VERSION ""

NS_ :

BS_:

BU_: FCM

BO_ 775 FCM_2: 8 FCM
 SG_ HMA_Status : 2|3@0+ (1,0) [0|7] ""  Vector__XXX
 SG_ HMA_HighbeamReq : 3|1@0+ (1,0) [0|1] ""  Vector__XXX
 SG_ FCM_2_Resd1 : 5|2@0+ (1,0) [0|1] ""  Vector__XXX
 SG_ LDW_ELK_TJA_LDPLeftVisuali : 7|2@0+ (1,0) [0|3] ""  Vector__XXX
 SG_ LDW_ELK_TJA_LDPRightVisuali : 15|2@0+ (1,0) [0|3] ""  Vector__XXX
 SG_ FCM_2_ISAState : 13|3@0+ (1,0) [0|7] ""  Vector__XXX
 SG_ FCM_2_Resd3 : 10|2@0+ (1,0) [0|1] ""  Vector__XXX
 SG_ FCM_2_Resd4 : 8|2@0+ (1,0) [0|1] ""  Vector__XXX
 SG_ FCM_2_SCFSpdlimWarn : 22|1@0+ (1,0) [0|1] ""  Vector__XXX
 SG_ SLAState : 21|3@0+ (1,0) [0|7] ""  Vector__XXX
 SG_ SLASpdlimit : 18|8@0+ (1,0) [0|255] ""  Vector__XXX
 SG_ FCM_2_Resd6 : 26|2@0+ (1,0) [0|1] ""  Vector__XXX
 SG_ SLASpdlimitWarning : 24|1@0+ (1,0) [0|1] ""  Vector__XXX
 SG_ Camera_textinfo : 39|2@0+ (1,0) [0|3] ""  Vector__XXX
 SG_ FCM_2_Resd13 : 37|1@0+ (1,0) [0|1] ""  Vector__XXX
 SG_ FCM_2_SpdLimtyp : 36|2@0+ (1,0) [0|3] ""  Vector__XXX
 SG_ FCM_2_Resd8 : 34|3@0+ (1,0) [0|1] ""  Vector__XXX
 SG_ TJA_ICA_mode : 47|3@0+ (1,0) [0|4] ""  Vector__XXX
 SG_ FCM_2_SLASpdLimChgAud : 44|1@0+ (1,0) [0|1] ""  Vector__XXX
 SG_ FCM_2_SLASpdlimitUnits : 41|2@0+ (1,0) [0|3] ""  Vector__XXX
 SG_ FCM_2_TJATakeoverReq : 43|2@0+ (1,0) [0|3] ""  Vector__XXX
 SG_ SLASpdlimitUnknownWarning : 53|2@0+ (1,0) [0|3] ""  Vector__XXX
 SG_ SLASpdlimitWarningVis : 54|1@0+ (1,0) [0|1] ""  Vector__XXX
 SG_ SLASpdlimitWarningAud : 55|1@0+ (1,0) [0|1] ""  Vector__XXX
 SG_ FCM_2_MessageCounter : 51|4@0+ (1,0) [0|15] ""  Vector__XXX
 SG_ FCM_2_CRC : 63|8@0+ (1,0) [0|255] ""  Vector__XXX

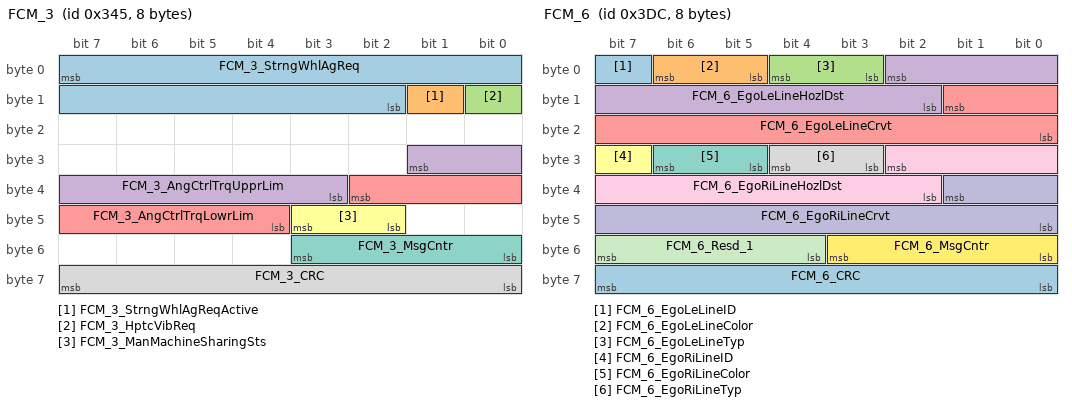
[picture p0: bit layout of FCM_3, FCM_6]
BO_ 837 FCM_3: 8 FCM
 SG_ FCM_3_StrngWhlAgReq : 7|14@0+ (0.1,-780) [-780|780] "deg"  Vector__XXX
 SG_ FCM_3_StrngWhlAgReqActive : 9|1@0+ (1,0) [0|1] ""  Vector__XXX
 SG_ FCM_3_HptcVibReq : 8|1@0+ (1,0) [0|1] ""  Vector__XXX
 SG_ FCM_3_AngCtrlTrqUpprLim : 25|7@0+ (0.1,0) [0|10] "NM"  Vector__XXX
 SG_ FCM_3_AngCtrlTrqLowrLim : 34|7@0+ (0.1,-10) [-10|0] "NM"  Vector__XXX
 SG_ FCM_3_ManMachineSharingSts : 43|2@0+ (1,0) [0|3] ""  Vector__XXX
 SG_ FCM_3_MsgCntr : 51|4@0+ (1,0) [0|15] ""  Vector__XXX
 SG_ FCM_3_CRC : 63|8@0+ (1,0) [0|255] ""  Vector__XXX

BO_ 1245 FCM_5: 8 FCM
 SG_ FCM_5_TJAICAExitTextInfoSts : 7|2@0+ (1,0) [0|3] ""  Vector__XXX
 SG_ FCM_5_SLAONOFFSts : 5|2@0+ (1,0) [0|3] ""  Vector__XXX
 SG_ FCM_5_IESONOFFSts : 3|2@0+ (1,0) [0|3] ""  Vector__XXX
 SG_ FCM_5_HMAONOFFSts : 1|2@0+ (1,0) [0|3] ""  Vector__XXX
 SG_ FCM_5_TSIONOFFSts : 15|2@0+ (1,0) [0|3] ""  Vector__XXX
 SG_ FCM_5_TLIONOFFSts : 13|2@0+ (1,0) [0|3] ""  Vector__XXX
 SG_ FCM_5_LDWONOFFSts : 11|2@0+ (1,0) [0|3] ""  Vector__XXX
 SG_ FCM_5_WarnModSts : 9|2@0+ (1,0) [0|3] ""  Vector__XXX
 SG_ FCM_5_LDPONOFFSts : 23|2@0+ (1,0) [0|3] ""  Vector__XXX
 SG_ FCM_5_LDWLDPSnvtySts : 21|2@0+ (1,0) [0|3] ""  Vector__XXX
 SG_ FCM_5_ELKONOFFSts : 19|2@0+ (1,0) [0|3] ""  Vector__XXX
 SG_ SLWFONOFFSts : 17|2@0+ (1,0) [0|3] ""  Vector__XXX
 SG_ SLASpdlimitWarningAudSWSts : 31|2@0+ (1,0) [0|3] ""  Vector__XXX
 SG_ SLASpdLimChgAudSwSts : 29|2@0+ (1,0) [0|3] ""  Vector__XXX
 SG_ FCM_5_SpeedLmtNmberAb : 27|6@0+ (1,0) [0|63] ""  Vector__XXX
 SG_ FCM_5_SpeedLmtNmberE : 37|6@0+ (1,0) [0|63] ""  Vector__XXX
 SG_ FCM_5_SLAmodeSWSet : 47|2@0+ (1,0) [0|3] ""  Vector__XXX
 SG_ FCM_5_Resd_1 : 45|10@0+ (1,0) [0|0] ""  Vector__XXX
 SG_ FCM_5_MsgCntr : 51|4@0+ (1,0) [0|15] ""  Vector__XXX
 SG_ FCM_5_CRC : 63|8@0+ (1,0) [0|255] ""  Vector__XXX

BO_ 988 FCM_6: 8 FCM
 SG_ FCM_6_EgoLeLineID : 7|1@0+ (1,0) [0|1] ""  Vector__XXX
 SG_ FCM_6_EgoLeLineColor : 6|2@0+ (1,0) [0|3] ""  Vector__XXX
 SG_ FCM_6_EgoLeLineTyp : 4|2@0+ (1,0) [0|3] ""  Vector__XXX
 SG_ FCM_6_EgoLeLineHozlDst : 2|9@0+ (0.1,-25) [-25|25] "m"  Vector__XXX
 SG_ FCM_6_EgoLeLineCrvt : 9|10@0+ (0.00006,-0.0156) [-0.0156|0.0156] "1/m"  Vector__XXX
 SG_ FCM_6_EgoRiLineID : 31|1@0+ (1,0) [0|1] ""  Vector__XXX
 SG_ FCM_6_EgoRiLineColor : 30|2@0+ (1,0) [0|3] ""  Vector__XXX
 SG_ FCM_6_EgoRiLineTyp : 28|2@0+ (1,0) [0|3] ""  Vector__XXX
 SG_ FCM_6_EgoRiLineHozlDst : 26|9@0+ (0.1,-25) [-25|25] "m"  Vector__XXX
 SG_ FCM_6_EgoRiLineCrvt : 33|10@0+ (0.00006,-0.0156) [-0.0156|0.0156] "1/m"  Vector__XXX
 SG_ FCM_6_Resd_1 : 55|4@0+ (1,0) [0|1] ""  Vector__XXX
 SG_ FCM_6_MsgCntr : 51|4@0+ (1,0) [0|15] ""  Vector__XXX
 SG_ FCM_6_CRC : 63|8@0+ (1,0) [0|255] ""  Vector__XXX

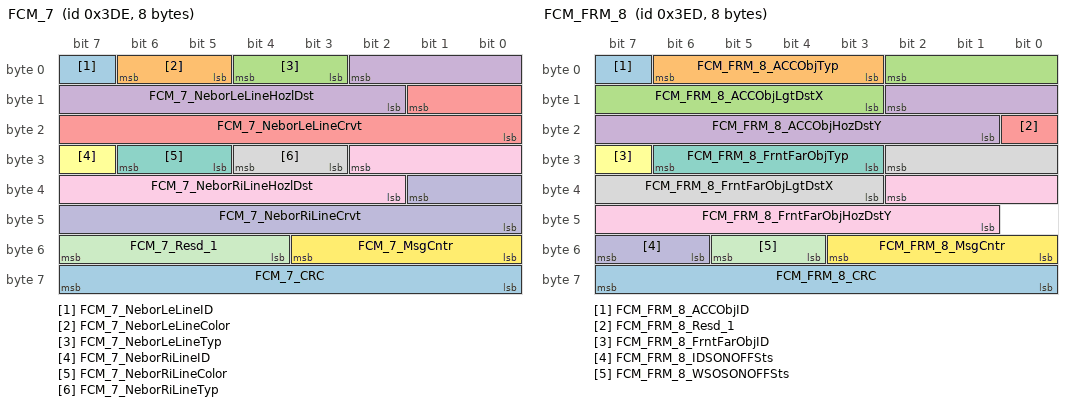
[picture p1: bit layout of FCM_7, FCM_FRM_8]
BO_ 990 FCM_7: 8 FCM
 SG_ FCM_7_NeborLeLineID : 7|1@0+ (1,0) [0|1] ""  Vector__XXX
 SG_ FCM_7_NeborLeLineColor : 6|2@0+ (1,0) [0|3] ""  Vector__XXX
 SG_ FCM_7_NeborLeLineTyp : 4|2@0+ (1,0) [0|3] ""  Vector__XXX
 SG_ FCM_7_NeborLeLineHozlDst : 2|9@0+ (0.1,-25) [-25|25] "m"  Vector__XXX
 SG_ FCM_7_NeborLeLineCrvt : 9|10@0+ (0.00006,-0.0156) [-0.0156|0.0156] "1/m"  Vector__XXX
 SG_ FCM_7_NeborRiLineID : 31|1@0+ (1,0) [0|1] ""  Vector__XXX
 SG_ FCM_7_NeborRiLineColor : 30|2@0+ (1,0) [0|3] ""  Vector__XXX
 SG_ FCM_7_NeborRiLineTyp : 28|2@0+ (1,0) [0|3] ""  Vector__XXX
 SG_ FCM_7_NeborRiLineHozlDst : 26|9@0+ (0.1,-25) [-25|25] "m"  Vector__XXX
 SG_ FCM_7_NeborRiLineCrvt : 33|10@0+ (0.00006,-0.0156) [-0.0156|0.0156] "1/m"  Vector__XXX
 SG_ FCM_7_Resd_1 : 55|4@0+ (1,0) [0|1] ""  Vector__XXX
 SG_ FCM_7_MsgCntr : 51|4@0+ (1,0) [0|15] ""  Vector__XXX
 SG_ FCM_7_CRC : 63|8@0+ (1,0) [0|255] ""  Vector__XXX

BO_ 1005 FCM_FRM_8: 8 FCM
 SG_ FCM_FRM_8_ACCObjID : 7|1@0+ (1,0) [0|1] ""  Vector__XXX
 SG_ FCM_FRM_8_ACCObjTyp : 6|4@0+ (1,0) [0|15] ""  Vector__XXX
 SG_ FCM_FRM_8_ACCObjLgtDstX : 2|8@0+ (0.5,0) [0|127] "m"  Vector__XXX
 SG_ FCM_FRM_8_ACCObjHozDstY : 10|10@0+ (0.1,-50) [-50|50] "m"  Vector__XXX
 SG_ FCM_FRM_8_Resd_1 : 16|1@0+ (1,0) [0|1] ""  Vector__XXX
 SG_ FCM_FRM_8_FrntFarObjID : 31|1@0+ (1,0) [0|1] ""  Vector__XXX
 SG_ FCM_FRM_8_FrntFarObjTyp : 30|4@0+ (1,0) [0|15] ""  Vector__XXX
 SG_ FCM_FRM_8_FrntFarObjLgtDstX : 26|8@0+ (0.5,0) [0|127] "m"  Vector__XXX
 SG_ FCM_FRM_8_FrntFarObjHozDstY : 34|10@0+ (0.1,-50) [-50|50] "m"  Vector__XXX
 SG_ FCM_FRM_8_IDSONOFFSts : 55|2@0+ (1,0) [0|3] ""  Vector__XXX
 SG_ FCM_FRM_8_WSOSONOFFSts : 53|2@0+ (1,0) [0|3] ""  Vector__XXX
 SG_ FCM_FRM_8_MsgCntr : 51|4@0+ (1,0) [0|15] ""  Vector__XXX
 SG_ FCM_FRM_8_CRC : 63|8@0+ (1,0) [0|255] ""  Vector__XXX

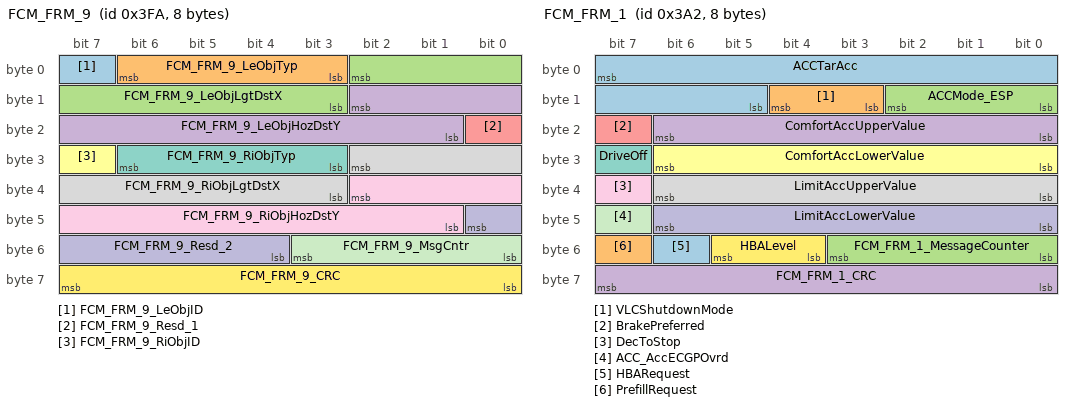
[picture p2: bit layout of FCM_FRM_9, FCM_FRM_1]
BO_ 1018 FCM_FRM_9: 8 FCM
 SG_ FCM_FRM_9_LeObjID : 7|1@0+ (1,0) [0|1] ""  Vector__XXX
 SG_ FCM_FRM_9_LeObjTyp : 6|4@0+ (1,0) [0|15] ""  Vector__XXX
 SG_ FCM_FRM_9_LeObjLgtDstX : 2|8@0+ (0.5,0) [0|127] "m"  Vector__XXX
 SG_ FCM_FRM_9_LeObjHozDstY : 10|10@0+ (0.1,-50) [-50|50] "m"  Vector__XXX
 SG_ FCM_FRM_9_Resd_1 : 16|1@0+ (1,0) [0|1] ""  Vector__XXX
 SG_ FCM_FRM_9_RiObjID : 31|1@0+ (1,0) [0|1] ""  Vector__XXX
 SG_ FCM_FRM_9_RiObjTyp : 30|4@0+ (1,0) [0|15] ""  Vector__XXX
 SG_ FCM_FRM_9_RiObjLgtDstX : 26|8@0+ (0.5,0) [0|127] "m"  Vector__XXX
 SG_ FCM_FRM_9_RiObjHozDstY : 34|10@0+ (0.1,-50) [-50|50] "m"  Vector__XXX
 SG_ FCM_FRM_9_Resd_2 : 40|5@0+ (1,0) [0|1] ""  Vector__XXX
 SG_ FCM_FRM_9_MsgCntr : 51|4@0+ (1,0) [0|15] ""  Vector__XXX
 SG_ FCM_FRM_9_CRC : 63|8@0+ (1,0) [0|255] ""  Vector__XXX

BO_ 1020 FCM_10: 8 FCM
 SG_ FCM_10_TSISysSts : 7|2@0+ (1,0) [0|3] ""  Vector__XXX
 SG_ FCM_10_TLISysSts : 5|2@0+ (1,0) [0|3] ""  Vector__XXX
 SG_ FCM_10_TSISgnGiWay : 3|4@0+ (1,0) [0|15] ""  Vector__XXX
 SG_ FCM_10_TSISgnForb : 15|4@0+ (1,0) [0|15] ""  Vector__XXX
 SG_ FCM_10_TSISgnLongStayDisp : 11|4@0+ (1,0) [0|15] ""  Vector__XXX
 SG_ FCM_10_TLITrfcLi : 23|2@0+ (1,0) [0|3] ""  Vector__XXX
 SG_ FCM_10_LDPSysSts : 21|3@0+ (1,0) [0|7] ""  Vector__XXX
 SG_ FCM_10_LDWSysSts : 18|3@0+ (1,0) [0|7] ""  Vector__XXX
 SG_ FCM_10_ELKSysSts : 31|3@0+ (1,0) [0|7] ""  Vector__XXX
 SG_ FCM_10_TSINoParkWarn : 28|1@0+ (1,0) [0|1] ""  Vector__XXX
 SG_ FCM_10_TJAICATextinfo : 27|3@0+ (1,0) [0|7] ""  Vector__XXX
 SG_ FCM_10_TJAICAEnaRcmend : 24|1@0+ (1,0) [0|1] ""  Vector__XXX
 SG_ FCM_10_LDPTJAELKTakeoverReq : 39|2@0+ (1,0) [0|3] ""  Vector__XXX
 SG_ FCM_10_TJAICAExitTextInfoSts : 37|2@0+ (1,0) [0|3] ""  Vector__XXX
 SG_ FCM_10_SLAONOFFSts : 35|2@0+ (1,0) [0|3] ""  Vector__XXX
 SG_ FCM_10_WarnModSts : 33|2@0+ (1,0) [0|3] ""  Vector__XXX
 SG_ FCM_10_ELKIntvMod : 47|3@0+ (1,0) [0|7] ""  Vector__XXX
 SG_ FCM_10_EgoLeftLineHeatgAg : 44|9@0+ (0.004,-1.02) [-1.02|1.02] "Rad"  Vector__XXX
 SG_ FCM_10_MsgCntr : 51|4@0+ (1,0) [0|15] ""  Vector__XXX
 SG_ FCM_10_CRC : 63|8@0+ (1,0) [0|255] ""  Vector__XXX

BO_ 930 FCM_FRM_1: 8 FCM
 SG_ ACCTarAcc : 7|11@0+ (0.005,-5) [-5|5.235] "m/s2"  Vector__XXX
 SG_ VLCShutdownMode : 12|2@0+ (1,0) [0|3] ""  Vector__XXX
 SG_ ACCMode_ESP : 10|3@0+ (1,0) [0|7] ""  Vector__XXX
 SG_ ComfortAccUpperValue : 22|7@0+ (0.025,0) [0|3.125] "m/s2"  Vector__XXX
 SG_ BrakePreferred : 23|1@0+ (1,0) [0|1] ""  Vector__XXX
 SG_ ComfortAccLowerValue : 30|7@0+ (0.025,0) [0|3.125] "m/s2"  Vector__XXX
 SG_ DriveOff : 31|1@0+ (1,0) [0|1] ""  Vector__XXX
 SG_ LimitAccUpperValue : 38|7@0+ (0.1,0) [0|12.7] "m/s3"  Vector__XXX
 SG_ DecToStop : 39|1@0+ (1,0) [0|1] ""  Vector__XXX
 SG_ LimitAccLowerValue : 46|7@0+ (0.1,-12.7) [-12.7|0] "m/s3"  Vector__XXX
 SG_ ACC_AccECGPOvrd : 47|1@0+ (1,0) [0|1] ""  Vector__XXX
 SG_ HBALevel : 53|2@0+ (1,0) [0|3] ""  Vector__XXX
 SG_ HBARequest : 54|1@0+ (1,0) [0|1] ""  Vector__XXX
 SG_ PrefillRequest : 55|1@0+ (1,0) [0|1] ""  Vector__XXX
 SG_ FCM_FRM_1_MessageCounter : 51|4@0+ (1,0) [0|15] ""  Vector__XXX
 SG_ FCM_FRM_1_CRC : 63|8@0+ (1,0) [0|255] ""  Vector__XXX

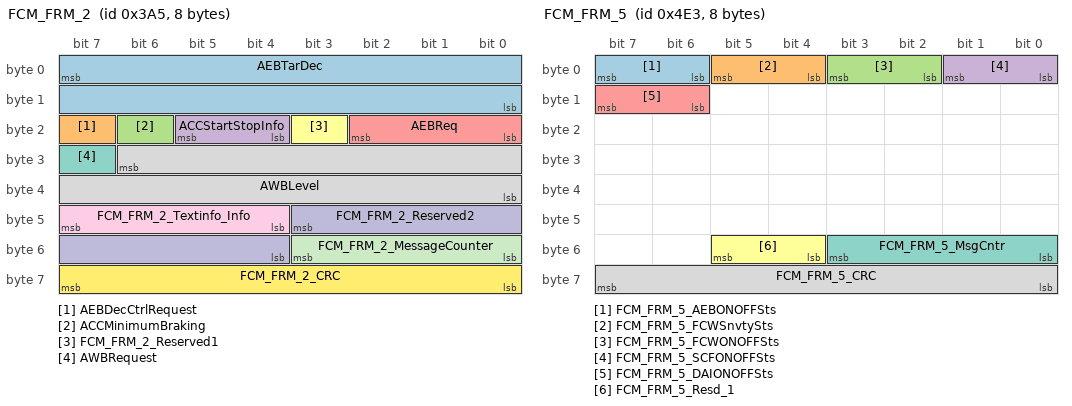
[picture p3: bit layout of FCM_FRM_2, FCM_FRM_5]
BO_ 933 FCM_FRM_2: 8 FCM
 SG_ AEBTarDec : 7|16@0+ (0.0004882,-16) [-16|15] ""  Vector__XXX
 SG_ AEBDecCtrlRequest : 23|1@0+ (1,0) [0|1] ""  Vector__XXX
 SG_ ACCMinimumBraking : 22|1@0+ (1,0) [0|1] ""  Vector__XXX
 SG_ ACCStartStopInfo : 21|2@0+ (1,0) [0|3] ""  Vector__XXX
 SG_ AEBReq : 18|3@0+ (1,0) [0|7] ""  Vector__XXX
 SG_ FCM_FRM_2_Reserved1 : 19|1@0+ (1,0) [0|1] ""  Vector__XXX
 SG_ AWBRequest : 31|1@0+ (1,0) [0|1] ""  Vector__XXX
 SG_ AWBLevel : 30|15@0+ (1,0) [0|15] ""  Vector__XXX
 SG_ FCM_FRM_2_Textinfo_Info : 47|4@0+ (1,0) [0|15] ""  Vector__XXX
 SG_ FCM_FRM_2_Reserved2 : 43|8@0+ (1,0) [0|1] ""  Vector__XXX
 SG_ FCM_FRM_2_MessageCounter : 51|4@0+ (1,0) [0|15] ""  Vector__XXX
 SG_ FCM_FRM_2_CRC : 63|8@0+ (1,0) [0|255] ""  Vector__XXX

BO_ 773 FCM_FRM_3: 8 FCM
 SG_ FCM_FRM_3_Resd1 : 7|9@0+ (1,0) [0|1] ""  Vector__XXX
 SG_ FCM_FRM_3_Resd2 : 14|3@0+ (1,0) [0|1] ""  Vector__XXX
 SG_ FCM_FRM_3_Resd3 : 11|3@0+ (1,0) [0|1] ""  Vector__XXX
 SG_ FCM_FRM_3_Resd4 : 8|1@0+ (1,0) [0|1] ""  Vector__XXX
 SG_ Textinfo : 23|5@0+ (1,0) [0|31] ""  Vector__XXX
 SG_ FCM_FRM_3_Resd6 : 18|1@0+ (1,0) [0|1] ""  Vector__XXX
 SG_ FCM_FRM_3_Resd7 : 31|2@0+ (1,0) [0|1] ""  Vector__XXX
 SG_ FCM_FRM_3_Resd8 : 17|2@0+ (1,0) [0|1] ""  Vector__XXX
 SG_ FCM_FRM_3_Resd9 : 29|8@0+ (1,0) [0|1] ""  Vector__XXX
 SG_ ACCModeDummy : 37|4@0+ (1,0) [0|15] ""  Vector__XXX
 SG_ FCM_FRM_3_Resd10 : 33|3@0+ (1,0) [0|1] ""  Vector__XXX
 SG_ FCM_FRM_3_Resd11 : 46|3@0+ (1,0) [0|1] ""  Vector__XXX
 SG_ FCM_FRM_3_Resd12 : 43|1@0+ (1,0) [0|1] ""  Vector__XXX
 SG_ FCM_FRM_3_Resd13 : 42|1@0+ (1,0) [0|1] ""  Vector__XXX
 SG_ FCM_FRM_3_Resd14 : 41|1@0+ (1,0) [0|1] ""  Vector__XXX
 SG_ FCM_FRM_3_Resd15 : 40|1@0+ (1,0) [0|1] ""  Vector__XXX
 SG_ FCM_FRM_3_Resd16 : 55|2@0+ (1,0) [0|1] ""  Vector__XXX
 SG_ FCM_FRM_3_Resd17 : 53|1@0+ (1,0) [0|1] ""  Vector__XXX
 SG_ FCM_FRM_3_Resd18 : 52|1@0+ (1,0) [0|1] ""  Vector__XXX
 SG_ FCM_FRM_3_MessageCounter : 51|4@0+ (1,0) [0|15] ""  Vector__XXX
 SG_ FCM_FRM_3_CRC : 63|8@0+ (1,0) [0|255] ""  Vector__XXX

BO_ 1251 FCM_FRM_5: 8 FCM
 SG_ FCM_FRM_5_AEBONOFFSts : 7|2@0+ (1,0) [0|3] ""  Vector__XXX
 SG_ FCM_FRM_5_FCWSnvtySts : 5|2@0+ (1,0) [0|3] ""  Vector__XXX
 SG_ FCM_FRM_5_FCWONOFFSts : 3|2@0+ (1,0) [0|3] ""  Vector__XXX
 SG_ FCM_FRM_5_SCFONOFFSts : 1|2@0+ (1,0) [0|3] ""  Vector__XXX
 SG_ FCM_FRM_5_DAIONOFFSts : 15|2@0+ (1,0) [0|3] ""  Vector__XXX
 SG_ FCM_FRM_5_Resd_1 : 53|2@0+ (1,0) [0|1] ""  Vector__XXX
 SG_ FCM_FRM_5_MsgCntr : 51|4@0+ (1,0) [0|15] ""  Vector__XXX
 SG_ FCM_FRM_5_CRC : 63|8@0+ (1,0) [0|255] ""  Vector__XXX

BO_ 903 FCM_FRM_6: 8 FCM
 SG_ FCM_FRM_6_Textinfo_Info : 7|4@0+ (1,0) [0|15] ""  Vector__XXX
 SG_ FCM_FRM_6_TextinfoWarn : 3|4@0+ (1,0) [0|15] ""  Vector__XXX
 SG_ FCM_FRM_6_Textinfo_Info_2 : 15|4@0+ (1,0) [0|15] ""  Vector__XXX
 SG_ FCM_FRM_6_TimeGapSetICM : 11|3@0+ (1,0) [0|7] ""  Vector__XXX
 SG_ FCM_FRM_6_SCF_PopoverReq : 8|1@0+ (1,0) [0|1] ""  Vector__XXX
 SG_ FCM_FRM_6_SCF_SpdLimSts : 23|3@0+ (1,0) [0|7] ""  Vector__XXX
 SG_ FCM_FRM_6_SCF_SpdLimUnit : 20|2@0+ (1,0) [0|3] ""  Vector__XXX
 SG_ FCM_FRM_6_DrvrCfmSCFDispFb : 18|1@0+ (1,0) [0|1] ""  Vector__XXX
 SG_ FCM_FRM_6_DistanceWarning : 17|1@0+ (1,0) [0|1] ""  Vector__XXX
 SG_ FCM_FRM_6_FCW_preWarning : 16|1@0+ (1,0) [0|1] ""  Vector__XXX
 SG_ FCM_FRM_6_TakeOverReq : 31|1@0+ (1,0) [0|1] ""  Vector__XXX
 SG_ FCM_FRM_6_FCWMode : 30|3@0+ (1,0) [0|4] ""  Vector__XXX
 SG_ FCM_FRM_6_AEBMode : 27|3@0+ (1,0) [0|4] ""  Vector__XXX
 SG_ FCM_FRM_6_AEBDecCtrlRequest : 24|1@0+ (1,0) [0|1] ""  Vector__XXX
 SG_ FCM_FRM_6_HMI_Indicator : 39|2@0+ (1,0) [0|3] ""  Vector__XXX
 SG_ FCM_FRM_6_ACCMode : 37|4@0+ (1,0) [0|15] ""  Vector__XXX
 SG_ FCM_FRM_6_SCF_Indicator : 33|2@0+ (1,0) [0|3] ""  Vector__XXX
 SG_ FCM_FRM_6_VSetDis : 44|9@0+ (0.5,0) [0|255.5] "KPH"  Vector__XXX
 SG_ FCM_FRM_6_MsgCntr : 51|4@0+ (1,0) [0|15] ""  Vector__XXX
 SG_ FCM_FRM_6_CRC : 63|8@0+ (1,0) [0|255] ""  Vector__XXX

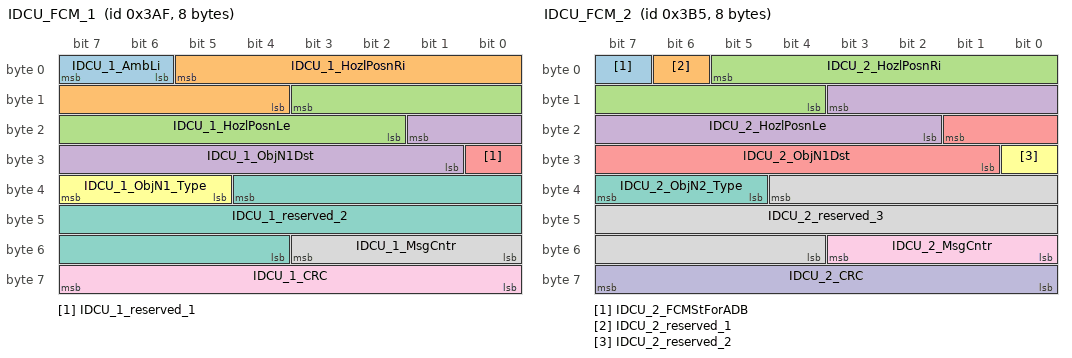
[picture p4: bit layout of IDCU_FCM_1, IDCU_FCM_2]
BO_ 943 IDCU_FCM_1: 8 FCM
 SG_ IDCU_1_AmbLi : 7|2@0+ (1,0) [0|3] ""  Vector__XXX
 SG_ IDCU_1_HozlPosnRi : 5|10@0+ (0.05,-21.5) [-21.5|21.5] "°"  Vector__XXX
 SG_ IDCU_1_HozlPosnLe : 11|10@0+ (0.05,-21.5) [-21.5|21.5] "°"  Vector__XXX
 SG_ IDCU_1_ObjN1Dst : 17|9@0+ (1,0) [0|400] "m"  Vector__XXX
 SG_ IDCU_1_reserved_1 : 24|1@0+ (1,0) [0|1] ""  Vector__XXX
 SG_ IDCU_1_ObjN1_Type : 39|3@0+ (1,0) [0|7] ""  Vector__XXX
 SG_ IDCU_1_reserved_2 : 36|17@0+ (1,0) [0|1] ""  Vector__XXX
 SG_ IDCU_1_MsgCntr : 51|4@0+ (1,0) [0|15] ""  Vector__XXX
 SG_ IDCU_1_CRC : 63|8@0+ (1,0) [0|255] ""  Vector__XXX

BO_ 949 IDCU_FCM_2: 8 FCM
 SG_ IDCU_2_FCMStForADB : 7|1@0+ (1,0) [0|1] ""  Vector__XXX
 SG_ IDCU_2_reserved_1 : 6|1@0+ (1,0) [0|1] ""  Vector__XXX
 SG_ IDCU_2_HozlPosnRi : 5|10@0+ (0.05,-21.5) [-21.5|21.5] "°"  Vector__XXX
 SG_ IDCU_2_HozlPosnLe : 11|10@0+ (0.05,-21.5) [-21.5|21.5] "°"  Vector__XXX
 SG_ IDCU_2_ObjN1Dst : 17|9@0+ (1,0) [0|400] "m"  Vector__XXX
 SG_ IDCU_2_reserved_2 : 24|1@0+ (1,0) [0|1] ""  Vector__XXX
 SG_ IDCU_2_ObjN2_Type : 39|3@0+ (1,0) [0|0] ""  Vector__XXX
 SG_ IDCU_2_reserved_3 : 36|17@0+ (1,0) [0|0] ""  Vector__XXX
 SG_ IDCU_2_MsgCntr : 51|4@0+ (1,0) [0|15] ""  Vector__XXX
 SG_ IDCU_2_CRC : 63|8@0+ (1,0) [0|255] ""  Vector__XXX

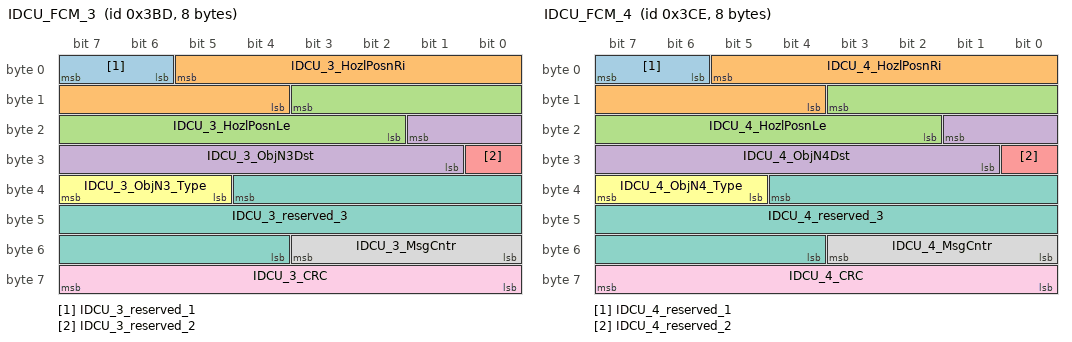
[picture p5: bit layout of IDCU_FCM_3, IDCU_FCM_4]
BO_ 957 IDCU_FCM_3: 8 FCM
 SG_ IDCU_3_reserved_1 : 7|2@0+ (1,0) [0|3] ""  Vector__XXX
 SG_ IDCU_3_HozlPosnRi : 5|10@0+ (0.05,-21.5) [-21.5|21.5] "°"  Vector__XXX
 SG_ IDCU_3_HozlPosnLe : 11|10@0+ (0.05,-21.5) [-21.5|21.5] "°"  Vector__XXX
 SG_ IDCU_3_ObjN3Dst : 17|9@0+ (1,0) [0|400] "m"  Vector__XXX
 SG_ IDCU_3_reserved_2 : 24|1@0+ (1,0) [0|1] ""  Vector__XXX
 SG_ IDCU_3_ObjN3_Type : 39|3@0+ (1,0) [0|7] ""  Vector__XXX
 SG_ IDCU_3_reserved_3 : 36|17@0+ (1,0) [0|0] ""  Vector__XXX
 SG_ IDCU_3_MsgCntr : 51|4@0+ (1,0) [0|15] ""  Vector__XXX
 SG_ IDCU_3_CRC : 63|8@0+ (1,0) [0|255] ""  Vector__XXX

BO_ 974 IDCU_FCM_4: 8 FCM
 SG_ IDCU_4_reserved_1 : 7|2@0+ (1,0) [0|3] ""  Vector__XXX
 SG_ IDCU_4_HozlPosnRi : 5|10@0+ (0.05,-21.5) [-21.5|21.5] "°"  Vector__XXX
 SG_ IDCU_4_HozlPosnLe : 11|10@0+ (0.05,-21.5) [-21.5|21.5] "°"  Vector__XXX
 SG_ IDCU_4_ObjN4Dst : 17|9@0+ (1,0) [0|400] "m"  Vector__XXX
 SG_ IDCU_4_reserved_2 : 24|1@0+ (1,0) [0|1] ""  Vector__XXX
 SG_ IDCU_4_ObjN4_Type : 39|3@0+ (1,0) [0|7] ""  Vector__XXX
 SG_ IDCU_4_reserved_3 : 36|17@0+ (1,0) [0|0] ""  Vector__XXX
 SG_ IDCU_4_MsgCntr : 51|4@0+ (1,0) [0|15] ""  Vector__XXX
 SG_ IDCU_4_CRC : 63|8@0+ (1,0) [0|255] ""  Vector__XXX

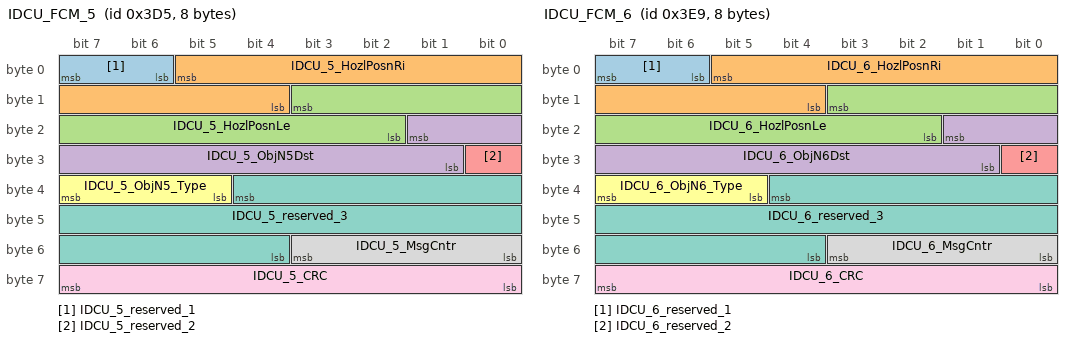
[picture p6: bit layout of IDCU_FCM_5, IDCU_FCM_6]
BO_ 981 IDCU_FCM_5: 8 FCM
 SG_ IDCU_5_reserved_1 : 7|2@0+ (1,0) [0|1] ""  Vector__XXX
 SG_ IDCU_5_HozlPosnRi : 5|10@0+ (0.05,-21.5) [-21.5|21.5] "°"  Vector__XXX
 SG_ IDCU_5_HozlPosnLe : 11|10@0+ (0.05,-21.5) [-21.5|21.5] "°"  Vector__XXX
 SG_ IDCU_5_ObjN5Dst : 17|9@0+ (1,0) [0|400] "m"  Vector__XXX
 SG_ IDCU_5_reserved_2 : 24|1@0+ (1,0) [0|1] ""  Vector__XXX
 SG_ IDCU_5_ObjN5_Type : 39|3@0+ (1,0) [0|7] ""  Vector__XXX
 SG_ IDCU_5_reserved_3 : 36|17@0+ (1,0) [0|0] ""  Vector__XXX
 SG_ IDCU_5_MsgCntr : 51|4@0+ (1,0) [0|15] ""  Vector__XXX
 SG_ IDCU_5_CRC : 63|8@0+ (1,0) [0|255] ""  Vector__XXX

BO_ 1001 IDCU_FCM_6: 8 FCM
 SG_ IDCU_6_reserved_1 : 7|2@0+ (1,0) [0|1] ""  Vector__XXX
 SG_ IDCU_6_HozlPosnRi : 5|10@0+ (0.05,-21.5) [-21.5|21.5] "°"  Vector__XXX
 SG_ IDCU_6_HozlPosnLe : 11|10@0+ (0.05,-21.5) [-21.5|21.5] "°"  Vector__XXX
 SG_ IDCU_6_ObjN6Dst : 17|9@0+ (1,0) [0|400] "m"  Vector__XXX
 SG_ IDCU_6_reserved_2 : 24|1@0+ (1,0) [0|1] ""  Vector__XXX
 SG_ IDCU_6_ObjN6_Type : 39|3@0+ (1,0) [0|7] ""  Vector__XXX
 SG_ IDCU_6_reserved_3 : 36|17@0+ (1,0) [0|0] ""  Vector__XXX
 SG_ IDCU_6_MsgCntr : 51|4@0+ (1,0) [0|15] ""  Vector__XXX
 SG_ IDCU_6_CRC : 63|8@0+ (1,0) [0|255] ""  Vector__XXX

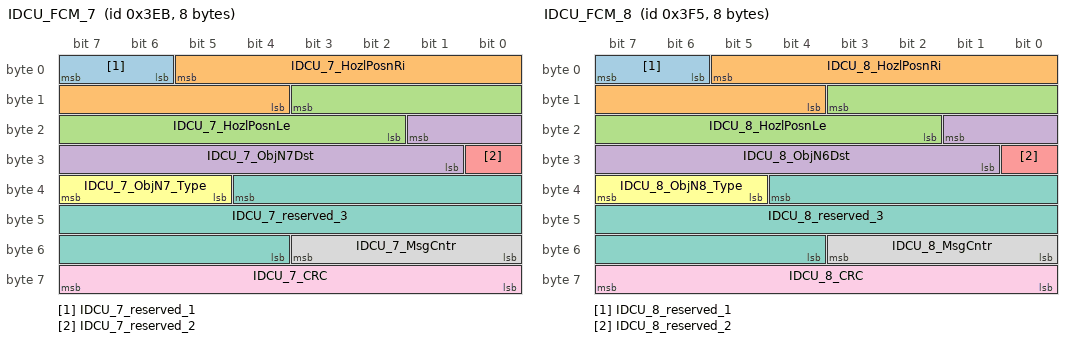
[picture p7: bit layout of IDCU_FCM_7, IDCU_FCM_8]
BO_ 1003 IDCU_FCM_7: 8 FCM
 SG_ IDCU_7_reserved_1 : 7|2@0+ (1,0) [0|1] ""  Vector__XXX
 SG_ IDCU_7_HozlPosnRi : 5|10@0+ (0.05,-21.5) [-21.5|21.5] "°"  Vector__XXX
 SG_ IDCU_7_HozlPosnLe : 11|10@0+ (0.05,-21.5) [-21.5|21.5] "°"  Vector__XXX
 SG_ IDCU_7_ObjN7Dst : 17|9@0+ (1,0) [0|400] "m"  Vector__XXX
 SG_ IDCU_7_reserved_2 : 24|1@0+ (1,0) [0|1] ""  Vector__XXX
 SG_ IDCU_7_ObjN7_Type : 39|3@0+ (1,0) [0|7] ""  Vector__XXX
 SG_ IDCU_7_reserved_3 : 36|17@0+ (1,0) [0|0] ""  Vector__XXX
 SG_ IDCU_7_MsgCntr : 51|4@0+ (1,0) [0|15] ""  Vector__XXX
 SG_ IDCU_7_CRC : 63|8@0+ (1,0) [0|255] ""  Vector__XXX

BO_ 1013 IDCU_FCM_8: 8 FCM
 SG_ IDCU_8_reserved_1 : 7|2@0+ (1,0) [0|1] ""  Vector__XXX
 SG_ IDCU_8_HozlPosnRi : 5|10@0+ (0.05,-21.5) [-21.5|21.5] "°"  Vector__XXX
 SG_ IDCU_8_HozlPosnLe : 11|10@0+ (0.05,-21.5) [-21.5|21.5] "°"  Vector__XXX
 SG_ IDCU_8_ObjN6Dst : 17|9@0+ (1,0) [0|400] "m"  Vector__XXX
 SG_ IDCU_8_reserved_2 : 24|1@0+ (1,0) [0|1] ""  Vector__XXX
 SG_ IDCU_8_ObjN8_Type : 39|3@0+ (1,0) [0|7] ""  Vector__XXX
 SG_ IDCU_8_reserved_3 : 36|17@0+ (1,0) [0|0] ""  Vector__XXX
 SG_ IDCU_8_MsgCntr : 51|4@0+ (1,0) [0|15] ""  Vector__XXX
 SG_ IDCU_8_CRC : 63|8@0+ (1,0) [0|255] ""  Vector__XXX

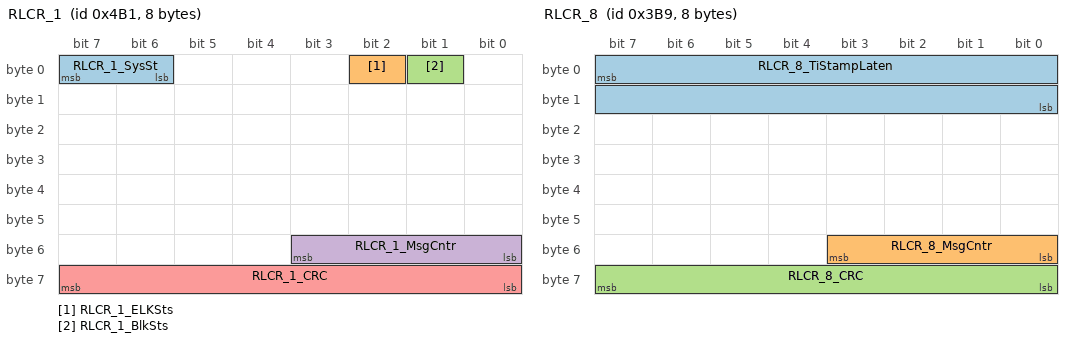
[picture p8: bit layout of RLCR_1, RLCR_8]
BO_ 1201 RLCR_1: 8 Vector__XXX
 SG_ RLCR_1_SysSt : 7|2@0+ (1,0) [0|3] ""  FCM
 SG_ RLCR_1_ELKSts : 2|1@0+ (1,0) [0|1] ""  FCM
 SG_ RLCR_1_BlkSts : 1|1@0+ (1,0) [0|1] ""  FCM
 SG_ RLCR_1_MsgCntr : 51|4@0+ (1,0) [0|15] ""  FCM
 SG_ RLCR_1_CRC : 63|8@0+ (1,0) [0|255] ""  FCM

BO_ 935 RLCR_3: 24 Vector__XXX
 SG_ RLCR_3_Le1ObjBoxLen : 7|9@0+ (0.1,0) [0|50] "m"  FCM
 SG_ RLCR_3_Le1ObjBoxWidth : 14|9@0+ (0.1,0) [0|50] "m"  FCM
 SG_ RLCR_3_Le1HdTo : 21|12@0+ (0.1,-180) [-180|180] "deg"  FCM
 SG_ RLCR_3_Le1ObjID : 25|8@0+ (1,0) [0|255] ""  FCM
 SG_ RLCR_3_Le1ObjCoordY : 33|13@0+ (0.05,-200) [-200|200] "m"  FCM
 SG_ RLCR_3_Le1ObjCoordX : 52|13@0+ (0.05,-200) [-200|200] "m"  FCM
 SG_ RLCR_3_Le1ObjXDirAV : 71|8@0+ (0.1,-12.8) [-12.8|12.7] "m/s2"  FCM
 SG_ RLCR_3_Le1ObjYDirV : 79|14@0+ (0.02,-128) [-128|128] "m/s"  FCM
 SG_ RLCR_3_Le1ObjXDirV : 81|14@0+ (0.02,-128) [-128|128] "m/s"  FCM
 SG_ RLCR_3_Le1ObjMtnChartc : 99|2@0+ (1,0) [0|3] ""  FCM
 SG_ RLCR_3_Le1ObjTyp : 97|2@0+ (1,0) [0|3] ""  FCM
 SG_ RLCR_3_Le1ObjConf : 111|1@0+ (1,0) [0|1] ""  FCM
 SG_ RLCR_3_Le1ObjNrOffocst : 110|5@0+ (1,0) [0|31] ""  FCM
 SG_ RLCR_3_Le1ObjTrackSt : 105|2@0+ (1,0) [0|3] ""  FCM
 SG_ RLCR_3_Le1ObjCoordXDstStdDe : 119|8@0+ (0.05,0) [0|12.7] ""  FCM
 SG_ RLCR_3_Le1ObjCoordYDstStdDe : 127|8@0+ (0.05,0) [0|12.7] ""  FCM
 SG_ RLCR_3_Le1ObjXDirVStdDe : 135|6@0+ (0.05,0) [0|2] ""  FCM
 SG_ RLCR_3_Le1ObjYDirVStdDe : 129|6@0+ (0.05,0) [0|2] ""  FCM
 SG_ RLCR_3_MsgCntr : 179|4@0+ (1,0) [0|15] ""  FCM
 SG_ RLCR_3_CRC : 191|8@0+ (1,0) [0|255] ""  FCM

BO_ 937 RLCR_4: 24 Vector__XXX
 SG_ RLCR_4_Le2ObjBoxLen : 7|9@0+ (0.1,0) [0|50] "m"  FCM
 SG_ RLCR_4_Le2ObjBoxWidth : 14|9@0+ (0.1,0) [0|50] "m"  FCM
 SG_ RLCR_4_Le2HdTo : 21|12@0+ (0.1,-180) [-180|180] "deg"  FCM
 SG_ RLCR_4_Le2ObjID : 25|8@0+ (1,0) [0|255] ""  FCM
 SG_ RLCR_4_Le2ObjCoordY : 33|13@0+ (0.05,-200) [-200|200] "m"  FCM
 SG_ RLCR_4_Le2ObjCoordX : 52|13@0+ (0.05,-200) [-200|200] "m"  FCM
 SG_ RLCR_4_Le2ObjXDirAV : 71|8@0+ (0.1,-12.8) [-12.8|12.7] "m/s2"  FCM
 SG_ RLCR_4_Le2ObjYDirV : 79|14@0+ (0.02,-128) [-128|128] "m/s"  FCM
 SG_ RLCR_4_Le2ObjXDirV : 81|14@0+ (0.02,-128) [-128|128] "m/s"  FCM
 SG_ RLCR_4_Le2ObjMtnChartc : 99|2@0+ (1,0) [0|3] ""  FCM
 SG_ RLCR_4_Le2ObjTyp : 97|2@0+ (1,0) [0|3] ""  FCM
 SG_ RLCR_4_Le2ObjConf : 111|1@0+ (1,0) [0|1] ""  FCM
 SG_ RLCR_4_Le2ObjNrOffocst : 110|5@0+ (1,0) [0|31] ""  FCM
 SG_ RLCR_4_Le2ObjTrackSt : 105|2@0+ (1,0) [0|3] ""  FCM
 SG_ RLCR_4_Le2ObjCoordXDstStdDe : 119|8@0+ (0.05,0) [0|12.7] ""  FCM
 SG_ RLCR_4_Le2ObjCoordYDstStdDe : 127|8@0+ (0.05,0) [0|12.7] ""  FCM
 SG_ RLCR_4_Le2ObjXDirVStdDe : 135|6@0+ (0.05,0) [0|2] ""  FCM
 SG_ RLCR_4_Le2ObjYDirVStdDe : 129|6@0+ (0.05,0) [0|2] ""  FCM
 SG_ RLCR_4_MsgCntr : 179|4@0+ (1,0) [0|15] ""  FCM
 SG_ RLCR_4_CRC : 191|8@0+ (1,0) [0|255] ""  FCM

BO_ 941 RLCR_5: 24 Vector__XXX
 SG_ RLCR_5_Le3ObjBoxLen : 7|9@0+ (0.1,0) [0|50] "m"  FCM
 SG_ RLCR_5_Le3ObjBoxWidth : 14|9@0+ (0.1,0) [0|50] "m"  FCM
 SG_ RLCR_5_Le3HdTo : 21|12@0+ (0.1,-180) [-180|180] "deg"  FCM
 SG_ RLCR_5_Le3ObjID : 25|8@0+ (1,0) [0|255] ""  FCM
 SG_ RLCR_5_Le3ObjCoordY : 33|13@0+ (0.05,-200) [-200|200] "m"  FCM
 SG_ RLCR_5_Le3ObjCoordX : 52|13@0+ (0.05,-200) [-200|200] "m"  FCM
 SG_ RLCR_5_Le3ObjXDirAV : 71|8@0+ (0.1,-12.8) [-12.8|12.7] "m/s2"  FCM
 SG_ RLCR_5_Le3ObjYDirV : 79|14@0+ (0.02,-128) [-128|128] "m/s"  FCM
 SG_ RLCR_5_Le3ObjXDirV : 81|14@0+ (0.02,-128) [-128|128] "m/s"  FCM
 SG_ RLCR_5_Le3ObjMtnChartc : 99|2@0+ (1,0) [0|3] ""  FCM
 SG_ RLCR_5_Le3ObjTyp : 97|2@0+ (1,0) [0|3] ""  FCM
 SG_ RLCR_5_Le3ObjConf : 111|1@0+ (1,0) [0|1] ""  FCM
 SG_ RLCR_5_Le3ObjNrOffocst : 110|5@0+ (1,0) [0|31] ""  FCM
 SG_ RLCR_5_Le3ObjTrackSt : 105|2@0+ (1,0) [0|3] ""  FCM
 SG_ RLCR_5_Le3ObjCoordXDstStdDe : 119|8@0+ (0.05,0) [0|12.7] ""  FCM
 SG_ RLCR_5_Le3ObjCoordYDstStdDe : 127|8@0+ (0.05,0) [0|12.7] ""  FCM
 SG_ RLCR_5_Le3ObjXDirVStdDe : 135|6@0+ (0.05,0) [0|2] ""  FCM
 SG_ RLCR_5_Le3ObjYDirVStdDe : 129|6@0+ (0.05,0) [0|2] ""  FCM
 SG_ RLCR_5_MsgCntr : 179|4@0+ (1,0) [0|15] ""  FCM
 SG_ RLCR_5_CRC : 191|8@0+ (1,0) [0|255] ""  FCM

BO_ 946 RLCR_6: 24 Vector__XXX
 SG_ RLCR_6_Le4ObjBoxLen : 7|9@0+ (0.1,0) [0|50] "m"  FCM
 SG_ RLCR_6_Le4ObjBoxWidth : 14|9@0+ (0.1,0) [0|50] "m"  FCM
 SG_ RLCR_6_Le4HdTo : 21|12@0+ (0.1,-180) [-180|180] "deg"  FCM
 SG_ RLCR_6_Le4ObjID : 25|8@0+ (1,0) [0|255] ""  FCM
 SG_ RLCR_6_Le4ObjCoordY : 33|13@0+ (0.05,-200) [-200|200] "m"  FCM
 SG_ RLCR_6_Le4ObjCoordX : 52|13@0+ (0.05,-200) [-200|200] "m"  FCM
 SG_ RLCR_6_Le4ObjXDirAV : 71|8@0+ (0.1,-12.8) [-12.8|12.7] "m/s2"  FCM
 SG_ RLCR_6_Le4ObjYDirV : 79|14@0+ (0.02,-128) [-128|128] "m/s"  FCM
 SG_ RLCR_6_Le4ObjXDirV : 81|14@0+ (0.02,-128) [-128|128] "m/s"  FCM
 SG_ RLCR_6_Le4ObjMtnChartc : 99|2@0+ (1,0) [0|3] ""  FCM
 SG_ RLCR_6_Le4ObjTyp : 97|2@0+ (1,0) [0|3] ""  FCM
 SG_ RLCR_6_Le4ObjConf : 111|1@0+ (1,0) [0|1] ""  FCM
 SG_ RLCR_6_Le4ObjNrOffocst : 110|5@0+ (1,0) [0|31] ""  FCM
 SG_ RLCR_6_Le4ObjTrackSt : 105|2@0+ (1,0) [0|3] ""  FCM
 SG_ RLCR_6_Le4ObjCoordXDstStdDe : 119|8@0+ (0.05,0) [0|12.7] ""  FCM
 SG_ RLCR_6_Le4ObjCoordYDstStdDe : 127|8@0+ (0.05,0) [0|12.7] ""  FCM
 SG_ RLCR_6_Le4ObjXDirVStdDe : 135|6@0+ (0.05,0) [0|2] ""  FCM
 SG_ RLCR_6_Le4ObjYDirVStdDe : 129|6@0+ (0.05,0) [0|2] ""  FCM
 SG_ RLCR_6_MsgCntr : 179|4@0+ (1,0) [0|15] ""  FCM
 SG_ RLCR_6_CRC : 191|8@0+ (1,0) [0|255] ""  FCM

BO_ 948 RLCR_7: 24 Vector__XXX
 SG_ RLCR_7_Le5ObjBoxLen : 7|9@0+ (0.1,0) [0|50] "m"  FCM
 SG_ RLCR_7_Le5ObjBoxWidth : 14|9@0+ (0.1,0) [0|50] "m"  FCM
 SG_ RLCR_7_Le5HdTo : 21|12@0+ (0.1,-180) [-180|180] "deg"  FCM
 SG_ RLCR_7_Le5ObjID : 25|8@0+ (1,0) [0|255] ""  FCM
 SG_ RLCR_7_Le5ObjCoordY : 33|13@0+ (0.05,-200) [-200|200] "m"  FCM
 SG_ RLCR_7_Le5ObjCoordX : 52|13@0+ (0.05,-200) [-200|200] "m"  FCM
 SG_ RLCR_7_Le5ObjXDirAV : 71|8@0+ (0.1,-12.8) [-12.8|12.7] "m/s2"  FCM
 SG_ RLCR_7_Le5ObjYDirV : 79|14@0+ (0.02,-128) [-128|128] "m/s"  FCM
 SG_ RLCR_7_Le5ObjXDirV : 81|14@0+ (0.02,-128) [-128|128] "m/s"  FCM
 SG_ RLCR_7_Le5ObjMtnChartc : 99|2@0+ (1,0) [0|3] ""  FCM
 SG_ RLCR_7_Le5ObjTyp : 97|2@0+ (1,0) [0|3] ""  FCM
 SG_ RLCR_7_Le5ObjConf : 111|1@0+ (1,0) [0|1] ""  FCM
 SG_ RLCR_7_Le5ObjNrOffocst : 110|5@0+ (1,0) [0|31] ""  FCM
 SG_ RLCR_7_Le5ObjTrackSt : 105|2@0+ (1,0) [0|3] ""  FCM
 SG_ RLCR_7_Le5ObjCoordXDstStdDe : 119|8@0+ (0.05,0) [0|12.7] ""  FCM
 SG_ RLCR_7_Le5ObjCoordYDstStdDe : 127|8@0+ (0.05,0) [0|12.7] ""  FCM
 SG_ RLCR_7_Le5ObjXDirVStdDe : 135|6@0+ (0.05,0) [0|2] ""  FCM
 SG_ RLCR_7_Le5ObjYDirVStdDe : 129|6@0+ (0.05,0) [0|2] ""  FCM
 SG_ RLCR_7_MsgCntr : 179|4@0+ (1,0) [0|15] ""  FCM
 SG_ RLCR_7_CRC : 191|8@0+ (1,0) [0|255] ""  FCM

BO_ 953 RLCR_8: 8 Vector__XXX
 SG_ RLCR_8_TiStampLaten : 7|16@0+ (1,0) [0|65535] ""  FCM
 SG_ RLCR_8_MsgCntr : 51|4@0+ (1,0) [0|15] ""  FCM
 SG_ RLCR_8_CRC : 63|8@0+ (1,0) [0|255] ""  FCM

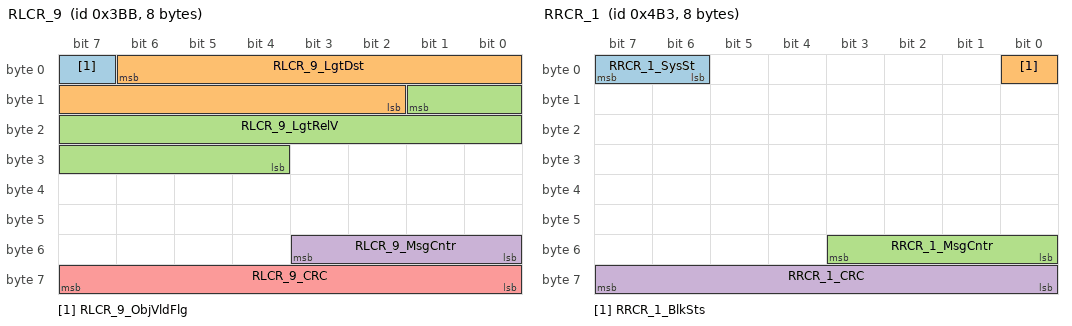
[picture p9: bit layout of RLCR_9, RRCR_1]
BO_ 955 RLCR_9: 8 Vector__XXX
 SG_ RLCR_9_ObjVldFlg : 7|1@0+ (1,0) [0|1] ""  FCM
 SG_ RLCR_9_LgtDst : 6|13@0+ (0.05,-200) [-200|200] "m"  FCM
 SG_ RLCR_9_LgtRelV : 9|14@0+ (0.02,-128) [-128|128] "m/s"  FCM
 SG_ RLCR_9_MsgCntr : 51|4@0+ (1,0) [0|15] ""  FCM
 SG_ RLCR_9_CRC : 63|8@0+ (1,0) [0|255] ""  FCM

BO_ 1203 RRCR_1: 8 Vector__XXX
 SG_ RRCR_1_SysSt : 7|2@0+ (1,0) [0|3] ""  FCM
 SG_ RRCR_1_BlkSts : 0|1@0+ (1,0) [0|1] ""  FCM
 SG_ RRCR_1_MsgCntr : 51|4@0+ (1,0) [0|15] ""  FCM
 SG_ RRCR_1_CRC : 63|8@0+ (1,0) [0|255] ""  FCM

BO_ 959 RRCR_2: 24 Vector__XXX
 SG_ RRCR_2_Ri1ObjBoxLen : 7|9@0+ (0.1,0) [0|50] "m"  FCM
 SG_ RRCR_2_Ri1ObjBoxWidth : 14|9@0+ (0.1,0) [0|50] "m"  FCM
 SG_ RRCR_2_Ri1HdTo : 21|12@0+ (0.1,-180) [-180|180] "deg"  FCM
 SG_ RRCR_2_Ri1ObjID : 25|8@0+ (1,0) [0|255] ""  FCM
 SG_ RRCR_2_Ri1ObjCoordY : 33|13@0+ (0.05,-200) [-200|200] "m"  FCM
 SG_ RRCR_2_Ri1ObjCoordX : 52|13@0+ (0.05,-200) [-200|200] "m"  FCM
 SG_ RRCR_2_Ri1ObjXDirAV : 71|8@0+ (0.1,-12.8) [-12.8|12.7] "m/s2"  FCM
 SG_ RRCR_2_Ri1ObjYDirV : 79|14@0+ (0.02,-128) [-128|128] "m/s"  FCM
 SG_ RRCR_2_Ri1ObjXDirV : 81|14@0+ (0.02,-128) [-128|128] "m/s"  FCM
 SG_ RRCR_2_Ri1ObjMtnChartc : 99|2@0+ (1,0) [0|3] ""  FCM
 SG_ RRCR_2_Ri1ObjTyp : 97|2@0+ (1,0) [0|3] ""  FCM
 SG_ RRCR_2_Ri1ObjConf : 111|1@0+ (1,0) [0|1] ""  FCM
 SG_ RRCR_2_Ri1ObjNrOffocst : 110|5@0+ (1,0) [0|31] ""  FCM
 SG_ RRCR_2_Ri1ObjTrackSt : 105|2@0+ (1,0) [0|3] ""  FCM
 SG_ RRCR_2_Ri1ObjCoordXDstStdDe : 119|8@0+ (0.05,0) [0|12.7] ""  FCM
 SG_ RRCR_2_Ri1ObjCoordYDstStdDe : 127|8@0+ (0.05,0) [0|12.7] ""  FCM
 SG_ RRCR_2_Ri1ObjXDirVStdDe : 135|6@0+ (0.05,0) [0|2] ""  FCM
 SG_ RRCR_2_Ri1ObjYDirVStdDe : 129|6@0+ (0.05,0) [0|2] ""  FCM
 SG_ RRCR_2_MsgCntr : 179|4@0+ (1,0) [0|15] ""  FCM
 SG_ RRCR_2_CRC : 191|8@0+ (1,0) [0|255] ""  FCM

CM_ "Version:V1.0,Date:2021/4/30,Author:XiaopingGao,Review:ZhongLinWang,Approval:JiancaiLi,Description:(Frist revision)Frist revision;
Version:V1.1,Date:2021/5/27,Author:XiaopingGao,Review:ZhongLinWang,Approval:JiancaiLi,Description:(RLCR_1(0x4B1))RLCR_1(0x4B1)
FCM add received these messages(for BOSCH/VEONEER ELK)`
(RLCR_3(0x3A7))RLCR_3(0x3A7)
FCM add received these messages(for VEONEER ELK)`
(RLCR_4(0x3A9))RLCR_4(0x3A9)`
(RLCR_5(0x3AD))RLCR_5(0x3AD)`
(RLCR_6(0x3B2))RLCR_6(0x3B2)`
(RLCR_7(0x3B4))RLCR_7(0x3B4)`
(RLCR_8(0x3B9))RLCR_8(0x3B9)`
(RLCR_9(0x3BB))RLCR_9(0x3BB)
FCM add received these messages(for BOSCH ELK)`
(RRCR_1(0x4B3))RRCR_1(0x4B3)
FCM add received these messages(for BOSCH/VEONEER ELK)`
(RRCR_2(0x3BF))RRCR_2(0x3BF)
FCM add received these messages(for VEONEER ELK)`
(RRCR_3(0x3C9))RRCR_3(0x3C9)`
(RRCR_4(0x3D0))RRCR_4(0x3D0)`
(RRCR_5(0x3D8))RRCR_5(0x3D8)`
(RRCR_6(0x3DA))RRCR_6(0x3DA)`
(RRCR_7(0x3E0))RRCR_7(0x3E0)`
(RRCR_8(0x3E2))RRCR_8(0x3E2)
FCM add received these messages(for BOSCH ELK)`
(FCM_2(0x307))FCM_ELKSts
delete send this signal;
 ";

CM_ BO_ 935 "(only for VEONEER)";
CM_ BO_ 937 "(only for VEONEER)";
CM_ BO_ 941 "(only for VEONEER)";
CM_ BO_ 946 "(only for VEONEER)";
CM_ BO_ 948 "(only for VEONEER)";
CM_ BO_ 953 "(only for VEONEER)";
CM_ BO_ 955 "(only for Bosch)";
CM_ BO_ 959 "(only for VEONEER)";
CM_ SG_ 775 HMA_Status "HMA Status";
CM_ SG_ 775 HMA_HighbeamReq "HMA_High beam Request";
CM_ SG_ 775 FCM_2_Resd1 "HMAOnOffsts_Resd";
CM_ SG_ 775 LDW_ELK_TJA_LDPLeftVisuali "LDW_ELK_TJA_LDP Left Visualization";
CM_ SG_ 775 LDW_ELK_TJA_LDPRightVisuali "LDW_ELK_TJA_LDP Right Visualization";
CM_ SG_ 775 FCM_2_ISAState "ISA关闭时，需要有图标提醒";
CM_ SG_ 775 FCM_2_Resd3 "LDWLKA_LaneAssitfeedback_Resd";
CM_ SG_ 775 FCM_2_Resd4 "LDWLKA_Sensitivityfeedback_Resd";
CM_ SG_ 775 FCM_2_SCFSpdlimWarn "SCF Speed limit Warning";
CM_ SG_ 775 SLAState "SLA State";
CM_ SG_ 775 SLASpdlimit "SLA Speed limit
Add 135-180 for European region";
CM_ SG_ 775 FCM_2_Resd6 "SLAOnOffsts_Resd";
CM_ SG_ 775 SLASpdlimitWarning "SLA Speed limit Warning";
CM_ SG_ 775 Camera_textinfo "Camera text information";
CM_ SG_ 775 FCM_2_Resd13 "ADAS_TakeoverReq:Take over request to driver";
CM_ SG_ 775 FCM_2_SpdLimtyp "speed limit type";
CM_ SG_ 775 FCM_2_Resd8 "TJA_ICA_Textinfo";
CM_ SG_ 775 TJA_ICA_mode "TJA_ICA mode";
CM_ SG_ 775 FCM_2_SLASpdLimChgAud "SLASpdlimitChangeAud
SLA限速值变化提示音";
CM_ SG_ 775 FCM_2_SLASpdlimitUnits "SLA Speed limit Units";
CM_ SG_ 775 FCM_2_TJATakeoverReq "TJA,可以提醒驾驶员控制方向盘，避免因长时脱手引发危险，
TJA一级段脱手报警仅需提供光学报警,TJA二级段脱手报警和LDP所有脱手报警都需要提供
光学和声音报警,";
CM_ SG_ 775 FCM_2_MessageCounter "Rolling message counter(the maximum value of Alive counter is 15)
Note: Details Please refer to specification《EE Standard Specification for CAN FD Network Implementation》section 2.3.1";
CM_ SG_ 775 FCM_2_CRC "CRC (SAE J1850 CRC-8)
Note: Details Please refer to specification《EE Standard Specification for CAN FD Network Implementation》section 2.3.2";
CM_ SG_ 837 FCM_3_StrngWhlAgReq "DADC request for steering wheel angle, steering wheel angle request.";
CM_ SG_ 837 FCM_3_StrngWhlAgReqActive "DADC request flag for steering wheel angle control to be enabled";
CM_ SG_ 837 FCM_3_HptcVibReq "Vibration request flag for steering wheel angle";
CM_ SG_ 837 FCM_3_ManMachineSharingSts "FCM是否支持人机共驾标志位";
CM_ SG_ 837 FCM_3_MsgCntr "Rolling message counter(the maximum value of Alive counter is 15)
Note: Details Please refer to specification《EE Standard Specification for CAN FD Network Implementation》section 2.3.1";
CM_ SG_ 837 FCM_3_CRC "CRC (SAE J1850 CRC-8)
Note: Details Please refer to specification《EE Standard Specification for CAN FD Network Implementation》section 2.3.2";
CM_ SG_ 1245 FCM_5_TJAICAExitTextInfoSts "TJAICA Exit Text Information status";
CM_ SG_ 1245 FCM_5_SLAONOFFSts "SLA ON/OFF status";
CM_ SG_ 1245 FCM_5_IESONOFFSts "IES status";
CM_ SG_ 1245 FCM_5_HMAONOFFSts "HMA status";
CM_ SG_ 1245 FCM_5_TSIONOFFSts "TSI status";
CM_ SG_ 1245 FCM_5_TLIONOFFSts "TLI status";
CM_ SG_ 1245 FCM_5_LDWONOFFSts "LDW status";
CM_ SG_ 1245 FCM_5_WarnModSts "Warning Mode status";
CM_ SG_ 1245 FCM_5_LDPONOFFSts "LDP status";
CM_ SG_ 1245 FCM_5_LDWLDPSnvtySts "LDW LDP Senstitivity status";
CM_ SG_ 1245 FCM_5_ELKONOFFSts "ELK status";
CM_ SG_ 1245 FCM_5_SpeedLmtNmberAb "Speed limit threshold adjustment signal, from -10 to 10
限速阈值调整信号，从-10到10";
CM_ SG_ 1245 FCM_5_SpeedLmtNmberE "The speed limit threshold is adjusted relative to the signal, from -20% to 20%
限速阈值调整相对信号，从-20%到20%";
CM_ SG_ 1245 FCM_5_SLAmodeSWSet "Speed limit warning switch signal
限速提醒切换信号";
CM_ SG_ 1245 FCM_5_MsgCntr "Rolling message counter(the maximum value of Alive counter is 15)
Note: Details Please refer to specification《EE Standard Specification for CAN FD Network Implementation》section 2.3.1";
CM_ SG_ 1245 FCM_5_CRC "CRC (SAE J1850 CRC-8)
Note: Details Please refer to specification《EE Standard Specification for CAN FD Network Implementation》section 2.3.2";
CM_ SG_ 988 FCM_6_EgoLeLineID "Ego Car Left Line ID";
CM_ SG_ 988 FCM_6_EgoLeLineColor "Ego Car left lane line color";
CM_ SG_ 988 FCM_6_EgoLeLineTyp "The type of Ego car left lane line";
CM_ SG_ 988 FCM_6_EgoLeLineHozlDst "Horizontal distance between the Ego car and the left lane line";
CM_ SG_ 988 FCM_6_EgoLeLineCrvt "Curvature of the Ego Car left lane line";
CM_ SG_ 988 FCM_6_EgoRiLineID "Ego Car Right Line ID";
CM_ SG_ 988 FCM_6_EgoRiLineColor "Ego Car Right lane line color";
CM_ SG_ 988 FCM_6_EgoRiLineTyp "The type of Ego car Right lane line";
CM_ SG_ 988 FCM_6_EgoRiLineHozlDst "Horizontal distance between the Ego car and the Right lane line";
CM_ SG_ 988 FCM_6_EgoRiLineCrvt "Curvature of the Ego Car Right lane line";
CM_ SG_ 988 FCM_6_MsgCntr "Rolling message counter(the maximum value of Alive counter is 15)
Note: Details Please refer to specification《EE Standard Specification for CAN FD Network Implementation》section 2.3.1";
CM_ SG_ 988 FCM_6_CRC "CRC (SAE J1850 CRC-8)
Note: Details Please refer to specification《EE Standard Specification for CAN FD Network Implementation》section 2.3.2";
CM_ SG_ 990 FCM_7_NeborLeLineID "Neighbor Left Line ID";
CM_ SG_ 990 FCM_7_NeborLeLineColor "Neighbor Left Line Color";
CM_ SG_ 990 FCM_7_NeborLeLineTyp "The type of Neighbor Left Line";
CM_ SG_ 990 FCM_7_NeborLeLineHozlDst "Horizontal distance of Neighbor Left Line";
CM_ SG_ 990 FCM_7_NeborLeLineCrvt "Curvature of the Neighbor Left Line";
CM_ SG_ 990 FCM_7_NeborRiLineID "Neighbor Right Line ID";
CM_ SG_ 990 FCM_7_NeborRiLineColor "Neighbor Right Line Color";
CM_ SG_ 990 FCM_7_NeborRiLineTyp "The type of Neighbor Right Line";
CM_ SG_ 990 FCM_7_NeborRiLineHozlDst "Horizontal distance of Neighbor Right Line";
CM_ SG_ 990 FCM_7_NeborRiLineCrvt "Curvature of the Neighbor Right  Line";
CM_ SG_ 990 FCM_7_MsgCntr "Rolling message counter(the maximum value of Alive counter is 15)
Note: Details Please refer to specification《EE Standard Specification for CAN FD Network Implementation》section 2.3.1";
CM_ SG_ 990 FCM_7_CRC "CRC (SAE J1850 CRC-8)
Note: Details Please refer to specification《EE Standard Specification for CAN FD Network Implementation》section 2.3.2";
CM_ SG_ 1005 FCM_FRM_8_ACCObjID "ACC Object ID";
CM_ SG_ 1005 FCM_FRM_8_ACCObjTyp "ACC Object Type";
CM_ SG_ 1005 FCM_FRM_8_ACCObjLgtDstX "ACC Object longitudinal distance X";
CM_ SG_ 1005 FCM_FRM_8_ACCObjHozDstY "ACC Object horizontal distance Y";
CM_ SG_ 1005 FCM_FRM_8_FrntFarObjID "Front Far Object ID";
CM_ SG_ 1005 FCM_FRM_8_FrntFarObjTyp "Front Far Object Type";
CM_ SG_ 1005 FCM_FRM_8_FrntFarObjLgtDstX "Front Far Object longitudinal distance X";
CM_ SG_ 1005 FCM_FRM_8_FrntFarObjHozDstY "Front Far Object horizontal distance Y";
CM_ SG_ 1005 FCM_FRM_8_IDSONOFFSts "IDS状态反馈";
CM_ SG_ 1005 FCM_FRM_8_WSOSONOFFSts "WSOS状态反馈";
CM_ SG_ 1005 FCM_FRM_8_MsgCntr "Rolling message counter(the maximum value of Alive counter is 15)
Note: Details Please refer to specification《EE Standard Specification for CAN FD Network Implementation》section 2.3.1";
CM_ SG_ 1005 FCM_FRM_8_CRC "CRC (SAE J1850 CRC-8)
Note: Details Please refer to specification《EE Standard Specification for CAN FD Network Implementation》section 2.3.2";
CM_ SG_ 1018 FCM_FRM_9_LeObjID "Left  Object ID";
CM_ SG_ 1018 FCM_FRM_9_LeObjTyp "Left  Object Type";
CM_ SG_ 1018 FCM_FRM_9_LeObjLgtDstX "Left Object longitudinal distance X";
CM_ SG_ 1018 FCM_FRM_9_LeObjHozDstY "Left  Object horizontal distance Y";
CM_ SG_ 1018 FCM_FRM_9_RiObjID "Right Object ID";
CM_ SG_ 1018 FCM_FRM_9_RiObjTyp "Right Object Type";
CM_ SG_ 1018 FCM_FRM_9_RiObjLgtDstX "Right Object longitudinal distance X";
CM_ SG_ 1018 FCM_FRM_9_RiObjHozDstY "Right Object horizontal distance Y";
CM_ SG_ 1018 FCM_FRM_9_MsgCntr "Rolling message counter(the maximum value of Alive counter is 15)
Note: Details Please refer to specification《EE Standard Specification for CAN FD Network Implementation》section 2.3.1";
CM_ SG_ 1018 FCM_FRM_9_CRC "CRC (SAE J1850 CRC-8)
Note: Details Please refer to specification《EE Standard Specification for CAN FD Network Implementation》section 2.3.2";
CM_ SG_ 1020 FCM_10_TSISysSts "TSI System Status";
CM_ SG_ 1020 FCM_10_TLISysSts "TLI system Status";
CM_ SG_ 1020 FCM_10_TSISgnGiWay "TSI Sign for give way";
CM_ SG_ 1020 FCM_10_TSISgnForb "TSI Sign for forbid";
CM_ SG_ 1020 FCM_10_TSISgnLongStayDisp "TSI Sign Long Stay Display";
CM_ SG_ 1020 FCM_10_TLITrfcLi "TLI Traffic Light";
CM_ SG_ 1020 FCM_10_LDPSysSts "LDP System Status";
CM_ SG_ 1020 FCM_10_LDWSysSts "LDW System Status";
CM_ SG_ 1020 FCM_10_ELKSysSts "ELK System Status";
CM_ SG_ 1020 FCM_10_TSINoParkWarn "TSI No Park Warning";
CM_ SG_ 1020 FCM_10_TJAICATextinfo "TJA_ICA_Text information";
CM_ SG_ 1020 FCM_10_TJAICAEnaRcmend "Enable TJA/ICA is recommended";
CM_ SG_ 1020 FCM_10_LDPTJAELKTakeoverReq "Take over request to driver
老项目LDP和TJA继续使用FCM10 LDPTJAELKTakeoverReq,仪表处理逻辑不变(确保不影响老项目,老项目TJA/LDP继续使用此信号
新项目LDP继续使用FCM10 LDPTJAELKTakeoverReq,仪表处理逻辑不变;仅TJA使用增加的FCM2TJATakeoverReq信号,仪表按上表要求发出对应报警提示接管";
CM_ SG_ 1020 FCM_10_TJAICAExitTextInfoSts "TJAICA Exit Text Information status";
CM_ SG_ 1020 FCM_10_SLAONOFFSts "SLA ON/OFF status";
CM_ SG_ 1020 FCM_10_WarnModSts "Warning Mode status";
CM_ SG_ 1020 FCM_10_ELKIntvMod "ELK Intervention Mode";
CM_ SG_ 1020 FCM_10_EgoLeftLineHeatgAg "ICM display the Angle between vehicle and lane line";
CM_ SG_ 1020 FCM_10_MsgCntr "Rolling message counter(the maximum value of Alive counter is 15)
Note: Details Please refer to specification《EE Standard Specification for CAN FD Network Implementation》section 2.3.1";
CM_ SG_ 1020 FCM_10_CRC "CRC (SAE J1850 CRC-8)
Note: Details Please refer to specification《EE Standard Specification for CAN FD Network Implementation》section 2.3.2";
CM_ SG_ 930 ACCTarAcc "ACC target acceleration";
CM_ SG_ 930 VLCShutdownMode "VLC shutdown mode";
CM_ SG_ 930 ACCMode_ESP "The status of the ACC control unit.
The ACC mode should be contained in every message sent by ACC.";
CM_ SG_ 930 ComfortAccUpperValue "Comfort acceleration Upper Value";
CM_ SG_ 930 BrakePreferred "Brake Preferred from ACC request and relevant request";
CM_ SG_ 930 ComfortAccLowerValue "Comfort acceleration Lower Value";
CM_ SG_ 930 DriveOff "ACC request the VLC to drive off.";
CM_ SG_ 930 LimitAccUpperValue "target acceleration change rate Limit Upper Value";
CM_ SG_ 930 DecToStop "deceleration to stop";
CM_ SG_ 930 LimitAccLowerValue "target acceleration change rate Limit Lower Value";
CM_ SG_ 930 ACC_AccECGPOvrd "driver request torque override ACC request torque";
CM_ SG_ 930 HBALevel "HBA Level";
CM_ SG_ 930 HBARequest "HBA Request";
CM_ SG_ 930 PrefillRequest "Prefill Request(ABP)";
CM_ SG_ 930 FCM_FRM_1_MessageCounter "Rolling message counter(the maximum value of Alive counter is 15)
Note: Details Please refer to specification《EE Standard Specification for CAN FD Network Implementation》section 2.3.1";
CM_ SG_ 930 FCM_FRM_1_CRC "CRC (SAE J1850 CRC-8)
Note: Details Please refer to specification《EE Standard Specification for CAN FD Network Implementation》section 2.3.2";
CM_ SG_ 933 AEBTarDec "AEB target deceleration";
CM_ SG_ 933 AEBDecCtrlRequest "AEB deceleration Control Request";
CM_ SG_ 933 ACCMinimumBraking "When dirver accelerate override the set speed and stop accelerate. From ACC side, after override, ACC should send the bit until the vehcile speed decease and reach the ACC set speed in order to have a smooth brake";
CM_ SG_ 933 ACCStartStopInfo "ACC Start_Stop Info";
CM_ SG_ 933 AEBReq "AEB Request";
CM_ SG_ 933 AWBRequest "AWB Request";
CM_ SG_ 933 AWBLevel "AWB Level
accord to different condition,select different level to remind driver";
CM_ SG_ 933 FCM_FRM_2_Textinfo_Info "Text Information";
CM_ SG_ 933 FCM_FRM_2_MessageCounter "Rolling message counter(the maximum value of Alive counter is 15)
Note: Details Please refer to specification《EE Standard Specification for CAN FD Network Implementation》section 2.3.1";
CM_ SG_ 933 FCM_FRM_2_CRC "CRC (SAE J1850 CRC-8)
Note: Details Please refer to specification《EE Standard Specification for CAN FD Network Implementation》section 2.3.2";
CM_ SG_ 773 FCM_FRM_3_Resd1 "setted target speed";
CM_ SG_ 773 FCM_FRM_3_Resd2 "DxTarObj_Resd";
CM_ SG_ 773 FCM_FRM_3_Resd3 "FrontObject_Type_Resd";
CM_ SG_ 773 FCM_FRM_3_Resd4 "ObjValid_Resd";
CM_ SG_ 773 FCM_FRM_3_Resd6 "Take Over Request";
CM_ SG_ 773 FCM_FRM_3_Resd7 "TimeGapSet_DVD_Resd";
CM_ SG_ 773 FCM_FRM_3_Resd8 "TimeGapSetICM Resd";
CM_ SG_ 773 FCM_FRM_3_Resd9 "Object_dx_Resd";
CM_ SG_ 773 ACCModeDummy "Signal value is always 0x0";
CM_ SG_ 773 FCM_FRM_3_Resd10 "FCW Mode";
CM_ SG_ 773 FCM_FRM_3_Resd11 "AEB Mode";
CM_ SG_ 773 FCM_FRM_3_Resd12 "Distance Warning";
CM_ SG_ 773 FCM_FRM_3_Resd13 "FCW_preWarning";
CM_ SG_ 773 FCM_FRM_3_Resd14 "TimeGapLastSet_DVD_Resd";
CM_ SG_ 773 FCM_FRM_3_Resd16 "FCW_OPTION_sts_Resd";
CM_ SG_ 773 FCM_FRM_3_Resd18 "DistanceWarning_on_off_sts_Resd";
CM_ SG_ 773 FCM_FRM_3_MessageCounter "Rolling message counter(the maximum value of Alive counter is 15)
Note: Details Please refer to specification《EE Standard Specification for CAN FD Network Implementation》section 2.3.1";
CM_ SG_ 773 FCM_FRM_3_CRC "CRC (SAE J1850 CRC-8)
Note: Details Please refer to specification《EE Standard Specification for CAN FD Network Implementation》section 2.3.2";
CM_ SG_ 1251 FCM_FRM_5_AEBONOFFSts "AEB status";
CM_ SG_ 1251 FCM_FRM_5_FCWSnvtySts "FCW Sensitivity status";
CM_ SG_ 1251 FCM_FRM_5_FCWONOFFSts "FCW status";
CM_ SG_ 1251 FCM_FRM_5_SCFONOFFSts "SCF status";
CM_ SG_ 1251 FCM_FRM_5_DAIONOFFSts "DAI status";
CM_ SG_ 1251 FCM_FRM_5_MsgCntr "Rolling message counter(the maximum value of Alive counter is 15)
Note: Details Please refer to specification《EE Standard Specification for CAN FD Network Implementation》section 2.3.1";
CM_ SG_ 1251 FCM_FRM_5_CRC "CRC (SAE J1850 CRC-8)
Note: Details Please refer to specification《EE Standard Specification for CAN FD Network Implementation》section 2.3.2";
CM_ SG_ 903 FCM_FRM_6_Textinfo_Info "Text Information";
CM_ SG_ 903 FCM_FRM_6_TextinfoWarn "Text Information warning";
CM_ SG_ 903 FCM_FRM_6_Textinfo_Info_2 "Text Information2";
CM_ SG_ 903 FCM_FRM_6_TimeGapSetICM "Time Gap Set on the ICM";
CM_ SG_ 903 FCM_FRM_6_SCF_PopoverReq "SCF popover request";
CM_ SG_ 903 FCM_FRM_6_SCF_SpdLimSts "SCF Speed limit Status";
CM_ SG_ 903 FCM_FRM_6_SCF_SpdLimUnit "SCF Speed limit unit";
CM_ SG_ 903 FCM_FRM_6_DrvrCfmSCFDispFb "Driver confirmation SCF interface displays request feedback";
CM_ SG_ 903 FCM_FRM_6_DistanceWarning "Distance Warning";
CM_ SG_ 903 FCM_FRM_6_FCW_preWarning "FCW_preWarning";
CM_ SG_ 903 FCM_FRM_6_TakeOverReq "Take Over Request";
CM_ SG_ 903 FCM_FRM_6_FCWMode "FCW Mode";
CM_ SG_ 903 FCM_FRM_6_AEBMode "AEB Mode";
CM_ SG_ 903 FCM_FRM_6_AEBDecCtrlRequest "AEB deceleration Control Request";
CM_ SG_ 903 FCM_FRM_6_HMI_Indicator "0x0: 此时，下述三个指示灯均不点亮
0x1: 显示仪表黄色关闭指示灯
0x2: 显示仪表黄色故障指示灯
0x3: 显示仪表红色激活指示灯";
CM_ SG_ 903 FCM_FRM_6_ACCMode "ACC Mode";
CM_ SG_ 903 FCM_FRM_6_SCF_Indicator "0x0: 默认值 
0x1:调高至SCF限速 
0x2:调低至SCF限速
0x3: Reserved";
CM_ SG_ 903 FCM_FRM_6_VSetDis "setted target speed";
CM_ SG_ 903 FCM_FRM_6_MsgCntr "Rolling message counter(the maximum value of Alive counter is 15)
Note: Details Please refer to specification《EE Standard Specification for CAN FD Network Implementation》section 2.3.1";
CM_ SG_ 903 FCM_FRM_6_CRC "CRC (SAE J1850 CRC-8)
Note: Details Please refer to specification《EE Standard Specification for CAN FD Network Implementation》section 2.3.2";
CM_ SG_ 943 IDCU_1_AmbLi "Ambient Light";
CM_ SG_ 943 IDCU_1_HozlPosnRi "Object N1 horizontal position right";
CM_ SG_ 943 IDCU_1_HozlPosnLe "Object N1 horizontal position left";
CM_ SG_ 943 IDCU_1_ObjN1Dst "Object N1 Distance";
CM_ SG_ 943 IDCU_1_ObjN1_Type "Object N1 Type";
CM_ SG_ 943 IDCU_1_MsgCntr "Rolling message counter(the maximum value of Alive counter is 15)
Note: Details Please refer to specification《EE Standard Specification for CAN FD Network Implementation》section 2.3.1";
CM_ SG_ 943 IDCU_1_CRC "CRC (SAE J1850 CRC-8)
Note: Details Please refer to specification《EE Standard Specification for CAN FD Network Implementation》section 2.3.2";
CM_ SG_ 949 IDCU_2_FCMStForADB "FCM State For ADB";
CM_ SG_ 949 IDCU_2_HozlPosnRi "Object N2 horizontal position right";
CM_ SG_ 949 IDCU_2_HozlPosnLe "Object N2 horizontal position left";
CM_ SG_ 949 IDCU_2_ObjN1Dst "Object N2 Distance";
CM_ SG_ 949 IDCU_2_MsgCntr "Rolling message counter(the maximum value of Alive counter is 15)
Note: Details Please refer to specification《EE Standard Specification for CAN FD Network Implementation》section 2.3.1";
CM_ SG_ 949 IDCU_2_CRC "CRC (SAE J1850 CRC-8)
Note: Details Please refer to specification《EE Standard Specification for CAN FD Network Implementation》section 2.3.2";
CM_ SG_ 957 IDCU_3_HozlPosnRi "Object N3 horizontal position right";
CM_ SG_ 957 IDCU_3_HozlPosnLe "Object N3 horizontal position left";
CM_ SG_ 957 IDCU_3_ObjN3Dst "Object N3 Distance";
CM_ SG_ 957 IDCU_3_ObjN3_Type "ObjectN3_Type";
CM_ SG_ 957 IDCU_3_MsgCntr "Rolling message counter(the maximum value of Alive counter is 15)
Note: Details Please refer to specification《EE Standard Specification for CAN FD Network Implementation》section 2.3.1";
CM_ SG_ 957 IDCU_3_CRC "CRC (SAE J1850 CRC-8)
Note: Details Please refer to specification《EE Standard Specification for CAN FD Network Implementation》section 2.3.2";
CM_ SG_ 974 IDCU_4_HozlPosnRi "Object N4 horizontal position right";
CM_ SG_ 974 IDCU_4_HozlPosnLe "Object N4 horizontal position left";
CM_ SG_ 974 IDCU_4_ObjN4Dst "Object N4 Distance";
CM_ SG_ 974 IDCU_4_ObjN4_Type "ObjectN4_Type";
CM_ SG_ 974 IDCU_4_MsgCntr "Rolling message counter(the maximum value of Alive counter is 15)
Note: Details Please refer to specification《EE Standard Specification for CAN FD Network Implementation》section 2.3.1";
CM_ SG_ 974 IDCU_4_CRC "CRC (SAE J1850 CRC-8)
Note: Details Please refer to specification《EE Standard Specification for CAN FD Network Implementation》section 2.3.2";
CM_ SG_ 981 IDCU_5_HozlPosnRi "Object N5 horizontal position right";
CM_ SG_ 981 IDCU_5_HozlPosnLe "Object N5 horizontal position left";
CM_ SG_ 981 IDCU_5_ObjN5Dst "Object N5 Distance";
CM_ SG_ 981 IDCU_5_ObjN5_Type "ObjectN5_Type";
CM_ SG_ 981 IDCU_5_MsgCntr "Rolling message counter(the maximum value of Alive counter is 15)
Note: Details Please refer to specification《EE Standard Specification for CAN FD Network Implementation》section 2.3.1";
CM_ SG_ 981 IDCU_5_CRC "CRC (SAE J1850 CRC-8)
Note: Details Please refer to specification《EE Standard Specification for CAN FD Network Implementation》section 2.3.2";
CM_ SG_ 1001 IDCU_6_HozlPosnRi "Object N6 horizontal position right";
CM_ SG_ 1001 IDCU_6_HozlPosnLe "Object N6 horizontal position left";
CM_ SG_ 1001 IDCU_6_ObjN6Dst "Object N6 Distance";
CM_ SG_ 1001 IDCU_6_ObjN6_Type "ObjectN6_Type";
CM_ SG_ 1001 IDCU_6_MsgCntr "Rolling message counter(the maximum value of Alive counter is 15)
Note: Details Please refer to specification《EE Standard Specification for CAN FD Network Implementation》section 2.3.1";
CM_ SG_ 1001 IDCU_6_CRC "CRC (SAE J1850 CRC-8)
Note: Details Please refer to specification《EE Standard Specification for CAN FD Network Implementation》section 2.3.2";
CM_ SG_ 1003 IDCU_7_HozlPosnRi "Object N7 horizontal position right";
CM_ SG_ 1003 IDCU_7_HozlPosnLe "Object N7 horizontal position left";
CM_ SG_ 1003 IDCU_7_ObjN7Dst "Object N7 Distance";
CM_ SG_ 1003 IDCU_7_ObjN7_Type "ObjectN7_Type";
CM_ SG_ 1003 IDCU_7_MsgCntr "Rolling message counter(the maximum value of Alive counter is 15)
Note: Details Please refer to specification《EE Standard Specification for CAN FD Network Implementation》section 2.3.1";
CM_ SG_ 1003 IDCU_7_CRC "CRC (SAE J1850 CRC-8)
Note: Details Please refer to specification《EE Standard Specification for CAN FD Network Implementation》section 2.3.2";
CM_ SG_ 1013 IDCU_8_HozlPosnRi "Object N8 horizontal position right";
CM_ SG_ 1013 IDCU_8_HozlPosnLe "Object N8 horizontal position left";
CM_ SG_ 1013 IDCU_8_ObjN6Dst "Object N8 Distance";
CM_ SG_ 1013 IDCU_8_ObjN8_Type "ObjectN8_Type";
CM_ SG_ 1013 IDCU_8_MsgCntr "Rolling message counter(the maximum value of Alive counter is 15)
Note: Details Please refer to specification《EE Standard Specification for CAN FD Network Implementation》section 2.3.1";
CM_ SG_ 1013 IDCU_8_CRC "CRC (SAE J1850 CRC-8)
Note: Details Please refer to specification《EE Standard Specification for CAN FD Network Implementation》section 2.3.2";
CM_ SG_ 1201 RLCR_1_SysSt "System self-test State(only for VEONEER)";
CM_ SG_ 1201 RLCR_1_ELKSts "ELK Status of Left radar(only for VEONEER)";
CM_ SG_ 1201 RLCR_1_BlkSts "Blockage Status(only for VEONEER)";
CM_ SG_ 1201 RLCR_1_MsgCntr "Rolling message counter(the maximum value of Alive counter is 15)
Note: Details Please refer to specification《EE Standard Specification for CAN FD Network Implementation》section 2.3.1";
CM_ SG_ 1201 RLCR_1_CRC "CRC (SAE J1850 CRC-8)
Note: Details Please refer to specification《EE Standard Specification for CAN FD Network Implementation》section 2.3.2";
CM_ SG_ 935 RLCR_3_Le1ObjBoxLen "left 1 Objective Box Length";
CM_ SG_ 935 RLCR_3_Le1ObjBoxWidth "left 1 Objective Box Width";
CM_ SG_ 935 RLCR_3_Le1HdTo "left 1 Head towards";
CM_ SG_ 935 RLCR_3_Le1ObjID "left 1 Objective ID";
CM_ SG_ 935 RLCR_3_Le1ObjCoordY "Y coordinates of Left 1 Objective目标物中心位置y轴坐标";
CM_ SG_ 935 RLCR_3_Le1ObjCoordX "X coordinates of left 1 Objective目标物中心位置x轴坐标";
CM_ SG_ 935 RLCR_3_Le1ObjXDirAV "left 1 Objective X directions Acceleration velocity目标物x方向加速度";
CM_ SG_ 935 RLCR_3_Le1ObjYDirV "left 1 Objective Y directions velocity目标物y方向速度";
CM_ SG_ 935 RLCR_3_Le1ObjXDirV "left 1 Objective X directions velocity目标物x方向速度";
CM_ SG_ 935 RLCR_3_Le1ObjMtnChartc "left 1 Objective motion characteristic目标运动特征";
CM_ SG_ 935 RLCR_3_Le1ObjTyp "left 1 Objective type
-00 (Ukwn)： invalid（Unused objects, such as people）";
CM_ SG_ 935 RLCR_3_Le1ObjConf "left 1 Objective confidence目标置信度";
CM_ SG_ 935 RLCR_3_Le1ObjNrOffocst "forecast Number of left 1 Objective  目标预测次数";
CM_ SG_ 935 RLCR_3_Le1ObjTrackSt "left 1 Objective Track state 目标追踪状态";
CM_ SG_ 935 RLCR_3_Le1ObjCoordXDstStdDe "left 1 Objective X coordinates distance standard deviations
x轴距离标准";
CM_ SG_ 935 RLCR_3_Le1ObjCoordYDstStdDe "left 1 ObjectiveY coordinates distance standard deviations  y轴距离标准差";
CM_ SG_ 935 RLCR_3_Le1ObjXDirVStdDe "left 1 Objective X directions velocity standard deviations x方向速度标准差";
CM_ SG_ 935 RLCR_3_Le1ObjYDirVStdDe "left 1 Objective Y directions velocity standard deviations y方向速度标准差";
CM_ SG_ 935 RLCR_3_MsgCntr "Rolling message counter(the maximum value of Alive counter is 15)
Note: Details Please refer to specification《EE Standard Specification for CAN FD Network Implementation》section 2.3.1";
CM_ SG_ 935 RLCR_3_CRC "CRC (SAE J1850 CRC-8)
Note: Details Please refer to specification《EE Standard Specification for CAN FD Network Implementation》section 2.3.2";
CM_ SG_ 937 RLCR_4_Le2ObjBoxLen "left 2 Objective Box Length";
CM_ SG_ 937 RLCR_4_Le2ObjBoxWidth "left 2 Objective Box Width";
CM_ SG_ 937 RLCR_4_Le2HdTo "left 2 Head towards";
CM_ SG_ 937 RLCR_4_Le2ObjID "left 2 Objective ID";
CM_ SG_ 937 RLCR_4_Le2ObjCoordY "Y coordinates of left 2 Objective目标物中心位置y轴坐标";
CM_ SG_ 937 RLCR_4_Le2ObjCoordX "X coordinates of left 2Objective目标物中心位置x轴坐标";
CM_ SG_ 937 RLCR_4_Le2ObjXDirAV "left 2 Objective X directions Acceleration velocity目标物x方向加速度";
CM_ SG_ 937 RLCR_4_Le2ObjYDirV "left 2Objective Y directions velocity目标物y方向速度";
CM_ SG_ 937 RLCR_4_Le2ObjXDirV "left 2Objective X directions velocity目标物x方向速度";
CM_ SG_ 937 RLCR_4_Le2ObjMtnChartc "left 2 Objective motion characteristic目标运动特征";
CM_ SG_ 937 RLCR_4_Le2ObjTyp "left 2 Objective type
-00 (Ukwn)： invalid（Unused objects, such as people）";
CM_ SG_ 937 RLCR_4_Le2ObjConf "left 2 Objective confidence目标置信度";
CM_ SG_ 937 RLCR_4_Le2ObjNrOffocst "forecast Number of left 2 Objective  目标预测次数";
CM_ SG_ 937 RLCR_4_Le2ObjTrackSt "left 2 Objective Track state 目标追踪状态";
CM_ SG_ 937 RLCR_4_Le2ObjCoordXDstStdDe "left 2 Objective X coordinates distance standard deviations
x轴距离标准";
CM_ SG_ 937 RLCR_4_Le2ObjCoordYDstStdDe "left 2ObjectiveY coordinates distance standard deviations  y轴距离标准差";
CM_ SG_ 937 RLCR_4_Le2ObjXDirVStdDe "left 2 Objective X directions velocity standard deviations x方向速度标准差";
CM_ SG_ 937 RLCR_4_Le2ObjYDirVStdDe "left 2 Objective Y directions velocity standard deviations y方向速度标准差";
CM_ SG_ 937 RLCR_4_MsgCntr "Rolling message counter(the maximum value of Alive counter is 15)
Note: Details Please refer to specification《EE Standard Specification for CAN FD Network Implementation》section 2.3.1";
CM_ SG_ 937 RLCR_4_CRC "CRC (SAE J1850 CRC-8)
Note: Details Please refer to specification《EE Standard Specification for CAN FD Network Implementation》section 2.3.2";
CM_ SG_ 941 RLCR_5_Le3ObjBoxLen "left 3 Objective Box Length";
CM_ SG_ 941 RLCR_5_Le3ObjBoxWidth "left 3 Objective Box Width";
CM_ SG_ 941 RLCR_5_Le3HdTo "left 3 Head towards";
CM_ SG_ 941 RLCR_5_Le3ObjID "left 3 Objective ID";
CM_ SG_ 941 RLCR_5_Le3ObjCoordY "Y coordinates of left 3 Objective目标物中心位置y轴坐标";
CM_ SG_ 941 RLCR_5_Le3ObjCoordX "X coordinates of  left 3 Objective目标物中心位置x轴坐标";
CM_ SG_ 941 RLCR_5_Le3ObjXDirAV "left 3 Objective X directions Acceleration velocity目标物x方向加速度";
CM_ SG_ 941 RLCR_5_Le3ObjYDirV "left 3 Objective Y directions velocity目标物y方向速度";
CM_ SG_ 941 RLCR_5_Le3ObjXDirV "left 3 Objective X directions velocity目标物x方向速度";
CM_ SG_ 941 RLCR_5_Le3ObjMtnChartc "left 3 Objective motion characteristic目标运动特征";
CM_ SG_ 941 RLCR_5_Le3ObjTyp "left 3 Objective type
-00 (Ukwn)： invalid（Unused objects, such as people）";
CM_ SG_ 941 RLCR_5_Le3ObjConf "left 3 Objective confidence目标置信度";
CM_ SG_ 941 RLCR_5_Le3ObjNrOffocst "forecast Number of left 3 Objective  目标预测次数";
CM_ SG_ 941 RLCR_5_Le3ObjTrackSt "left 3 Objective Track state 目标追踪状态";
CM_ SG_ 941 RLCR_5_Le3ObjCoordXDstStdDe "left 3 Objective X coordinates distance standard deviations
x轴距离标准";
CM_ SG_ 941 RLCR_5_Le3ObjCoordYDstStdDe "left 3 ObjectiveY coordinates distance standard deviations  y轴距离标准差";
CM_ SG_ 941 RLCR_5_Le3ObjXDirVStdDe "left 3 Objective X directions velocity standard deviations x方向速度标准差";
CM_ SG_ 941 RLCR_5_Le3ObjYDirVStdDe "left 3 Objective Y directions velocity standard deviations y方向速度标准差";
CM_ SG_ 941 RLCR_5_MsgCntr "Rolling message counter(the maximum value of Alive counter is 15)
Note: Details Please refer to specification《EE Standard Specification for CAN FD Network Implementation》section 2.3.1";
CM_ SG_ 941 RLCR_5_CRC "CRC (SAE J1850 CRC-8)
Note: Details Please refer to specification《EE Standard Specification for CAN FD Network Implementation》section 2.3.2";
CM_ SG_ 946 RLCR_6_Le4ObjBoxLen "left 4 Objective Box Length";
CM_ SG_ 946 RLCR_6_Le4ObjBoxWidth "left 4 Objective Box Width";
CM_ SG_ 946 RLCR_6_Le4HdTo "left 4 Head towards";
CM_ SG_ 946 RLCR_6_Le4ObjID "left 4 Objective ID";
CM_ SG_ 946 RLCR_6_Le4ObjCoordY "Y coordinates of left 4 Objective目标物中心位置y轴坐标";
CM_ SG_ 946 RLCR_6_Le4ObjCoordX "X coordinates of  left 4 Objective目标物中心位置x轴坐标";
CM_ SG_ 946 RLCR_6_Le4ObjXDirAV "left 4 Objective X directions Acceleration velocity目标物x方向加速度";
CM_ SG_ 946 RLCR_6_Le4ObjYDirV "left 4 Objective Y directions velocity目标物y方向速度";
CM_ SG_ 946 RLCR_6_Le4ObjXDirV "left 4 Objective X directions velocity目标物x方向速度";
CM_ SG_ 946 RLCR_6_Le4ObjMtnChartc "left 4 Objective motion characteristic目标运动特征";
CM_ SG_ 946 RLCR_6_Le4ObjTyp "left 4Objective type
-00 (Ukwn)： invalid（Unused objects, such as people）";
CM_ SG_ 946 RLCR_6_Le4ObjConf "left 4 Objective confidence目标置信度";
CM_ SG_ 946 RLCR_6_Le4ObjNrOffocst "forecast Number of left 4 Objective  目标预测次数";
CM_ SG_ 946 RLCR_6_Le4ObjTrackSt "left 4 Objective Track state 目标追踪状态";
CM_ SG_ 946 RLCR_6_Le4ObjCoordXDstStdDe "left 4 Objective X coordinates distance standard deviations
x轴距离标准";
CM_ SG_ 946 RLCR_6_Le4ObjCoordYDstStdDe "left 4 ObjectiveY coordinates distance standard deviations  y轴距离标准差";
CM_ SG_ 946 RLCR_6_Le4ObjXDirVStdDe "left 4 Objective X directions velocity standard deviations x方向速度标准差";
CM_ SG_ 946 RLCR_6_Le4ObjYDirVStdDe "left 4 Objective Y directions velocity standard deviations y方向速度标准差";
CM_ SG_ 946 RLCR_6_MsgCntr "Rolling message counter(the maximum value of Alive counter is 15)
Note: Details Please refer to specification《EE Standard Specification for CAN FD Network Implementation》section 2.3.1";
CM_ SG_ 946 RLCR_6_CRC "CRC (SAE J1850 CRC-8)
Note: Details Please refer to specification《EE Standard Specification for CAN FD Network Implementation》section 2.3.2";
CM_ SG_ 948 RLCR_7_Le5ObjBoxLen "left 5 Objective Box Length";
CM_ SG_ 948 RLCR_7_Le5ObjBoxWidth "left 5 Objective Box Width";
CM_ SG_ 948 RLCR_7_Le5HdTo "left 5 Head towards";
CM_ SG_ 948 RLCR_7_Le5ObjID "left 5 Objective ID";
CM_ SG_ 948 RLCR_7_Le5ObjCoordY "Y coordinates of left 5 Objective目标物中心位置y轴坐标";
CM_ SG_ 948 RLCR_7_Le5ObjCoordX "X coordinates of  left 5 Objective目标物中心位置x轴坐标";
CM_ SG_ 948 RLCR_7_Le5ObjXDirAV "left 5 Objective X directions Acceleration velocity目标物x方向加速度";
CM_ SG_ 948 RLCR_7_Le5ObjYDirV "left 5 Objective Y directions velocity目标物y方向速度";
CM_ SG_ 948 RLCR_7_Le5ObjXDirV "left 5 Objective X directions velocity目标物x方向速度";
CM_ SG_ 948 RLCR_7_Le5ObjMtnChartc "left 5 Objective motion characteristic目标运动特征";
CM_ SG_ 948 RLCR_7_Le5ObjTyp "left 5 Objective type
-00 (Ukwn)： invalid（Unused objects, such as people）";
CM_ SG_ 948 RLCR_7_Le5ObjConf "left 5 Objective confidence目标置信度";
CM_ SG_ 948 RLCR_7_Le5ObjNrOffocst "forecast Number of left 5 Objective  目标预测次数";
CM_ SG_ 948 RLCR_7_Le5ObjTrackSt "left 5 Objective Track state 目标追踪状态";
CM_ SG_ 948 RLCR_7_Le5ObjCoordXDstStdDe "left 5 Objective X coordinates distance standard deviations
x轴距离标准";
CM_ SG_ 948 RLCR_7_Le5ObjCoordYDstStdDe "left 5 ObjectiveY coordinates distance standard deviations  y轴距离标准差";
CM_ SG_ 948 RLCR_7_Le5ObjXDirVStdDe "left 5 Objective X directions velocity standard deviations x方向速度标准差";
CM_ SG_ 948 RLCR_7_Le5ObjYDirVStdDe "left 5 Objective Y directions velocity standard deviations y方向速度标准差";
CM_ SG_ 948 RLCR_7_MsgCntr "Rolling message counter(the maximum value of Alive counter is 15)
Note: Details Please refer to specification《EE Standard Specification for CAN FD Network Implementation》section 2.3.1";
CM_ SG_ 948 RLCR_7_CRC "CRC (SAE J1850 CRC-8)
Note: Details Please refer to specification《EE Standard Specification for CAN FD Network Implementation》section 2.3.2";
CM_ SG_ 953 RLCR_8_TiStampLaten "timestamp Latency时间戳同步用的延迟，生成目标到发到总线上的时间，提供平均值";
CM_ SG_ 953 RLCR_8_MsgCntr "Rolling message counter(the maximum value of Alive counter is 15)
Note: Details Please refer to specification《EE Standard Specification for CAN FD Network Implementation》section 2.3.1";
CM_ SG_ 953 RLCR_8_CRC "CRC (SAE J1850 CRC-8)
Note: Details Please refer to specification《EE Standard Specification for CAN FD Network Implementation》section 2.3.2";
CM_ SG_ 955 RLCR_9_ObjVldFlg "Left Object valid flag(For Bosch)目标有效位";
CM_ SG_ 955 RLCR_9_LgtDst "Left Longitudinal distance(For Bosch)纵向距离（以车辆后轴中心作为原点）";
CM_ SG_ 955 RLCR_9_LgtRelV "Left Longitudinal relative velocity(For Bosch)   纵向相对速度";
CM_ SG_ 955 RLCR_9_MsgCntr "Rolling message counter(the maximum value of Alive counter is 15)
Note: Details Please refer to specification《EE Standard Specification for CAN FD Network Implementation》section 2.3.1";
CM_ SG_ 955 RLCR_9_CRC "CRC (SAE J1850 CRC-8)
Note: Details Please refer to specification《EE Standard Specification for CAN FD Network Implementation》section 2.3.2";
CM_ SG_ 1203 RRCR_1_SysSt "System State (only for VEONEER)";
CM_ SG_ 1203 RRCR_1_BlkSts "Blockage Status(only for VEONEER)";
CM_ SG_ 1203 RRCR_1_MsgCntr "Rolling message counter(the maximum value of Alive counter is 15)
Note: Details Please refer to specification《EE Standard Specification for CAN FD Network Implementation》section 2.3.1";
CM_ SG_ 1203 RRCR_1_CRC "CRC (SAE J1850 CRC-8)
Note: Details Please refer to specification《EE Standard Specification for CAN FD Network Implementation》section 2.3.2";
CM_ SG_ 959 RRCR_2_Ri1ObjBoxLen "right 1 Objective Box Length";
CM_ SG_ 959 RRCR_2_Ri1ObjBoxWidth "right1 Objective Box Width";
CM_ SG_ 959 RRCR_2_Ri1HdTo "right 1 Head towards";
CM_ SG_ 959 RRCR_2_Ri1ObjID "right1 Objective ID";
CM_ SG_ 959 RRCR_2_Ri1ObjCoordY "Y coordinates of right 1 Objective目标物中心位置y轴坐标";
CM_ SG_ 959 RRCR_2_Ri1ObjCoordX "X coordinates of right1 Objective目标物中心位置x轴坐标";
CM_ SG_ 959 RRCR_2_Ri1ObjXDirAV "right1 Objective X directions Acceleration velocity目标物x方向加速度";
CM_ SG_ 959 RRCR_2_Ri1ObjYDirV "right 1 Objective Y directions velocity目标物y方向速度";
CM_ SG_ 959 RRCR_2_Ri1ObjXDirV "right1 Objective X directions velocity目标物x方向速度";
CM_ SG_ 959 RRCR_2_Ri1ObjMtnChartc "right 1 Objective motion characteristic目标运动特征";
CM_ SG_ 959 RRCR_2_Ri1ObjTyp "right 1 Objective type
-00 (Ukwn)： invalid（Unused objects, such as people）";
CM_ SG_ 959 RRCR_2_Ri1ObjConf "right 1 Objective confidence目标置信度";
CM_ SG_ 959 RRCR_2_Ri1ObjNrOffocst "forecast Number of right 1 Objective  目标预测次数";
CM_ SG_ 959 RRCR_2_Ri1ObjTrackSt "right 1 Objective Track state 目标追踪状态";
CM_ SG_ 959 RRCR_2_Ri1ObjCoordXDstStdDe "right 1 Objective X coordinates distance standard deviations
x轴距离标准";
CM_ SG_ 959 RRCR_2_Ri1ObjCoordYDstStdDe "right1 ObjectiveY coordinates distance standard deviations  y轴距离标准差";
CM_ SG_ 959 RRCR_2_Ri1ObjXDirVStdDe "right 1 Objective X directions velocity standard deviations x方向速度标准差";
CM_ SG_ 959 RRCR_2_Ri1ObjYDirVStdDe "right1 Objective Y directions velocity standard deviations y方向速度标准差";
CM_ SG_ 959 RRCR_2_MsgCntr "Rolling message counter(the maximum value of Alive counter is 15)
Note: Details Please refer to specification《EE Standard Specification for CAN FD Network Implementation》section 2.3.1";
CM_ SG_ 959 RRCR_2_CRC "CRC (SAE J1850 CRC-8)
Note: Details Please refer to specification《EE Standard Specification for CAN FD Network Implementation》section 2.3.2";

BA_DEF_ BO_  "DiagState" ENUM  "No","Yes";
BA_DEF_ BO_  "GenMsgSendType" ENUM  "Cyclic","Event","IfActive","CE","CA","NoMsgSendType";
BA_DEF_ BO_  "GenMsgCycleTime" INT 0 0;
BA_DEF_ SG_  "GenSigSendType" ENUM  "Cyclic","OnChange","OnWrite","IfActive","OnChangeWithRepetition","OnWriteWithRepetition","IfActiveWithRepetition","NoSigSendType","OnChangeAndIfActive","OnChangeAndIfActiveWithRepetition","CA","CE","Event";
BA_DEF_ SG_  "GenSigStartValue" INT 0 0;
BA_DEF_ BO_  "GenMsgCycleTimeFast" INT 0 0;
BA_DEF_ BO_  "GenMsgNrOfRepetition" INT 0 0;
BA_DEF_ BO_  "GenMsgDelayTime" INT 0 0;
BA_DEF_  "DBName" STRING ;
BA_DEF_ BO_  "CANFD_BRS" ENUM  "0","1";
BA_DEF_ BO_  "VFrameFormat" ENUM  "StandardCAN","ExtendedCAN","reserved","reserved","reserved","reserved","reserved","reserved","reserved","reserved","reserved","reserved","reserved","reserved","StandardCAN_FD","ExtendedCAN_FD";
BA_DEF_  "NmMessageCount" INT 0 255;
BA_DEF_ BO_  "GenMsgILSupport" ENUM  "No","Yes";
BA_DEF_  "NmBaseAddress" HEX 1024 1087;
BA_DEF_  "BusType" STRING ;
BA_DEF_ SG_ "GenSigASIL" ENUM "QM","A","B","C","D","";
BA_DEF_DEF_  "DiagState" "No";
BA_DEF_DEF_  "GenMsgSendType" "Cyclic";
BA_DEF_DEF_  "GenMsgCycleTime" 0;
BA_DEF_DEF_  "GenSigSendType" "Cyclic";
BA_DEF_DEF_  "GenSigStartValue" 0;
BA_DEF_DEF_  "GenMsgCycleTimeFast" 0;
BA_DEF_DEF_  "GenMsgNrOfRepetition" 0;
BA_DEF_DEF_  "GenMsgDelayTime" 0;
BA_DEF_DEF_  "DBName" "";
BA_DEF_DEF_  "CANFD_BRS" "1";
BA_DEF_DEF_  "VFrameFormat" "StandardCAN_FD";
BA_DEF_DEF_  "NmMessageCount" 128;
BA_DEF_DEF_  "GenMsgILSupport" "No";
BA_DEF_DEF_  "NmBaseAddress" 1024;
BA_DEF_DEF_  "BusType" "CAN FD";
BA_DEF_DEF_ "GenSigASIL" "QM";
BA_ "DBName" "sadada";
BA_ "GenMsgILSupport" BO_ 775 1;
BA_ "GenMsgCycleTime" BO_ 775 50;
BA_ "GenSigStartValue" SG_ 775 HMA_Status 1;
BA_ "GenSigASIL"  SG_ 775 HMA_Status 5;
BA_ "GenSigASIL"  SG_ 775 HMA_HighbeamReq 5;
BA_ "GenSigASIL"  SG_ 775 FCM_2_Resd1 5;
BA_ "GenSigASIL"  SG_ 775 LDW_ELK_TJA_LDPLeftVisuali 5;
BA_ "GenSigASIL"  SG_ 775 LDW_ELK_TJA_LDPRightVisuali 5;
BA_ "GenSigASIL"  SG_ 775 FCM_2_ISAState 5;
BA_ "GenSigASIL"  SG_ 775 FCM_2_Resd3 5;
BA_ "GenSigASIL"  SG_ 775 FCM_2_Resd4 5;
BA_ "GenSigASIL"  SG_ 775 FCM_2_SCFSpdlimWarn 5;
BA_ "GenSigStartValue" SG_ 775 SLAState 1;
BA_ "GenSigASIL"  SG_ 775 SLAState 5;
BA_ "GenSigASIL"  SG_ 775 SLASpdlimit 5;
BA_ "GenSigASIL"  SG_ 775 FCM_2_Resd6 5;
BA_ "GenSigASIL"  SG_ 775 SLASpdlimitWarning 5;
BA_ "GenSigASIL"  SG_ 775 Camera_textinfo 5;
BA_ "GenSigASIL"  SG_ 775 FCM_2_Resd13 5;
BA_ "GenSigASIL"  SG_ 775 FCM_2_SpdLimtyp 5;
BA_ "GenSigASIL"  SG_ 775 FCM_2_Resd8 5;
BA_ "GenSigASIL"  SG_ 775 TJA_ICA_mode 5;
BA_ "GenSigASIL"  SG_ 775 FCM_2_SLASpdLimChgAud 5;
BA_ "GenSigASIL"  SG_ 775 FCM_2_SLASpdlimitUnits 5;
BA_ "GenSigASIL"  SG_ 775 FCM_2_TJATakeoverReq 5;
BA_ "GenSigASIL"  SG_ 775 SLASpdlimitUnknownWarning 5;
BA_ "GenSigASIL"  SG_ 775 SLASpdlimitWarningVis 5;
BA_ "GenSigASIL"  SG_ 775 SLASpdlimitWarningAud 5;
BA_ "GenSigASIL"  SG_ 775 FCM_2_MessageCounter 5;
BA_ "GenSigASIL"  SG_ 775 FCM_2_CRC 5;
BA_ "GenMsgILSupport" BO_ 837 1;
BA_ "GenMsgCycleTime" BO_ 837 20;
BA_ "GenSigStartValue" SG_ 837 FCM_3_StrngWhlAgReq 15610;
BA_ "GenSigASIL"  SG_ 837 FCM_3_StrngWhlAgReq 5;
BA_ "GenSigASIL"  SG_ 837 FCM_3_StrngWhlAgReqActive 5;
BA_ "GenSigASIL"  SG_ 837 FCM_3_HptcVibReq 5;
BA_ "GenSigASIL"  SG_ 837 FCM_3_AngCtrlTrqUpprLim 5;
BA_ "GenSigStartValue" SG_ 837 FCM_3_AngCtrlTrqLowrLim 100;
BA_ "GenSigASIL"  SG_ 837 FCM_3_AngCtrlTrqLowrLim 5;
BA_ "GenSigASIL"  SG_ 837 FCM_3_ManMachineSharingSts 5;
BA_ "GenSigASIL"  SG_ 837 FCM_3_MsgCntr 5;
BA_ "GenSigASIL"  SG_ 837 FCM_3_CRC 5;
BA_ "GenMsgILSupport" BO_ 1245 1;
BA_ "GenMsgCycleTime" BO_ 1245 100;
BA_ "GenSigStartValue" SG_ 1245 FCM_5_TJAICAExitTextInfoSts 1;
BA_ "GenSigASIL"  SG_ 1245 FCM_5_TJAICAExitTextInfoSts 5;
BA_ "GenSigStartValue" SG_ 1245 FCM_5_SLAONOFFSts 1;
BA_ "GenSigASIL"  SG_ 1245 FCM_5_SLAONOFFSts 5;
BA_ "GenSigStartValue" SG_ 1245 FCM_5_IESONOFFSts 1;
BA_ "GenSigASIL"  SG_ 1245 FCM_5_IESONOFFSts 5;
BA_ "GenSigStartValue" SG_ 1245 FCM_5_HMAONOFFSts 1;
BA_ "GenSigASIL"  SG_ 1245 FCM_5_HMAONOFFSts 5;
BA_ "GenSigStartValue" SG_ 1245 FCM_5_TSIONOFFSts 1;
BA_ "GenSigASIL"  SG_ 1245 FCM_5_TSIONOFFSts 5;
BA_ "GenSigStartValue" SG_ 1245 FCM_5_TLIONOFFSts 1;
BA_ "GenSigASIL"  SG_ 1245 FCM_5_TLIONOFFSts 5;
BA_ "GenSigStartValue" SG_ 1245 FCM_5_LDWONOFFSts 1;
BA_ "GenSigASIL"  SG_ 1245 FCM_5_LDWONOFFSts 5;
BA_ "GenSigStartValue" SG_ 1245 FCM_5_WarnModSts 3;
BA_ "GenSigASIL"  SG_ 1245 FCM_5_WarnModSts 5;
BA_ "GenSigStartValue" SG_ 1245 FCM_5_LDPONOFFSts 2;
BA_ "GenSigASIL"  SG_ 1245 FCM_5_LDPONOFFSts 5;
BA_ "GenSigStartValue" SG_ 1245 FCM_5_LDWLDPSnvtySts 1;
BA_ "GenSigASIL"  SG_ 1245 FCM_5_LDWLDPSnvtySts 5;
BA_ "GenSigStartValue" SG_ 1245 FCM_5_ELKONOFFSts 1;
BA_ "GenSigASIL"  SG_ 1245 FCM_5_ELKONOFFSts 5;
BA_ "GenSigStartValue" SG_ 1245 SLWFONOFFSts 1;
BA_ "GenSigASIL"  SG_ 1245 SLWFONOFFSts 5;
BA_ "GenSigStartValue" SG_ 1245 SLASpdlimitWarningAudSWSts 1;
BA_ "GenSigASIL"  SG_ 1245 SLASpdlimitWarningAudSWSts 5;
BA_ "GenSigStartValue" SG_ 1245 SLASpdLimChgAudSwSts 1;
BA_ "GenSigASIL"  SG_ 1245 SLASpdLimChgAudSwSts 5;
BA_ "GenSigASIL"  SG_ 1245 FCM_5_SpeedLmtNmberAb 5;
BA_ "GenSigASIL"  SG_ 1245 FCM_5_SpeedLmtNmberE 5;
BA_ "GenSigASIL"  SG_ 1245 FCM_5_SLAmodeSWSet 5;
BA_ "GenSigASIL"  SG_ 1245 FCM_5_Resd_1 5;
BA_ "GenSigASIL"  SG_ 1245 FCM_5_MsgCntr 5;
BA_ "GenSigASIL"  SG_ 1245 FCM_5_CRC 5;
BA_ "GenMsgILSupport" BO_ 988 1;
BA_ "GenMsgCycleTime" BO_ 988 50;
BA_ "GenSigASIL"  SG_ 988 FCM_6_EgoLeLineID 5;
BA_ "GenSigASIL"  SG_ 988 FCM_6_EgoLeLineColor 5;
BA_ "GenSigASIL"  SG_ 988 FCM_6_EgoLeLineTyp 5;
BA_ "GenSigStartValue" SG_ 988 FCM_6_EgoLeLineHozlDst 250;
BA_ "GenSigASIL"  SG_ 988 FCM_6_EgoLeLineHozlDst 5;
BA_ "GenSigStartValue" SG_ 988 FCM_6_EgoLeLineCrvt 260;
BA_ "GenSigASIL"  SG_ 988 FCM_6_EgoLeLineCrvt 5;
BA_ "GenSigASIL"  SG_ 988 FCM_6_EgoRiLineID 5;
BA_ "GenSigASIL"  SG_ 988 FCM_6_EgoRiLineColor 5;
BA_ "GenSigASIL"  SG_ 988 FCM_6_EgoRiLineTyp 5;
BA_ "GenSigStartValue" SG_ 988 FCM_6_EgoRiLineHozlDst 250;
BA_ "GenSigASIL"  SG_ 988 FCM_6_EgoRiLineHozlDst 5;
BA_ "GenSigStartValue" SG_ 988 FCM_6_EgoRiLineCrvt 260;
BA_ "GenSigASIL"  SG_ 988 FCM_6_EgoRiLineCrvt 5;
BA_ "GenSigASIL"  SG_ 988 FCM_6_Resd_1 5;
BA_ "GenSigASIL"  SG_ 988 FCM_6_MsgCntr 5;
BA_ "GenSigASIL"  SG_ 988 FCM_6_CRC 5;
BA_ "GenMsgILSupport" BO_ 990 1;
BA_ "GenMsgCycleTime" BO_ 990 50;
BA_ "GenSigASIL"  SG_ 990 FCM_7_NeborLeLineID 5;
BA_ "GenSigASIL"  SG_ 990 FCM_7_NeborLeLineColor 5;
BA_ "GenSigASIL"  SG_ 990 FCM_7_NeborLeLineTyp 5;
BA_ "GenSigStartValue" SG_ 990 FCM_7_NeborLeLineHozlDst 250;
BA_ "GenSigASIL"  SG_ 990 FCM_7_NeborLeLineHozlDst 5;
BA_ "GenSigStartValue" SG_ 990 FCM_7_NeborLeLineCrvt 260;
BA_ "GenSigASIL"  SG_ 990 FCM_7_NeborLeLineCrvt 5;
BA_ "GenSigASIL"  SG_ 990 FCM_7_NeborRiLineID 5;
BA_ "GenSigASIL"  SG_ 990 FCM_7_NeborRiLineColor 5;
BA_ "GenSigASIL"  SG_ 990 FCM_7_NeborRiLineTyp 5;
BA_ "GenSigStartValue" SG_ 990 FCM_7_NeborRiLineHozlDst 250;
BA_ "GenSigASIL"  SG_ 990 FCM_7_NeborRiLineHozlDst 5;
BA_ "GenSigStartValue" SG_ 990 FCM_7_NeborRiLineCrvt 260;
BA_ "GenSigASIL"  SG_ 990 FCM_7_NeborRiLineCrvt 5;
BA_ "GenSigASIL"  SG_ 990 FCM_7_Resd_1 5;
BA_ "GenSigASIL"  SG_ 990 FCM_7_MsgCntr 5;
BA_ "GenSigASIL"  SG_ 990 FCM_7_CRC 5;
BA_ "GenMsgILSupport" BO_ 1005 1;
BA_ "GenMsgCycleTime" BO_ 1005 50;
BA_ "GenSigASIL"  SG_ 1005 FCM_FRM_8_ACCObjID 5;
BA_ "GenSigASIL"  SG_ 1005 FCM_FRM_8_ACCObjTyp 5;
BA_ "GenSigASIL"  SG_ 1005 FCM_FRM_8_ACCObjLgtDstX 5;
BA_ "GenSigStartValue" SG_ 1005 FCM_FRM_8_ACCObjHozDstY 500;
BA_ "GenSigASIL"  SG_ 1005 FCM_FRM_8_ACCObjHozDstY 5;
BA_ "GenSigASIL"  SG_ 1005 FCM_FRM_8_Resd_1 5;
BA_ "GenSigASIL"  SG_ 1005 FCM_FRM_8_FrntFarObjID 5;
BA_ "GenSigASIL"  SG_ 1005 FCM_FRM_8_FrntFarObjTyp 5;
BA_ "GenSigASIL"  SG_ 1005 FCM_FRM_8_FrntFarObjLgtDstX 5;
BA_ "GenSigStartValue" SG_ 1005 FCM_FRM_8_FrntFarObjHozDstY 500;
BA_ "GenSigASIL"  SG_ 1005 FCM_FRM_8_FrntFarObjHozDstY 5;
BA_ "GenSigASIL"  SG_ 1005 FCM_FRM_8_IDSONOFFSts 5;
BA_ "GenSigASIL"  SG_ 1005 FCM_FRM_8_WSOSONOFFSts 5;
BA_ "GenSigASIL"  SG_ 1005 FCM_FRM_8_MsgCntr 5;
BA_ "GenSigASIL"  SG_ 1005 FCM_FRM_8_CRC 5;
BA_ "GenMsgILSupport" BO_ 1018 1;
BA_ "GenMsgCycleTime" BO_ 1018 50;
BA_ "GenSigASIL"  SG_ 1018 FCM_FRM_9_LeObjID 5;
BA_ "GenSigASIL"  SG_ 1018 FCM_FRM_9_LeObjTyp 5;
BA_ "GenSigASIL"  SG_ 1018 FCM_FRM_9_LeObjLgtDstX 5;
BA_ "GenSigStartValue" SG_ 1018 FCM_FRM_9_LeObjHozDstY 500;
BA_ "GenSigASIL"  SG_ 1018 FCM_FRM_9_LeObjHozDstY 5;
BA_ "GenSigASIL"  SG_ 1018 FCM_FRM_9_Resd_1 5;
BA_ "GenSigASIL"  SG_ 1018 FCM_FRM_9_RiObjID 5;
BA_ "GenSigASIL"  SG_ 1018 FCM_FRM_9_RiObjTyp 5;
BA_ "GenSigASIL"  SG_ 1018 FCM_FRM_9_RiObjLgtDstX 5;
BA_ "GenSigStartValue" SG_ 1018 FCM_FRM_9_RiObjHozDstY 500;
BA_ "GenSigASIL"  SG_ 1018 FCM_FRM_9_RiObjHozDstY 5;
BA_ "GenSigASIL"  SG_ 1018 FCM_FRM_9_Resd_2 5;
BA_ "GenSigASIL"  SG_ 1018 FCM_FRM_9_MsgCntr 5;
BA_ "GenSigASIL"  SG_ 1018 FCM_FRM_9_CRC 5;
BA_ "GenMsgILSupport" BO_ 1020 1;
BA_ "GenMsgCycleTime" BO_ 1020 50;
BA_ "GenSigASIL"  SG_ 1020 FCM_10_TSISysSts 5;
BA_ "GenSigASIL"  SG_ 1020 FCM_10_TLISysSts 5;
BA_ "GenSigASIL"  SG_ 1020 FCM_10_TSISgnGiWay 5;
BA_ "GenSigASIL"  SG_ 1020 FCM_10_TSISgnForb 5;
BA_ "GenSigASIL"  SG_ 1020 FCM_10_TSISgnLongStayDisp 5;
BA_ "GenSigASIL"  SG_ 1020 FCM_10_TLITrfcLi 5;
BA_ "GenSigASIL"  SG_ 1020 FCM_10_LDPSysSts 5;
BA_ "GenSigASIL"  SG_ 1020 FCM_10_LDWSysSts 5;
BA_ "GenSigASIL"  SG_ 1020 FCM_10_ELKSysSts 5;
BA_ "GenSigASIL"  SG_ 1020 FCM_10_TSINoParkWarn 5;
BA_ "GenSigASIL"  SG_ 1020 FCM_10_TJAICATextinfo 5;
BA_ "GenSigASIL"  SG_ 1020 FCM_10_TJAICAEnaRcmend 5;
BA_ "GenSigASIL"  SG_ 1020 FCM_10_LDPTJAELKTakeoverReq 5;
BA_ "GenSigStartValue" SG_ 1020 FCM_10_TJAICAExitTextInfoSts 1;
BA_ "GenSigASIL"  SG_ 1020 FCM_10_TJAICAExitTextInfoSts 5;
BA_ "GenSigStartValue" SG_ 1020 FCM_10_SLAONOFFSts 1;
BA_ "GenSigASIL"  SG_ 1020 FCM_10_SLAONOFFSts 5;
BA_ "GenSigStartValue" SG_ 1020 FCM_10_WarnModSts 3;
BA_ "GenSigASIL"  SG_ 1020 FCM_10_WarnModSts 5;
BA_ "GenSigASIL"  SG_ 1020 FCM_10_ELKIntvMod 5;
BA_ "GenSigStartValue" SG_ 1020 FCM_10_EgoLeftLineHeatgAg 255;
BA_ "GenSigASIL"  SG_ 1020 FCM_10_EgoLeftLineHeatgAg 5;
BA_ "GenSigASIL"  SG_ 1020 FCM_10_MsgCntr 5;
BA_ "GenSigASIL"  SG_ 1020 FCM_10_CRC 5;
BA_ "GenMsgILSupport" BO_ 930 1;
BA_ "GenMsgCycleTime" BO_ 930 20;
BA_ "GenSigASIL"  SG_ 930 ACCTarAcc 5;
BA_ "GenSigStartValue" SG_ 930 VLCShutdownMode 3;
BA_ "GenSigASIL"  SG_ 930 VLCShutdownMode 5;
BA_ "GenSigASIL"  SG_ 930 ACCMode_ESP 5;
BA_ "GenSigASIL"  SG_ 930 ComfortAccUpperValue 5;
BA_ "GenSigASIL"  SG_ 930 BrakePreferred 5;
BA_ "GenSigASIL"  SG_ 930 ComfortAccLowerValue 5;
BA_ "GenSigASIL"  SG_ 930 DriveOff 5;
BA_ "GenSigASIL"  SG_ 930 LimitAccUpperValue 5;
BA_ "GenSigASIL"  SG_ 930 DecToStop 5;
BA_ "GenSigASIL"  SG_ 930 LimitAccLowerValue 5;
BA_ "GenSigASIL"  SG_ 930 ACC_AccECGPOvrd 5;
BA_ "GenSigASIL"  SG_ 930 HBALevel 5;
BA_ "GenSigASIL"  SG_ 930 HBARequest 5;
BA_ "GenSigASIL"  SG_ 930 PrefillRequest 5;
BA_ "GenSigASIL"  SG_ 930 FCM_FRM_1_MessageCounter 5;
BA_ "GenSigASIL"  SG_ 930 FCM_FRM_1_CRC 5;
BA_ "GenMsgILSupport" BO_ 933 1;
BA_ "GenMsgCycleTime" BO_ 933 20;
BA_ "GenSigASIL"  SG_ 933 AEBTarDec 5;
BA_ "GenSigASIL"  SG_ 933 AEBDecCtrlRequest 5;
BA_ "GenSigASIL"  SG_ 933 ACCMinimumBraking 5;
BA_ "GenSigASIL"  SG_ 933 ACCStartStopInfo 5;
BA_ "GenSigASIL"  SG_ 933 AEBReq 5;
BA_ "GenSigASIL"  SG_ 933 FCM_FRM_2_Reserved1 5;
BA_ "GenSigASIL"  SG_ 933 AWBRequest 5;
BA_ "GenSigASIL"  SG_ 933 AWBLevel 5;
BA_ "GenSigASIL"  SG_ 933 FCM_FRM_2_Textinfo_Info 5;
BA_ "GenSigASIL"  SG_ 933 FCM_FRM_2_Reserved2 5;
BA_ "GenSigASIL"  SG_ 933 FCM_FRM_2_MessageCounter 5;
BA_ "GenSigASIL"  SG_ 933 FCM_FRM_2_CRC 5;
BA_ "GenMsgILSupport" BO_ 773 1;
BA_ "GenMsgCycleTime" BO_ 773 50;
BA_ "GenSigASIL"  SG_ 773 FCM_FRM_3_Resd1 5;
BA_ "GenSigASIL"  SG_ 773 FCM_FRM_3_Resd2 5;
BA_ "GenSigASIL"  SG_ 773 FCM_FRM_3_Resd3 5;
BA_ "GenSigASIL"  SG_ 773 FCM_FRM_3_Resd4 5;
BA_ "GenSigASIL"  SG_ 773 Textinfo 5;
BA_ "GenSigASIL"  SG_ 773 FCM_FRM_3_Resd6 5;
BA_ "GenSigASIL"  SG_ 773 FCM_FRM_3_Resd7 5;
BA_ "GenSigASIL"  SG_ 773 FCM_FRM_3_Resd8 5;
BA_ "GenSigASIL"  SG_ 773 FCM_FRM_3_Resd9 5;
BA_ "GenSigASIL"  SG_ 773 ACCModeDummy 5;
BA_ "GenSigASIL"  SG_ 773 FCM_FRM_3_Resd10 5;
BA_ "GenSigASIL"  SG_ 773 FCM_FRM_3_Resd11 5;
BA_ "GenSigASIL"  SG_ 773 FCM_FRM_3_Resd12 5;
BA_ "GenSigASIL"  SG_ 773 FCM_FRM_3_Resd13 5;
BA_ "GenSigASIL"  SG_ 773 FCM_FRM_3_Resd14 5;
BA_ "GenSigASIL"  SG_ 773 FCM_FRM_3_Resd15 5;
BA_ "GenSigASIL"  SG_ 773 FCM_FRM_3_Resd16 5;
BA_ "GenSigASIL"  SG_ 773 FCM_FRM_3_Resd17 5;
BA_ "GenSigASIL"  SG_ 773 FCM_FRM_3_Resd18 5;
BA_ "GenSigASIL"  SG_ 773 FCM_FRM_3_MessageCounter 5;
BA_ "GenSigASIL"  SG_ 773 FCM_FRM_3_CRC 5;
BA_ "GenMsgILSupport" BO_ 1251 1;
BA_ "GenMsgCycleTime" BO_ 1251 100;
BA_ "GenSigStartValue" SG_ 1251 FCM_FRM_5_AEBONOFFSts 1;
BA_ "GenSigASIL"  SG_ 1251 FCM_FRM_5_AEBONOFFSts 5;
BA_ "GenSigStartValue" SG_ 1251 FCM_FRM_5_FCWSnvtySts 1;
BA_ "GenSigASIL"  SG_ 1251 FCM_FRM_5_FCWSnvtySts 5;
BA_ "GenSigStartValue" SG_ 1251 FCM_FRM_5_FCWONOFFSts 1;
BA_ "GenSigASIL"  SG_ 1251 FCM_FRM_5_FCWONOFFSts 5;
BA_ "GenSigStartValue" SG_ 1251 FCM_FRM_5_SCFONOFFSts 1;
BA_ "GenSigASIL"  SG_ 1251 FCM_FRM_5_SCFONOFFSts 5;
BA_ "GenSigStartValue" SG_ 1251 FCM_FRM_5_DAIONOFFSts 1;
BA_ "GenSigASIL"  SG_ 1251 FCM_FRM_5_DAIONOFFSts 5;
BA_ "GenSigASIL"  SG_ 1251 FCM_FRM_5_Resd_1 5;
BA_ "GenSigASIL"  SG_ 1251 FCM_FRM_5_MsgCntr 5;
BA_ "GenSigASIL"  SG_ 1251 FCM_FRM_5_CRC 5;
BA_ "GenMsgILSupport" BO_ 903 1;
BA_ "GenMsgCycleTime" BO_ 903 50;
BA_ "GenSigASIL"  SG_ 903 FCM_FRM_6_Textinfo_Info 5;
BA_ "GenSigASIL"  SG_ 903 FCM_FRM_6_TextinfoWarn 5;
BA_ "GenSigASIL"  SG_ 903 FCM_FRM_6_Textinfo_Info_2 5;
BA_ "GenSigASIL"  SG_ 903 FCM_FRM_6_TimeGapSetICM 5;
BA_ "GenSigASIL"  SG_ 903 FCM_FRM_6_SCF_PopoverReq 5;
BA_ "GenSigASIL"  SG_ 903 FCM_FRM_6_SCF_SpdLimSts 5;
BA_ "GenSigASIL"  SG_ 903 FCM_FRM_6_SCF_SpdLimUnit 5;
BA_ "GenSigASIL"  SG_ 903 FCM_FRM_6_DrvrCfmSCFDispFb 5;
BA_ "GenSigASIL"  SG_ 903 FCM_FRM_6_DistanceWarning 5;
BA_ "GenSigASIL"  SG_ 903 FCM_FRM_6_FCW_preWarning 5;
BA_ "GenSigASIL"  SG_ 903 FCM_FRM_6_TakeOverReq 5;
BA_ "GenSigStartValue" SG_ 903 FCM_FRM_6_FCWMode 1;
BA_ "GenSigASIL"  SG_ 903 FCM_FRM_6_FCWMode 5;
BA_ "GenSigStartValue" SG_ 903 FCM_FRM_6_AEBMode 1;
BA_ "GenSigASIL"  SG_ 903 FCM_FRM_6_AEBMode 5;
BA_ "GenSigASIL"  SG_ 903 FCM_FRM_6_AEBDecCtrlRequest 5;
BA_ "GenSigASIL"  SG_ 903 FCM_FRM_6_HMI_Indicator 5;
BA_ "GenSigASIL"  SG_ 903 FCM_FRM_6_ACCMode 5;
BA_ "GenSigASIL"  SG_ 903 FCM_FRM_6_SCF_Indicator 5;
BA_ "GenSigASIL"  SG_ 903 FCM_FRM_6_VSetDis 5;
BA_ "GenSigASIL"  SG_ 903 FCM_FRM_6_MsgCntr 5;
BA_ "GenSigASIL"  SG_ 903 FCM_FRM_6_CRC 5;
BA_ "GenMsgILSupport" BO_ 943 1;
BA_ "GenMsgCycleTime" BO_ 943 50;
BA_ "GenSigASIL"  SG_ 943 IDCU_1_AmbLi 5;
BA_ "GenSigStartValue" SG_ 943 IDCU_1_HozlPosnRi 430;
BA_ "GenSigASIL"  SG_ 943 IDCU_1_HozlPosnRi 5;
BA_ "GenSigStartValue" SG_ 943 IDCU_1_HozlPosnLe 430;
BA_ "GenSigASIL"  SG_ 943 IDCU_1_HozlPosnLe 5;
BA_ "GenSigASIL"  SG_ 943 IDCU_1_ObjN1Dst 5;
BA_ "GenSigASIL"  SG_ 943 IDCU_1_reserved_1 5;
BA_ "GenSigASIL"  SG_ 943 IDCU_1_ObjN1_Type 5;
BA_ "GenSigASIL"  SG_ 943 IDCU_1_reserved_2 5;
BA_ "GenSigASIL"  SG_ 943 IDCU_1_MsgCntr 5;
BA_ "GenSigASIL"  SG_ 943 IDCU_1_CRC 5;
BA_ "GenMsgILSupport" BO_ 949 1;
BA_ "GenMsgCycleTime" BO_ 949 50;
BA_ "GenSigASIL"  SG_ 949 IDCU_2_FCMStForADB 5;
BA_ "GenSigASIL"  SG_ 949 IDCU_2_reserved_1 5;
BA_ "GenSigStartValue" SG_ 949 IDCU_2_HozlPosnRi 430;
BA_ "GenSigASIL"  SG_ 949 IDCU_2_HozlPosnRi 5;
BA_ "GenSigStartValue" SG_ 949 IDCU_2_HozlPosnLe 430;
BA_ "GenSigASIL"  SG_ 949 IDCU_2_HozlPosnLe 5;
BA_ "GenSigASIL"  SG_ 949 IDCU_2_ObjN1Dst 5;
BA_ "GenSigASIL"  SG_ 949 IDCU_2_reserved_2 5;
BA_ "GenSigASIL"  SG_ 949 IDCU_2_ObjN2_Type 5;
BA_ "GenSigASIL"  SG_ 949 IDCU_2_reserved_3 5;
BA_ "GenSigASIL"  SG_ 949 IDCU_2_MsgCntr 5;
BA_ "GenSigASIL"  SG_ 949 IDCU_2_CRC 5;
BA_ "GenMsgILSupport" BO_ 957 1;
BA_ "GenMsgCycleTime" BO_ 957 50;
BA_ "GenSigASIL"  SG_ 957 IDCU_3_reserved_1 5;
BA_ "GenSigStartValue" SG_ 957 IDCU_3_HozlPosnRi 430;
BA_ "GenSigASIL"  SG_ 957 IDCU_3_HozlPosnRi 5;
BA_ "GenSigStartValue" SG_ 957 IDCU_3_HozlPosnLe 430;
BA_ "GenSigASIL"  SG_ 957 IDCU_3_HozlPosnLe 5;
BA_ "GenSigASIL"  SG_ 957 IDCU_3_ObjN3Dst 5;
BA_ "GenSigASIL"  SG_ 957 IDCU_3_reserved_2 5;
BA_ "GenSigASIL"  SG_ 957 IDCU_3_ObjN3_Type 5;
BA_ "GenSigASIL"  SG_ 957 IDCU_3_reserved_3 5;
BA_ "GenSigASIL"  SG_ 957 IDCU_3_MsgCntr 5;
BA_ "GenSigASIL"  SG_ 957 IDCU_3_CRC 5;
BA_ "GenMsgILSupport" BO_ 974 1;
BA_ "GenMsgCycleTime" BO_ 974 50;
BA_ "GenSigASIL"  SG_ 974 IDCU_4_reserved_1 5;
BA_ "GenSigStartValue" SG_ 974 IDCU_4_HozlPosnRi 430;
BA_ "GenSigASIL"  SG_ 974 IDCU_4_HozlPosnRi 5;
BA_ "GenSigStartValue" SG_ 974 IDCU_4_HozlPosnLe 430;
BA_ "GenSigASIL"  SG_ 974 IDCU_4_HozlPosnLe 5;
BA_ "GenSigASIL"  SG_ 974 IDCU_4_ObjN4Dst 5;
BA_ "GenSigASIL"  SG_ 974 IDCU_4_reserved_2 5;
BA_ "GenSigASIL"  SG_ 974 IDCU_4_ObjN4_Type 5;
BA_ "GenSigASIL"  SG_ 974 IDCU_4_reserved_3 5;
BA_ "GenSigASIL"  SG_ 974 IDCU_4_MsgCntr 5;
BA_ "GenSigASIL"  SG_ 974 IDCU_4_CRC 5;
BA_ "GenMsgILSupport" BO_ 981 1;
BA_ "GenMsgCycleTime" BO_ 981 50;
BA_ "GenSigASIL"  SG_ 981 IDCU_5_reserved_1 5;
BA_ "GenSigStartValue" SG_ 981 IDCU_5_HozlPosnRi 430;
BA_ "GenSigASIL"  SG_ 981 IDCU_5_HozlPosnRi 5;
BA_ "GenSigStartValue" SG_ 981 IDCU_5_HozlPosnLe 430;
BA_ "GenSigASIL"  SG_ 981 IDCU_5_HozlPosnLe 5;
BA_ "GenSigASIL"  SG_ 981 IDCU_5_ObjN5Dst 5;
BA_ "GenSigASIL"  SG_ 981 IDCU_5_reserved_2 5;
BA_ "GenSigASIL"  SG_ 981 IDCU_5_ObjN5_Type 5;
BA_ "GenSigASIL"  SG_ 981 IDCU_5_reserved_3 5;
BA_ "GenSigASIL"  SG_ 981 IDCU_5_MsgCntr 5;
BA_ "GenSigASIL"  SG_ 981 IDCU_5_CRC 5;
BA_ "GenMsgILSupport" BO_ 1001 1;
BA_ "GenMsgCycleTime" BO_ 1001 50;
BA_ "GenSigASIL"  SG_ 1001 IDCU_6_reserved_1 5;
BA_ "GenSigStartValue" SG_ 1001 IDCU_6_HozlPosnRi 430;
BA_ "GenSigASIL"  SG_ 1001 IDCU_6_HozlPosnRi 5;
BA_ "GenSigStartValue" SG_ 1001 IDCU_6_HozlPosnLe 430;
BA_ "GenSigASIL"  SG_ 1001 IDCU_6_HozlPosnLe 5;
BA_ "GenSigASIL"  SG_ 1001 IDCU_6_ObjN6Dst 5;
BA_ "GenSigASIL"  SG_ 1001 IDCU_6_reserved_2 5;
BA_ "GenSigASIL"  SG_ 1001 IDCU_6_ObjN6_Type 5;
BA_ "GenSigASIL"  SG_ 1001 IDCU_6_reserved_3 5;
BA_ "GenSigASIL"  SG_ 1001 IDCU_6_MsgCntr 5;
BA_ "GenSigASIL"  SG_ 1001 IDCU_6_CRC 5;
BA_ "GenMsgILSupport" BO_ 1003 1;
BA_ "GenMsgCycleTime" BO_ 1003 50;
BA_ "GenSigASIL"  SG_ 1003 IDCU_7_reserved_1 5;
BA_ "GenSigStartValue" SG_ 1003 IDCU_7_HozlPosnRi 430;
BA_ "GenSigASIL"  SG_ 1003 IDCU_7_HozlPosnRi 5;
BA_ "GenSigStartValue" SG_ 1003 IDCU_7_HozlPosnLe 430;
BA_ "GenSigASIL"  SG_ 1003 IDCU_7_HozlPosnLe 5;
BA_ "GenSigASIL"  SG_ 1003 IDCU_7_ObjN7Dst 5;
BA_ "GenSigASIL"  SG_ 1003 IDCU_7_reserved_2 5;
BA_ "GenSigASIL"  SG_ 1003 IDCU_7_ObjN7_Type 5;
BA_ "GenSigASIL"  SG_ 1003 IDCU_7_reserved_3 5;
BA_ "GenSigASIL"  SG_ 1003 IDCU_7_MsgCntr 5;
BA_ "GenSigASIL"  SG_ 1003 IDCU_7_CRC 5;
BA_ "GenMsgILSupport" BO_ 1013 1;
BA_ "GenMsgCycleTime" BO_ 1013 50;
BA_ "GenSigASIL"  SG_ 1013 IDCU_8_reserved_1 5;
BA_ "GenSigStartValue" SG_ 1013 IDCU_8_HozlPosnRi 430;
BA_ "GenSigASIL"  SG_ 1013 IDCU_8_HozlPosnRi 5;
BA_ "GenSigStartValue" SG_ 1013 IDCU_8_HozlPosnLe 430;
BA_ "GenSigASIL"  SG_ 1013 IDCU_8_HozlPosnLe 5;
BA_ "GenSigASIL"  SG_ 1013 IDCU_8_ObjN6Dst 5;
BA_ "GenSigASIL"  SG_ 1013 IDCU_8_reserved_2 5;
BA_ "GenSigASIL"  SG_ 1013 IDCU_8_ObjN8_Type 5;
BA_ "GenSigASIL"  SG_ 1013 IDCU_8_reserved_3 5;
BA_ "GenSigASIL"  SG_ 1013 IDCU_8_MsgCntr 5;
BA_ "GenSigASIL"  SG_ 1013 IDCU_8_CRC 5;
BA_ "GenMsgILSupport" BO_ 1201 1;
BA_ "GenMsgCycleTime" BO_ 1201 100;
BA_ "GenSigASIL"  SG_ 1201 RLCR_1_SysSt 5;
BA_ "GenSigASIL"  SG_ 1201 RLCR_1_ELKSts 5;
BA_ "GenSigASIL"  SG_ 1201 RLCR_1_BlkSts 5;
BA_ "GenSigASIL"  SG_ 1201 RLCR_1_MsgCntr 5;
BA_ "GenSigASIL"  SG_ 1201 RLCR_1_CRC 5;
BA_ "GenMsgILSupport" BO_ 935 1;
BA_ "GenMsgCycleTime" BO_ 935 50;
BA_ "GenSigASIL"  SG_ 935 RLCR_3_Le1ObjBoxLen 5;
BA_ "GenSigASIL"  SG_ 935 RLCR_3_Le1ObjBoxWidth 5;
BA_ "GenSigStartValue" SG_ 935 RLCR_3_Le1HdTo 1800;
BA_ "GenSigASIL"  SG_ 935 RLCR_3_Le1HdTo 5;
BA_ "GenSigASIL"  SG_ 935 RLCR_3_Le1ObjID 5;
BA_ "GenSigStartValue" SG_ 935 RLCR_3_Le1ObjCoordY 4000;
BA_ "GenSigASIL"  SG_ 935 RLCR_3_Le1ObjCoordY 5;
BA_ "GenSigStartValue" SG_ 935 RLCR_3_Le1ObjCoordX 4000;
BA_ "GenSigASIL"  SG_ 935 RLCR_3_Le1ObjCoordX 5;
BA_ "GenSigStartValue" SG_ 935 RLCR_3_Le1ObjXDirAV 128;
BA_ "GenSigASIL"  SG_ 935 RLCR_3_Le1ObjXDirAV 5;
BA_ "GenSigStartValue" SG_ 935 RLCR_3_Le1ObjYDirV 6400;
BA_ "GenSigASIL"  SG_ 935 RLCR_3_Le1ObjYDirV 5;
BA_ "GenSigStartValue" SG_ 935 RLCR_3_Le1ObjXDirV 6400;
BA_ "GenSigASIL"  SG_ 935 RLCR_3_Le1ObjXDirV 5;
BA_ "GenSigASIL"  SG_ 935 RLCR_3_Le1ObjMtnChartc 5;
BA_ "GenSigASIL"  SG_ 935 RLCR_3_Le1ObjTyp 5;
BA_ "GenSigASIL"  SG_ 935 RLCR_3_Le1ObjConf 5;
BA_ "GenSigStartValue" SG_ 935 RLCR_3_Le1ObjNrOffocst 31;
BA_ "GenSigASIL"  SG_ 935 RLCR_3_Le1ObjNrOffocst 5;
BA_ "GenSigASIL"  SG_ 935 RLCR_3_Le1ObjTrackSt 5;
BA_ "GenSigASIL"  SG_ 935 RLCR_3_Le1ObjCoordXDstStdDe 5;
BA_ "GenSigASIL"  SG_ 935 RLCR_3_Le1ObjCoordYDstStdDe 5;
BA_ "GenSigASIL"  SG_ 935 RLCR_3_Le1ObjXDirVStdDe 5;
BA_ "GenSigASIL"  SG_ 935 RLCR_3_Le1ObjYDirVStdDe 5;
BA_ "GenSigASIL"  SG_ 935 RLCR_3_MsgCntr 5;
BA_ "GenSigASIL"  SG_ 935 RLCR_3_CRC 5;
BA_ "GenMsgILSupport" BO_ 937 1;
BA_ "GenMsgCycleTime" BO_ 937 50;
BA_ "GenSigASIL"  SG_ 937 RLCR_4_Le2ObjBoxLen 5;
BA_ "GenSigASIL"  SG_ 937 RLCR_4_Le2ObjBoxWidth 5;
BA_ "GenSigStartValue" SG_ 937 RLCR_4_Le2HdTo 1800;
BA_ "GenSigASIL"  SG_ 937 RLCR_4_Le2HdTo 5;
BA_ "GenSigASIL"  SG_ 937 RLCR_4_Le2ObjID 5;
BA_ "GenSigStartValue" SG_ 937 RLCR_4_Le2ObjCoordY 4000;
BA_ "GenSigASIL"  SG_ 937 RLCR_4_Le2ObjCoordY 5;
BA_ "GenSigStartValue" SG_ 937 RLCR_4_Le2ObjCoordX 4000;
BA_ "GenSigASIL"  SG_ 937 RLCR_4_Le2ObjCoordX 5;
BA_ "GenSigStartValue" SG_ 937 RLCR_4_Le2ObjXDirAV 128;
BA_ "GenSigASIL"  SG_ 937 RLCR_4_Le2ObjXDirAV 5;
BA_ "GenSigStartValue" SG_ 937 RLCR_4_Le2ObjYDirV 6400;
BA_ "GenSigASIL"  SG_ 937 RLCR_4_Le2ObjYDirV 5;
BA_ "GenSigStartValue" SG_ 937 RLCR_4_Le2ObjXDirV 6400;
BA_ "GenSigASIL"  SG_ 937 RLCR_4_Le2ObjXDirV 5;
BA_ "GenSigASIL"  SG_ 937 RLCR_4_Le2ObjMtnChartc 5;
BA_ "GenSigASIL"  SG_ 937 RLCR_4_Le2ObjTyp 5;
BA_ "GenSigASIL"  SG_ 937 RLCR_4_Le2ObjConf 5;
BA_ "GenSigStartValue" SG_ 937 RLCR_4_Le2ObjNrOffocst 31;
BA_ "GenSigASIL"  SG_ 937 RLCR_4_Le2ObjNrOffocst 5;
BA_ "GenSigASIL"  SG_ 937 RLCR_4_Le2ObjTrackSt 5;
BA_ "GenSigASIL"  SG_ 937 RLCR_4_Le2ObjCoordXDstStdDe 5;
BA_ "GenSigASIL"  SG_ 937 RLCR_4_Le2ObjCoordYDstStdDe 5;
BA_ "GenSigASIL"  SG_ 937 RLCR_4_Le2ObjXDirVStdDe 5;
BA_ "GenSigASIL"  SG_ 937 RLCR_4_Le2ObjYDirVStdDe 5;
BA_ "GenSigASIL"  SG_ 937 RLCR_4_MsgCntr 5;
BA_ "GenSigASIL"  SG_ 937 RLCR_4_CRC 5;
BA_ "GenMsgILSupport" BO_ 941 1;
BA_ "GenMsgCycleTime" BO_ 941 50;
BA_ "GenSigASIL"  SG_ 941 RLCR_5_Le3ObjBoxLen 5;
BA_ "GenSigASIL"  SG_ 941 RLCR_5_Le3ObjBoxWidth 5;
BA_ "GenSigStartValue" SG_ 941 RLCR_5_Le3HdTo 1800;
BA_ "GenSigASIL"  SG_ 941 RLCR_5_Le3HdTo 5;
BA_ "GenSigASIL"  SG_ 941 RLCR_5_Le3ObjID 5;
BA_ "GenSigStartValue" SG_ 941 RLCR_5_Le3ObjCoordY 4000;
BA_ "GenSigASIL"  SG_ 941 RLCR_5_Le3ObjCoordY 5;
BA_ "GenSigStartValue" SG_ 941 RLCR_5_Le3ObjCoordX 4000;
BA_ "GenSigASIL"  SG_ 941 RLCR_5_Le3ObjCoordX 5;
BA_ "GenSigStartValue" SG_ 941 RLCR_5_Le3ObjXDirAV 128;
BA_ "GenSigASIL"  SG_ 941 RLCR_5_Le3ObjXDirAV 5;
BA_ "GenSigStartValue" SG_ 941 RLCR_5_Le3ObjYDirV 6400;
BA_ "GenSigASIL"  SG_ 941 RLCR_5_Le3ObjYDirV 5;
BA_ "GenSigStartValue" SG_ 941 RLCR_5_Le3ObjXDirV 6400;
BA_ "GenSigASIL"  SG_ 941 RLCR_5_Le3ObjXDirV 5;
BA_ "GenSigASIL"  SG_ 941 RLCR_5_Le3ObjMtnChartc 5;
BA_ "GenSigASIL"  SG_ 941 RLCR_5_Le3ObjTyp 5;
BA_ "GenSigASIL"  SG_ 941 RLCR_5_Le3ObjConf 5;
BA_ "GenSigStartValue" SG_ 941 RLCR_5_Le3ObjNrOffocst 31;
BA_ "GenSigASIL"  SG_ 941 RLCR_5_Le3ObjNrOffocst 5;
BA_ "GenSigASIL"  SG_ 941 RLCR_5_Le3ObjTrackSt 5;
BA_ "GenSigASIL"  SG_ 941 RLCR_5_Le3ObjCoordXDstStdDe 5;
BA_ "GenSigASIL"  SG_ 941 RLCR_5_Le3ObjCoordYDstStdDe 5;
BA_ "GenSigASIL"  SG_ 941 RLCR_5_Le3ObjXDirVStdDe 5;
BA_ "GenSigASIL"  SG_ 941 RLCR_5_Le3ObjYDirVStdDe 5;
BA_ "GenSigASIL"  SG_ 941 RLCR_5_MsgCntr 5;
BA_ "GenSigASIL"  SG_ 941 RLCR_5_CRC 5;
BA_ "GenMsgILSupport" BO_ 946 1;
BA_ "GenMsgCycleTime" BO_ 946 50;
BA_ "GenSigASIL"  SG_ 946 RLCR_6_Le4ObjBoxLen 5;
BA_ "GenSigASIL"  SG_ 946 RLCR_6_Le4ObjBoxWidth 5;
BA_ "GenSigStartValue" SG_ 946 RLCR_6_Le4HdTo 1800;
BA_ "GenSigASIL"  SG_ 946 RLCR_6_Le4HdTo 5;
BA_ "GenSigASIL"  SG_ 946 RLCR_6_Le4ObjID 5;
BA_ "GenSigStartValue" SG_ 946 RLCR_6_Le4ObjCoordY 4000;
BA_ "GenSigASIL"  SG_ 946 RLCR_6_Le4ObjCoordY 5;
BA_ "GenSigStartValue" SG_ 946 RLCR_6_Le4ObjCoordX 4000;
BA_ "GenSigASIL"  SG_ 946 RLCR_6_Le4ObjCoordX 5;
BA_ "GenSigStartValue" SG_ 946 RLCR_6_Le4ObjXDirAV 128;
BA_ "GenSigASIL"  SG_ 946 RLCR_6_Le4ObjXDirAV 5;
BA_ "GenSigStartValue" SG_ 946 RLCR_6_Le4ObjYDirV 6400;
BA_ "GenSigASIL"  SG_ 946 RLCR_6_Le4ObjYDirV 5;
BA_ "GenSigStartValue" SG_ 946 RLCR_6_Le4ObjXDirV 6400;
BA_ "GenSigASIL"  SG_ 946 RLCR_6_Le4ObjXDirV 5;
BA_ "GenSigASIL"  SG_ 946 RLCR_6_Le4ObjMtnChartc 5;
BA_ "GenSigASIL"  SG_ 946 RLCR_6_Le4ObjTyp 5;
BA_ "GenSigASIL"  SG_ 946 RLCR_6_Le4ObjConf 5;
BA_ "GenSigStartValue" SG_ 946 RLCR_6_Le4ObjNrOffocst 31;
BA_ "GenSigASIL"  SG_ 946 RLCR_6_Le4ObjNrOffocst 5;
BA_ "GenSigASIL"  SG_ 946 RLCR_6_Le4ObjTrackSt 5;
BA_ "GenSigASIL"  SG_ 946 RLCR_6_Le4ObjCoordXDstStdDe 5;
BA_ "GenSigASIL"  SG_ 946 RLCR_6_Le4ObjCoordYDstStdDe 5;
BA_ "GenSigASIL"  SG_ 946 RLCR_6_Le4ObjXDirVStdDe 5;
BA_ "GenSigASIL"  SG_ 946 RLCR_6_Le4ObjYDirVStdDe 5;
BA_ "GenSigASIL"  SG_ 946 RLCR_6_MsgCntr 5;
BA_ "GenSigASIL"  SG_ 946 RLCR_6_CRC 5;
BA_ "GenMsgILSupport" BO_ 948 1;
BA_ "GenMsgCycleTime" BO_ 948 50;
BA_ "GenSigASIL"  SG_ 948 RLCR_7_Le5ObjBoxLen 5;
BA_ "GenSigASIL"  SG_ 948 RLCR_7_Le5ObjBoxWidth 5;
BA_ "GenSigStartValue" SG_ 948 RLCR_7_Le5HdTo 1800;
BA_ "GenSigASIL"  SG_ 948 RLCR_7_Le5HdTo 5;
BA_ "GenSigASIL"  SG_ 948 RLCR_7_Le5ObjID 5;
BA_ "GenSigStartValue" SG_ 948 RLCR_7_Le5ObjCoordY 4000;
BA_ "GenSigASIL"  SG_ 948 RLCR_7_Le5ObjCoordY 5;
BA_ "GenSigStartValue" SG_ 948 RLCR_7_Le5ObjCoordX 4000;
BA_ "GenSigASIL"  SG_ 948 RLCR_7_Le5ObjCoordX 5;
BA_ "GenSigStartValue" SG_ 948 RLCR_7_Le5ObjXDirAV 128;
BA_ "GenSigASIL"  SG_ 948 RLCR_7_Le5ObjXDirAV 5;
BA_ "GenSigStartValue" SG_ 948 RLCR_7_Le5ObjYDirV 6400;
BA_ "GenSigASIL"  SG_ 948 RLCR_7_Le5ObjYDirV 5;
BA_ "GenSigStartValue" SG_ 948 RLCR_7_Le5ObjXDirV 6400;
BA_ "GenSigASIL"  SG_ 948 RLCR_7_Le5ObjXDirV 5;
BA_ "GenSigASIL"  SG_ 948 RLCR_7_Le5ObjMtnChartc 5;
BA_ "GenSigASIL"  SG_ 948 RLCR_7_Le5ObjTyp 5;
BA_ "GenSigASIL"  SG_ 948 RLCR_7_Le5ObjConf 5;
BA_ "GenSigStartValue" SG_ 948 RLCR_7_Le5ObjNrOffocst 31;
BA_ "GenSigASIL"  SG_ 948 RLCR_7_Le5ObjNrOffocst 5;
BA_ "GenSigASIL"  SG_ 948 RLCR_7_Le5ObjTrackSt 5;
BA_ "GenSigASIL"  SG_ 948 RLCR_7_Le5ObjCoordXDstStdDe 5;
BA_ "GenSigASIL"  SG_ 948 RLCR_7_Le5ObjCoordYDstStdDe 5;
BA_ "GenSigASIL"  SG_ 948 RLCR_7_Le5ObjXDirVStdDe 5;
BA_ "GenSigASIL"  SG_ 948 RLCR_7_Le5ObjYDirVStdDe 5;
BA_ "GenSigASIL"  SG_ 948 RLCR_7_MsgCntr 5;
BA_ "GenSigASIL"  SG_ 948 RLCR_7_CRC 5;
BA_ "GenMsgILSupport" BO_ 953 1;
BA_ "GenMsgCycleTime" BO_ 953 50;
BA_ "GenSigASIL"  SG_ 953 RLCR_8_TiStampLaten 5;
BA_ "GenSigASIL"  SG_ 953 RLCR_8_MsgCntr 5;
BA_ "GenSigASIL"  SG_ 953 RLCR_8_CRC 5;
BA_ "GenMsgILSupport" BO_ 955 1;
BA_ "GenMsgCycleTime" BO_ 955 50;
BA_ "GenSigASIL"  SG_ 955 RLCR_9_ObjVldFlg 5;
BA_ "GenSigStartValue" SG_ 955 RLCR_9_LgtDst 4000;
BA_ "GenSigASIL"  SG_ 955 RLCR_9_LgtDst 5;
BA_ "GenSigStartValue" SG_ 955 RLCR_9_LgtRelV 6400;
BA_ "GenSigASIL"  SG_ 955 RLCR_9_LgtRelV 5;
BA_ "GenSigASIL"  SG_ 955 RLCR_9_MsgCntr 5;
BA_ "GenSigASIL"  SG_ 955 RLCR_9_CRC 5;
BA_ "GenMsgILSupport" BO_ 1203 1;
BA_ "GenMsgCycleTime" BO_ 1203 100;
BA_ "GenSigASIL"  SG_ 1203 RRCR_1_SysSt 5;
BA_ "GenSigASIL"  SG_ 1203 RRCR_1_BlkSts 5;
BA_ "GenSigASIL"  SG_ 1203 RRCR_1_MsgCntr 5;
BA_ "GenSigASIL"  SG_ 1203 RRCR_1_CRC 5;
BA_ "GenMsgILSupport" BO_ 959 1;
BA_ "GenMsgCycleTime" BO_ 959 50;
BA_ "GenSigASIL"  SG_ 959 RRCR_2_Ri1ObjBoxLen 5;
BA_ "GenSigASIL"  SG_ 959 RRCR_2_Ri1ObjBoxWidth 5;
BA_ "GenSigStartValue" SG_ 959 RRCR_2_Ri1HdTo 1800;
BA_ "GenSigASIL"  SG_ 959 RRCR_2_Ri1HdTo 5;
BA_ "GenSigASIL"  SG_ 959 RRCR_2_Ri1ObjID 5;
BA_ "GenSigStartValue" SG_ 959 RRCR_2_Ri1ObjCoordY 4000;
BA_ "GenSigASIL"  SG_ 959 RRCR_2_Ri1ObjCoordY 5;
BA_ "GenSigStartValue" SG_ 959 RRCR_2_Ri1ObjCoordX 4000;
BA_ "GenSigASIL"  SG_ 959 RRCR_2_Ri1ObjCoordX 5;
BA_ "GenSigStartValue" SG_ 959 RRCR_2_Ri1ObjXDirAV 128;
BA_ "GenSigASIL"  SG_ 959 RRCR_2_Ri1ObjXDirAV 5;
BA_ "GenSigStartValue" SG_ 959 RRCR_2_Ri1ObjYDirV 6400;
BA_ "GenSigASIL"  SG_ 959 RRCR_2_Ri1ObjYDirV 5;
BA_ "GenSigStartValue" SG_ 959 RRCR_2_Ri1ObjXDirV 6400;
BA_ "GenSigASIL"  SG_ 959 RRCR_2_Ri1ObjXDirV 5;
BA_ "GenSigASIL"  SG_ 959 RRCR_2_Ri1ObjMtnChartc 5;
BA_ "GenSigASIL"  SG_ 959 RRCR_2_Ri1ObjTyp 5;
BA_ "GenSigASIL"  SG_ 959 RRCR_2_Ri1ObjConf 5;
BA_ "GenSigStartValue" SG_ 959 RRCR_2_Ri1ObjNrOffocst 31;
BA_ "GenSigASIL"  SG_ 959 RRCR_2_Ri1ObjNrOffocst 5;
BA_ "GenSigASIL"  SG_ 959 RRCR_2_Ri1ObjTrackSt 5;
BA_ "GenSigASIL"  SG_ 959 RRCR_2_Ri1ObjCoordXDstStdDe 5;
BA_ "GenSigASIL"  SG_ 959 RRCR_2_Ri1ObjCoordYDstStdDe 5;
BA_ "GenSigASIL"  SG_ 959 RRCR_2_Ri1ObjXDirVStdDe 5;
BA_ "GenSigASIL"  SG_ 959 RRCR_2_Ri1ObjYDirVStdDe 5;
BA_ "GenSigASIL"  SG_ 959 RRCR_2_MsgCntr 5;
BA_ "GenSigASIL"  SG_ 959 RRCR_2_CRC 5;
VAL_ 775 HMA_Status 7 " Reserved" 6 " Reserved" 5 " Reserved" 4 " Reserved" 3 " Fault" 2 " Active" 1 " Standby" 0 " Off" ;
VAL_ 775 HMA_HighbeamReq 1 " High beam request" 0 " No request" ;
VAL_ 775 LDW_ELK_TJA_LDPLeftVisuali 3 " Warning" 2 " Intervention" 1 " Line tracking" 0 " No display" ;
VAL_ 775 LDW_ELK_TJA_LDPRightVisuali 3 " Warning" 2 " Intervention" 1 " Line tracking" 0 " No display" ;
VAL_ 775 FCM_2_ISAState 7 " Reserved" 6 " Reserved" 5 " Reserved" 4 " Reserved" 3 " SLWF Aud Off" 2 " SLWF Off" 1 " ISA Off " 0 " No display" ;
VAL_ 775 FCM_2_SCFSpdlimWarn 1 " Active" 0 " Not Active" ;
VAL_ 775 SLAState 7 " Reserved" 6 " Reserved" 5 " Reserved" 4 " Defect" 3 " Navigation only mode" 2 " Vision mode" 1 " Fusion mode" 0 " Off" ;
VAL_ 775 SLASpdlimit 255 " SPL_Unconfirmed" 254 " Reserved" 253 " Reserved" 252 " Reserved" 251 " Reserved" 250 " Reserved" 249 " Reserved" 248 " Reserved" 247 " Reserved" 246 " Reserved" 245 " Reserved" 244 " Reserved" 243 " Reserved" 242 " Reserved" 241 " Reserved" 240 " Reserved" 239 " Reserved" 238 " Reserved" 237 " Reserved" 236 " Reserved" 235 " Reserved" 234 " Reserved" 233 " Reserved" 232 " Reserved" 231 " Reserved" 230 " Reserved" 229 " Reserved" 228 " Reserved" 227 " Reserved" 226 " Reserved" 225 " Reserved" 224 " Reserved" 223 " Reserved" 222 " Reserved" 221 " Reserved" 220 " Reserved" 219 " Reserved" 218 " Reserved" 217 " Reserved" 216 " Reserved" 215 " Reserved" 214 " Reserved" 213 " Reserved" 212 " Reserved" 211 " Reserved" 210 " Reserved" 209 " Reserved" 208 " Reserved" 207 " Reserved" 206 " Reserved" 205 " Reserved" 204 " Reserved" 203 " Reserved" 202 " Reserved" 201 " Reserved" 200 " Reserved" 199 " Reserved" 198 " Reserved" 197 " Reserved" 196 " Reserved" 195 " Reserved" 194 " Reserved" 193 " Reserved" 192 " Reserved" 191 " Reserved" 190 " Reserved" 189 " Reserved" 188 " Reserved" 187 " Reserved" 186 " Reserved" 185 " Reserved" 184 " Reserved" 183 " Reserved" 182 " Reserved" 181 " Reserved" 180 " Reserved" 179 " Reserved" 178 " Reserved" 177 " Reserved" 176 " Reserved" 175 " Reserved" 174 " Reserved" 173 " Reserved" 172 " Reserved" 171 " Reserved" 170 " Reserved" 169 " Reserved" 168 " Reserved" 167 " Reserved" 166 " Reserved" 165 " Reserved" 164 " Reserved" 163 " Reserved" 162 " Reserved" 161 " Reserved" 160 " Reserved" 159 " Reserved" 158 " Reserved" 157 " Reserved" 156 " Reserved" 155 " Reserved" 154 " Reserved" 153 " Reserved" 152 " Reserved" 151 " Reserved" 150 " Reserved" 149 " Reserved" 148 " Reserved" 147 " Reserved" 146 " Reserved" 145 " Reserved" 144 " Reserved" 143 " Reserved" 142 " Reserved" 141 " Reserved" 140 " Reserved" 139 " Reserved" 138 " Reserved" 137 " Reserved" 136 " Reserved" 135 " Reserved" 134 " Reserved" 133 " Reserved" 132 " Reserved" 131 " Reserved" 130 " Reserved" 129 " Reserved" 128 " Reserved" 127 " Reserved" 126 " Reserved" 125 " Reserved" 124 " Reserved" 123 " Reserved" 122 " Reserved" 121 " Reserved" 120 " Reserved" 119 " Reserved" 118 " Reserved" 117 " Reserved" 116 " Reserved" 115 " Reserved" 114 " Reserved" 113 " Reserved" 112 " Reserved" 111 " Reserved" 110 " Reserved" 109 " Reserved" 108 " Reserved" 107 " Reserved" 106 " Reserved" 105 " Reserved" 104 " Reserved" 103 " Reserved" 102 " Reserved" 101 " Reserved" 100 " Reserved" 99 " Reserved" 98 " Reserved" 97 " Reserved" 96 " Reserved" 95 " Reserved" 94 " Reserved" 93 " Reserved" 92 " Reserved" 91 " Reserved" 90 " Reserved" 89 " Reserved" 88 " Reserved" 87 " Reserved" 86 " Reserved" 85 " Reserved" 84 " Reserved" 83 " Reserved" 82 " Reserved" 81 " Reserved" 80 " Reserved" 79 " Reserved" 78 " Reserved" 77 " Reserved" 76 " Reserved" 75 " Reserved" 74 " Reserved" 73 " Reserved" 72 " Reserved" 71 " Reserved" 70 " Reserved" 69 " Reserved" 68 " Reserved" 67 " Reserved" 66 " Reserved" 65 " Reserved" 64 " Reserved" 63 " Reserved" 62 " Reserved" 61 " Reserved" 60 " Reserved" 59 " Reserved" 58 " Reserved" 57 " Reserved" 56 " Reserved" 55 " Reserved" 54 " Reserved" 53 " Reserved" 52 " Reserved" 51 " Reserved" 50 " Reserved" 49 " Reserved" 48 " Reserved" 47 " Reserved" 46 " Reserved" 45 " Reserved" 44 " Reserved" 43 " Reserved" 42 " Reserved" 41 " Reserved" 40 " Reserved" 39 " Reserved" 38 " Reserved" 37 " SPL 180" 36 " SPL 175" 35 " SPL 170" 34 " SPL 165" 33 " SPL 160" 32 " SPL 155" 31 " SPL 150" 30 " SPL 145" 29 " SPL 140" 28 " SPL 135" 27 " SPL 130" 26 " SPL 125" 25 " SPL 120" 24 " SPL 115" 23 " SPL 110" 22 " SPL 105" 21 " SPL 100" 20 " SPL 95" 19 " SPL 90" 18 " SPL 85" 17 " SPL 80" 16 " SPL 75" 15 " SPL 70" 14 " SPL 65" 13 " SPL 60" 12 " SPL 55" 11 " SPL 50" 10 " SPL 45" 9 " SPL 40" 8 " SPL 35" 7 " SPL 30" 6 " SPL 25" 5 " SPL 20" 4 " SPL 15" 3 " SPL10" 2 " SPL 5" 1 " SPL Cancelled" 0 " No Display" ;
VAL_ 775 SLASpdlimitWarning 1 " Active" 0 " Not Active" ;
VAL_ 775 Camera_textinfo 3 "  Camera high temperature" 2 " Camera blocked" 1 " Camera failure" 0 " Camera normal" ;
VAL_ 775 FCM_2_SpdLimtyp 3 " Reserved" 2 " National SpeedLimit" 1 " Conditional Unconfirmed" 0 " No Conditional" ;
VAL_ 775 TJA_ICA_mode 7 " Reserved" 6 " Reserved" 5 " Reserved" 4 " Reserved" 3 " Failure mode" 2 " Active mode" 1 " Standby mode" 0 " OFF mode" ;
VAL_ 775 FCM_2_SLASpdLimChgAud 1 " Active" 0 " Not Active" ;
VAL_ 775 FCM_2_SLASpdlimitUnits 3 " Reserved" 2 " MPH" 1 " KMH" 0 " Unknown" ;
VAL_ 775 FCM_2_TJATakeoverReq 3 " Suppressed" 2 " Take Over Safty" 1 " Take Over Warning" 0 " Not Active" ;
VAL_ 775 SLASpdlimitUnknownWarning 3 " Reserved" 2 " Reserved" 1 " Active" 0 " Not Active" ;
VAL_ 775 SLASpdlimitWarningVis 1 " Active" 0 " Not Active" ;
VAL_ 775 SLASpdlimitWarningAud 1 " Active" 0 " Not Active" ;
VAL_ 837 FCM_3_StrngWhlAgReq 16383 "Invalid" ;
VAL_ 837 FCM_3_StrngWhlAgReqActive 1 "steering Wheel Angle request is active" 0 "steering Wheel Angle request is not active" ;
VAL_ 837 FCM_3_HptcVibReq 1 " request" 0 " not request" ;
VAL_ 837 FCM_3_ManMachineSharingSts 3 "reserved" 2 "Man-machine sharing is available" 1 "Man-machine sharing is not available" 0 "Not Active" ;
VAL_ 1245 FCM_5_TJAICAExitTextInfoSts 3 " Reserved" 2 " OFF" 1 " ON" 0 " Not active" ;
VAL_ 1245 FCM_5_SLAONOFFSts 3 " Reserved" 2 " OFF" 1 " ON" 0 " Not active" ;
VAL_ 1245 FCM_5_IESONOFFSts 3 " Reserved" 2 " OFF" 1 " ON" 0 " Not active" ;
VAL_ 1245 FCM_5_HMAONOFFSts 3 " Reserved" 2 " OFF" 1 " ON" 0 " Not active" ;
VAL_ 1245 FCM_5_TSIONOFFSts 3 " Reserved" 2 " OFF" 1 " ON" 0 " Not active" ;
VAL_ 1245 FCM_5_TLIONOFFSts 3 " Reserved" 2 " OFF" 1 " ON" 0 " Not active" ;
VAL_ 1245 FCM_5_LDWONOFFSts 3 " Reserved" 2 " OFF" 1 " ON" 0 " Not active" ;
VAL_ 1245 FCM_5_WarnModSts 3 " voice and shock" 2 " only shock " 1 " only voice" 0 " Not active" ;
VAL_ 1245 FCM_5_LDPONOFFSts 3 " Reserved" 2 " OFF" 1 " ON" 0 " Not active" ;
VAL_ 1245 FCM_5_LDWLDPSnvtySts 3 " Reserved" 2 " HighSensitivity" 1 " LowSensitivity" 0 " Not active" ;
VAL_ 1245 FCM_5_ELKONOFFSts 3 " Reserved" 2 " OFF" 1 " ON" 0 " Not active" ;
VAL_ 1245 SLWFONOFFSts 3 " Reserved" 2 " OFF" 1 " ON" 0 " Not active" ;
VAL_ 1245 SLASpdlimitWarningAudSWSts 3 " Reserved" 2 " OFF" 1 " ON" 0 " Not active" ;
VAL_ 1245 SLASpdLimChgAudSwSts 3 " Reserved" 2 " OFF" 1 " ON" 0 " Not active" ;
VAL_ 1245 FCM_5_SpeedLmtNmberAb 63 "reserved" 62 "reserved" 61 "reserved" 60 "reserved" 59 "reserved" 58 "reserved" 57 "reserved" 56 "reserved" 55 "reserved" 54 "reserved" 53 "reserved" 52 "reserved" 51 "reserved" 50 "reserved" 49 "reserved" 48 "reserved" 47 "reserved" 46 "reserved" 45 "reserved" 44 "reserved" 43 "reserved" 42 "reserved" 41 "reserved" 40 "reserved" 39 "reserved" 38 "reserved" 37 "reserved" 36 "reserved" 35 "reserved" 34 "reserved" 33 "reserved" 32 "reserved" 31 "reserved" 30 "reserved" 29 "reserved" 28 "reserved" 27 "reserved" 26 "reserved" 25 "reserved" 24 "reserved" 23 "reserved" 22 "reserved" 21 "10" 20 "9" 19 "8" 18 "7" 17 "6" 16 "5" 15 "4" 14 "3" 13 "2" 12 "1" 11 "0" 10 "-1" 9 "-2" 8 "-3" 7 "-4" 6 "-5" 5 "-6" 4 "-7" 3 "-8" 2 "-9" 1 "-10" 0 "No display" ;
VAL_ 1245 FCM_5_SpeedLmtNmberE 63 " reserved" 62 " reserved" 61 " reserved" 60 " reserved" 59 " reserved" 58 " reserved" 41 "20%" 40 "19%" 39 "18%" 38 "17%" 37 "16%" 36 "15%" 35 "14%" 34 "13%" 33 "12%" 32 "11%" 31 "10%" 30 "9%" 29 "8%" 28 "7%" 27 "6%" 26 "5%" 25 "4%" 24 "3%" 23 "2%" 22 "1%" 21 "0%" 20 "-1%" 19 "-2%" 18 "-3%" 17 "-4%" 16 "-5%" 15 "-6%" 14 "-7%" 13 "-8%" 12 "-9%" 11 "-10% " 10 "-11%" 9 "-12%" 8 "-13%" 7 "-14%" 6 "-15%" 5 "-16%" 4 "-17%" 3 "-18%" 2 "-19%" 1 "-20%" 0 "No display" ;
VAL_ 1245 FCM_5_SLAmodeSWSet 3 " Reserved" 2 " Relative" 1 " Absolute" 0 " Not active" ;
VAL_ 988 FCM_6_EgoLeLineID 1 " Valid" 0 " Invalid" ;
VAL_ 988 FCM_6_EgoLeLineColor 3 " Color_Yellow" 2 " Color_White" 1 " Color_Unknown" 0 " No display" ;
VAL_ 988 FCM_6_EgoLeLineTyp 3 " Type_Dashed_Line" 2 " Type_Solid_Line" 1 " Type_Unknown" 0 " No display" ;
VAL_ 988 FCM_6_EgoLeLineHozlDst 511 "Invalid" ;
VAL_ 988 FCM_6_EgoLeLineCrvt 1023 "Invalid" ;
VAL_ 988 FCM_6_EgoRiLineID 1 " Valid" 0 " Invalid" ;
VAL_ 988 FCM_6_EgoRiLineColor 3 " Color_Yellow" 2 " Color_White" 1 " Color_Unknown" 0 " No display" ;
VAL_ 988 FCM_6_EgoRiLineTyp 3 " Type_Dashed_Line" 2 " Type_Solid_Line" 1 " Type_Unknown" 0 " No display" ;
VAL_ 988 FCM_6_EgoRiLineHozlDst 511 "Invalid" ;
VAL_ 988 FCM_6_EgoRiLineCrvt 1023 "Invalid" ;
VAL_ 990 FCM_7_NeborLeLineID 1 " Valid" 0 " Invalid" ;
VAL_ 990 FCM_7_NeborLeLineColor 3 " Color_Yellow" 2 " Color_White" 1 " Color_Unknown" 0 " No display" ;
VAL_ 990 FCM_7_NeborLeLineTyp 3 " Type_Dashed_Line" 2 " Type_Solid_Line" 1 " Type_Unknown" 0 " No display" ;
VAL_ 990 FCM_7_NeborLeLineHozlDst 511 "Invalid" ;
VAL_ 990 FCM_7_NeborLeLineCrvt 1023 "Invalid" ;
VAL_ 990 FCM_7_NeborRiLineID 1 " Valid" 0 " Invalid" ;
VAL_ 990 FCM_7_NeborRiLineColor 3 " Color_Yellow" 2 " Color_White" 1 " Color_Unknown" 0 " No display" ;
VAL_ 990 FCM_7_NeborRiLineTyp 3 " Type_Dashed_Line" 2 " Type_Solid_Line" 1 " Type_Unknown" 0 " No display" ;
VAL_ 990 FCM_7_NeborRiLineHozlDst 511 "Invalid" ;
VAL_ 990 FCM_7_NeborRiLineCrvt 1023 "Invalid" ;
VAL_ 1005 FCM_FRM_8_ACCObjID 1 " Valid" 0 " Invalid" ;
VAL_ 1005 FCM_FRM_8_ACCObjTyp 15 " Reserved" 14 " Reserved" 13 " Reserved" 12 " Reserved" 11 " Reserved" 10 " Reserved" 9 " Reserved" 8 " Reserved" 7 " Reserved" 6 " Bus" 5 " Cyclist" 4 " Pedestrian" 3 " Motorcycle" 2 " Truck" 1 " Car" 0 " No type" ;
VAL_ 1005 FCM_FRM_8_ACCObjLgtDstX 255 "Invalid" ;
VAL_ 1005 FCM_FRM_8_ACCObjHozDstY 1023 "Invalid" ;
VAL_ 1005 FCM_FRM_8_FrntFarObjID 1 " Valid" 0 " Invalid" ;
VAL_ 1005 FCM_FRM_8_FrntFarObjTyp 15 " Reserved" 14 " Reserved" 13 " Reserved" 12 " Reserved" 11 " Reserved" 10 " Reserved" 9 " Reserved" 8 " Reserved" 7 " Reserved" 6 " Bus" 5 " Cyclist" 4 " Pedestrian" 3 " Motorcycle" 2 " Truck" 1 " Car" 0 " No type" ;
VAL_ 1005 FCM_FRM_8_FrntFarObjLgtDstX 255 "Invalid" ;
VAL_ 1005 FCM_FRM_8_FrntFarObjHozDstY 1023 "Invalid" ;
VAL_ 1005 FCM_FRM_8_IDSONOFFSts 3 " Reserved" 2 " OFF" 1 " ON" 0 " Not active" ;
VAL_ 1005 FCM_FRM_8_WSOSONOFFSts 3 " Reserved" 2 " OFF" 1 " ON" 0 " Not active" ;
VAL_ 1018 FCM_FRM_9_LeObjID 1 " Valid" 0 " Invalid" ;
VAL_ 1018 FCM_FRM_9_LeObjTyp 15 " Reserved" 14 " Reserved" 13 " Reserved" 12 " Reserved" 11 " Reserved" 10 " Reserved" 9 " Reserved" 8 " Reserved" 7 " Reserved" 6 " Bus" 5 " Cyclist" 4 " Pedestrian" 3 " Motorcycle" 2 " Truck" 1 " Car" 0 " No type" ;
VAL_ 1018 FCM_FRM_9_LeObjLgtDstX 255 "Invalid" ;
VAL_ 1018 FCM_FRM_9_LeObjHozDstY 1023 "Invalid" ;
VAL_ 1018 FCM_FRM_9_RiObjID 1 " Valid" 0 " Invalid" ;
VAL_ 1018 FCM_FRM_9_RiObjTyp 15 " Reserved" 14 " Reserved" 13 " Reserved" 12 " Reserved" 11 " Reserved" 10 " Reserved" 9 " Reserved" 8 " Reserved" 7 " Reserved" 6 " Bus" 5 " Cyclist" 4 " Pedestrian" 3 " Motorcycle" 2 " Truck" 1 " Car" 0 " No type" ;
VAL_ 1018 FCM_FRM_9_RiObjLgtDstX 255 "Invalid" ;
VAL_ 1018 FCM_FRM_9_RiObjHozDstY 1023 "Invalid" ;
VAL_ 1020 FCM_10_TSISysSts 3 " Reserved" 2 " Fault" 1 " On" 0 " OFF" ;
VAL_ 1020 FCM_10_TLISysSts 3 " Fault" 2 " Active" 1 " Standby" 0 " OFF" ;
VAL_ 1020 FCM_10_TSISgnGiWay 15 " Reserved" 14 " ENCAP_Yield Signs" 13 " ENCAP_Stop Signs" 12 " ENCAP_Traffic_Lights" 11 " Malaysia stop sign" 10 " Australian stop sign" 9 " Australian yield sign2" 8 " Australian yield sign1" 7 " Australian watch for pedestrians" 6 " Yield Sign" 5 " Stop Sign" 4 " Warn Merger" 3 " Warn Road Work" 2 " Warn Kids" 1 " Watch For Pedestrians " 0 " No Display" ;
VAL_ 1020 FCM_10_TSISgnForb 15 " Reserved——ENCAP_NOentry" 14 " Reserved——ENCAP_Vehicle Categories" 13 " Reserved——ENCAP_Arrows" 12 " Reserved——ENCAP_Distance for/in" 11 " Reserved——ENCAP_Time/Season" 10 " Reserved——ENCAP_Snow/Icy" 9 " Reserved——ENCAP_Rain/Wetness" 8 " Australian prohibiting U-turning" 7 " Australian prohibiting turning right" 6 " Australian prohibiting turning left" 5 " No entry" 4 " Prohibiting Motor Vehicle Entering" 3 " Prohibiting U-turning" 2 " Prohibiting turning right" 1 " Prohibiting turning left" 0 " No Display" ;
VAL_ 1020 FCM_10_TSISgnLongStayDisp 15 " Reserved" 14 " Reserved" 13 " Reserved" 12 " Reserved" 11 " Reserved" 10 " Reserved" 9 " Reserved" 8 " Malaysia no overtaking" 7 " Australian No parking" 6 " Australian prohibiting standing and parking" 5 " Australian no overtaking" 4 " Prohibiting Standing And Parking" 3 " No Parking" 2 " End Of No Overtaking" 1 " No Overtaking" 0 " No Display" ;
VAL_ 1020 FCM_10_TLITrfcLi 3 " Red" 2 " Yellow" 1 " Green" 0 " No Display" ;
VAL_ 1020 FCM_10_LDPSysSts 7 " Reserved" 6 " Reserved" 5 " Reserved" 4 " Fault" 3 " Active_startup " 2 " Active_standby" 1 " Suppressed" 0 " OFF" ;
VAL_ 1020 FCM_10_LDWSysSts 7 " Reserved" 6 " Reserved" 5 " Reserved" 4 " Fault" 3 " Active_startup " 2 " Active_standby" 1 " Suppressed" 0 " OFF" ;
VAL_ 1020 FCM_10_ELKSysSts 7 " Reserved" 6 " Reserved" 5 " Reserved" 4 " Fault" 3 " Active_startup " 2 " Active_standby" 1 " Suppressed" 0 " OFF" ;
VAL_ 1020 FCM_10_TSINoParkWarn 1 " Active" 0 " Not Active" ;
VAL_ 1020 FCM_10_TJAICATextinfo 7 "  IES is active" 6 " TJA/ICA is exit reminder" 5 " TJA/ICA is in error mode" 4 " TJA/ICA is active" 3 " Unable to active TJA/ICA" 2 " TJA/ICA is switched on" 1 " TJA/ICA is switched off" 0 " No display" ;
VAL_ 1020 FCM_10_TJAICAEnaRcmend 1 " Demand" 0 " No demand" ;
VAL_ 1020 FCM_10_LDPTJAELKTakeoverReq 3 " Suppressed" 2 " Take Over Safty" 1 " Take Over Warning" 0 " Not Active" ;
VAL_ 1020 FCM_10_TJAICAExitTextInfoSts 3 " Reserved" 2 " OFF" 1 " ON" 0 " Not active" ;
VAL_ 1020 FCM_10_SLAONOFFSts 3 " Reserved" 2 " OFF" 1 " ON" 0 " Not active" ;
VAL_ 1020 FCM_10_WarnModSts 3 " voice and shock" 2 " only shock " 1 " only voice" 0 " Not active" ;
VAL_ 1020 FCM_10_ELKIntvMod 7 " Reserved" 6 " Reserved" 5 " Reserved" 4 " Reserved" 3 " ELK Overtaking" 2 " ELK Oncoming" 1 " ELK Road Edge or Solid Line" 0 " Not active" ;
VAL_ 1020 FCM_10_EgoLeftLineHeatgAg 511 "Invalid" ;
VAL_ 930 VLCShutdownMode 3 " initial" 2 " immediate off" 1 " fast off" 0 " soft off" ;
VAL_ 930 ACCMode_ESP 7 " Failure mode" 6 " Standstill" 5 " Override" 4 " Brake only mode" 3 " Active control mode" 2 " Standby mode" 1 " Passive mode" 0 " OFF mode" ;
VAL_ 930 BrakePreferred 1 " Demand" 0 " No demand" ;
VAL_ 930 DriveOff 1 " Demand" 0 " No demand" ;
VAL_ 930 DecToStop 1 " Demand" 0 " No demand" ;
VAL_ 930 ACC_AccECGPOvrd 1 " Demand" 0 " No demand" ;
VAL_ 930 HBALevel 3 " Level3" 2 " Level2" 1 " Level1" 0 " Level0" ;
VAL_ 930 HBARequest 1 " Demand" 0 " No demand" ;
VAL_ 930 PrefillRequest 1 " Demand" 0 " No demand" ;
VAL_ 933 AEBDecCtrlRequest 1 " Demand" 0 " No demand" ;
VAL_ 933 ACCMinimumBraking 1 " Demand" 0 " No demand" ;
VAL_ 933 ACCStartStopInfo 3 " ACC SystemFailure" 2 " ACC StartRequest" 1 " ACC StopForbidden" 0 " ACC StopAllowed" ;
VAL_ 933 AEBReq 7 " Reserved" 6 " Reserved" 5 " FCTB" 4 " EBA" 3 " AEB~cyclist" 2 " AEB~VRU" 1 " AEB" 0 " No demand" ;
VAL_ 933 AWBRequest 1 " Demand" 0 " No demand" ;
VAL_ 933 AWBLevel 15 " Reserved" 14 " Reserved" 13 " Reserved" 12 " Reserved" 11 " Reserved" 10 " Reserved" 9 " Reserved" 8 " Reserved" 7 " Reserved" 6 " Reserved" 5 " Reserved" 4 " Level4" 3 " Level3" 2 " Level2" 1 " Level1" 0 " No level" ;
VAL_ 933 FCM_FRM_2_Textinfo_Info 15 " Reserved" 14 " Reserved" 13 " Reserved" 12 " FCW is active" 11 " Unable to active FCW" 10 " FCW is switched on" 9 " FCW is switched off " 8 " AEB is active" 7 " Unable to switched on AEB" 6 " AEB is switched on" 5 " AEB is switched off" 4 " Drive Away Information Active" 3 " ACC is stand-wait" 2 " Unable to active ACC" 1 " ACC is cancelled" 0 " No Display" ;
VAL_ 773 Textinfo 22 " ACC is stand-wait" 21 " ACC is stand-active" 20 " Radar is in error mode" 19 " FCW is in error mode" 18 " FCW is active" 17 " distanceWarning is active" 16 " unable to active FCW" 15 " FCW  is switched on" 14 " FCW  is switched off" 13 " Radar is covered" 12 " AEB is in error mode" 11 " AEB is active" 10 " unable to active AEB" 9 " AEB is switched on" 8 " AEB is switched off" 7 " Driver take over" 6 " ACC is in error mode" 5 " ACC is active" 4 " unable to active ACC" 3 " ACC is switched on" 2 " ACC is switched off" 1 " ACC is cancelled" 0 " No display" ;
VAL_ 773 ACCModeDummy 0 " OFF mode" ;
VAL_ 1251 FCM_FRM_5_AEBONOFFSts 3 " Reserved" 2 " OFF" 1 " ON" 0 " Not active" ;
VAL_ 1251 FCM_FRM_5_FCWSnvtySts 3 " far" 2 " near" 1 " standard" 0 " Not active" ;
VAL_ 1251 FCM_FRM_5_FCWONOFFSts 3 " Reserved" 2 " OFF" 1 " ON" 0 " Not active" ;
VAL_ 1251 FCM_FRM_5_SCFONOFFSts 3 " Reserved" 2 " OFF" 1 " ON" 0 " Not active" ;
VAL_ 1251 FCM_FRM_5_DAIONOFFSts 3 " Reserved" 2 " OFF" 1 " ON" 0 " Not active" ;
VAL_ 903 FCM_FRM_6_Textinfo_Info 15 " Unable to switched on SCF" 14 " SCF is switched off" 13 " SCF is switched on" 12 " FCW is active" 11 " Unable to active FCW" 10 " FCW is switched on" 9 " FCW is switched off " 8 " AEB is active" 7 " Unable to switched on AEB" 6 " AEB is switched on" 5 " AEB is switched off" 4 " Drive Away Information Active" 3 " ACC is stand-wait" 2 " Unable to active ACC" 1 " ACC is cancelled" 0 " No Display" ;
VAL_ 903 FCM_FRM_6_TextinfoWarn 15 " Reserved" 14 " Reserved" 13 " Reserved" 12 " Reserved" 11 " Reserved" 10 " Reserved" 9 " Reserved" 8 " Reserved" 7 " Reserved" 6 " Radar is in error mode" 5 " FCW is in error mode" 4 " Radar is covered" 3 " AEB is in error mode " 2 " ACC is in error mode" 1 " Driver take over" 0 " No Display" ;
VAL_ 903 FCM_FRM_6_Textinfo_Info_2 15 " Reserved" 14 " Reserved" 13 " Reserved" 12 " Reserved" 11 " Reserved" 10 " Reserved" 9 " Reserved" 8 " Reserved" 7 " Reserved" 6 " Reserved" 5 " Reserved" 4 " Reserved" 3 " WSOS is active" 2 " IDS is active" 1 " ACC controlled vehicle start up" 0 " No Display" ;
VAL_ 903 FCM_FRM_6_TimeGapSetICM 7 " Reserved" 6 " Reserved" 5 " TauGap_5" 4 " TauGap_4" 3 " TauGap_3" 2 " TauGap_2" 1 " TauGap_1" 0 " No Display" ;
VAL_ 903 FCM_FRM_6_SCF_PopoverReq 1 " Driver confirm Request" 0 " No Request" ;
VAL_ 903 FCM_FRM_6_SCF_SpdLimSts 7 " Reserved" 6 " Reserved" 5 " Reserved" 4 " IREVERSIBLE_FAILURE" 3 " REVERSIBLE_FAILURE" 2 " ACTIVE" 1 " STANDBY" 0 " OFF" ;
VAL_ 903 FCM_FRM_6_SCF_SpdLimUnit 3 " Reserved" 2 " Reserved" 1 " MPH" 0 " KMH" ;
VAL_ 903 FCM_FRM_6_DrvrCfmSCFDispFb 1 " confirmed" 0 " not confirmed" ;
VAL_ 903 FCM_FRM_6_DistanceWarning 1 " Warning" 0 " No warning" ;
VAL_ 903 FCM_FRM_6_FCW_preWarning 1 " Warning" 0 " No warning" ;
VAL_ 903 FCM_FRM_6_TakeOverReq 1 " Requst" 0 " No Requst" ;
VAL_ 903 FCM_FRM_6_FCWMode 3 " Failure mode" 2 " Active mode" 1 " On mode" 0 " OFF mode" ;
VAL_ 903 FCM_FRM_6_AEBMode 3 " Failure mode" 2 " Active mode" 1 " On mode" 0 " OFF mode" ;
VAL_ 903 FCM_FRM_6_AEBDecCtrlRequest 1 " Demand" 0 " No demand" ;
VAL_ 903 FCM_FRM_6_HMI_Indicator 3 " Active" 2 " Failure" 1 " OFF" 0 " No response" ;
VAL_ 903 FCM_FRM_6_ACCMode 15 " Reserved" 14 " Reserved" 13 " Reserved" 12 " Reserved" 11 " Reserved" 10 " Reserved" 9 " Failure mode" 8 " Reserved /  OFF mode(just for M32TFL2)" 7 " Override" 6 " Stand-wait" 5 " Stand-active" 4 "Brake-Only mode" 3 " Active-Control mode" 2 " Ready mode" 1 " Passive mode" 0 " Initial Mode" ;
VAL_ 903 FCM_FRM_6_SCF_Indicator 3 "Reserved" 2 "Lower" 1 "Higher" 0 "No Request" ;
VAL_ 943 IDCU_1_AmbLi 3 "night" 2 "Reserved" 1 "day" 0 "Not Active" ;
VAL_ 943 IDCU_1_HozlPosnRi 1023 "Invalid" ;
VAL_ 943 IDCU_1_HozlPosnLe 1023 "Invalid" ;
VAL_ 943 IDCU_1_ObjN1_Type 7 "Reserved" 6 "Reserved" 5 "Reserved" 4 "Reserved" 3 "Reserved" 2 "preceding object" 1 "oncoming object" 0 "No object" ;
VAL_ 949 IDCU_2_FCMStForADB 1 "valid" 0 "Invalid " ;
VAL_ 949 IDCU_2_HozlPosnRi 1023 "Invalid" ;
VAL_ 949 IDCU_2_HozlPosnLe 1023 "Invalid" ;
VAL_ 949 IDCU_2_ObjN2_Type 7 "Reserved" 6 "Reserved" 5 "Reserved" 4 "Reserved" 3 "Reserved" 2 "preceding object" 1 "oncoming object" 0 "No object" ;
VAL_ 957 IDCU_3_HozlPosnRi 1023 "Invalid" ;
VAL_ 957 IDCU_3_HozlPosnLe 1023 "Invalid" ;
VAL_ 957 IDCU_3_ObjN3_Type 7 "Reserved" 6 "Reserved" 5 "Reserved" 4 "Reserved" 3 "Reserved" 2 "preceding object" 1 "oncoming object" 0 "No object" ;
VAL_ 974 IDCU_4_HozlPosnRi 1023 "Invalid" ;
VAL_ 974 IDCU_4_HozlPosnLe 1023 "Invalid" ;
VAL_ 974 IDCU_4_ObjN4_Type 7 "Reserved" 6 "Reserved" 5 "Reserved" 4 "Reserved" 3 "Reserved" 2 "preceding object" 1 "oncoming object" 0 "No object" ;
VAL_ 981 IDCU_5_HozlPosnRi 1023 "Invalid" ;
VAL_ 981 IDCU_5_HozlPosnLe 1023 "Invalid" ;
VAL_ 981 IDCU_5_ObjN5_Type 7 "Reserved" 6 "Reserved" 5 "Reserved" 4 "Reserved" 3 "Reserved" 2 "preceding object" 1 "oncoming object" 0 "No object" ;
VAL_ 1001 IDCU_6_HozlPosnRi 1023 "Invalid" ;
VAL_ 1001 IDCU_6_HozlPosnLe 1023 "Invalid" ;
VAL_ 1001 IDCU_6_ObjN6_Type 7 "Reserved" 6 "Reserved" 5 "Reserved" 4 "Reserved" 3 "Reserved" 2 "preceding object" 1 "oncoming object" 0 "No object" ;
VAL_ 1003 IDCU_7_HozlPosnRi 1023 "Invalid" ;
VAL_ 1003 IDCU_7_HozlPosnLe 1023 "Invalid" ;
VAL_ 1003 IDCU_7_ObjN7_Type 7 "Reserved" 6 "Reserved" 5 "Reserved" 4 "Reserved" 3 "Reserved" 2 "preceding object" 1 "oncoming object" 0 "No object" ;
VAL_ 1013 IDCU_8_HozlPosnRi 1023 "Invalid" ;
VAL_ 1013 IDCU_8_HozlPosnLe 1023 "Invalid" ;
VAL_ 1013 IDCU_8_ObjN8_Type 7 "Reserved" 6 "Reserved" 5 "Reserved" 4 "Reserved" 3 "Reserved" 2 "preceding object" 1 "oncoming object" 0 "No object" ;
VAL_ 1201 RLCR_1_SysSt 3 " System Error" 2 " Temporary Error" 1 " On" 0 " Off" ;
VAL_ 1201 RLCR_1_ELKSts 1 " Active" 0 " Not Active" ;
VAL_ 1201 RLCR_1_BlkSts 1 " Blockage" 0 " Not Blockage" ;
VAL_ 935 RLCR_3_Le1ObjBoxLen 511 "Invalid" ;
VAL_ 935 RLCR_3_Le1ObjBoxWidth 511 "Invalid" ;
VAL_ 935 RLCR_3_Le1HdTo 4095 "Invalid" ;
VAL_ 935 RLCR_3_Le1ObjID 255 "Invalid" ;
VAL_ 935 RLCR_3_Le1ObjCoordY 8191 "Invalid" ;
VAL_ 935 RLCR_3_Le1ObjCoordX 8191 "Invalid" ;
VAL_ 935 RLCR_3_Le1ObjXDirAV 255 "Invalid" ;
VAL_ 935 RLCR_3_Le1ObjYDirV 16383 "Invalid" ;
VAL_ 935 RLCR_3_Le1ObjXDirV 16383 "Invalid" ;
VAL_ 935 RLCR_3_Le1ObjMtnChartc 3 " Moving" 2 " StatyFromMoving" 1 " Staty" 0 "  Invalid" ;
VAL_ 935 RLCR_3_Le1ObjTyp 3 " Not Used" 2 " Two wheels vehicle " 1 " Four wheels vehicle " 0 "  Invalid" ;
VAL_ 935 RLCR_3_Le1ObjConf 1 " Conf" 0 " Un conf" ;
VAL_ 935 RLCR_3_Le1ObjNrOffocst 31 "Invalid" ;
VAL_ 935 RLCR_3_Le1ObjTrackSt 3 " Coasted" 2 " New" 1 " Updated" 0 " Invalid" ;
VAL_ 935 RLCR_3_Le1ObjCoordXDstStdDe 255 "Invalid" ;
VAL_ 935 RLCR_3_Le1ObjCoordYDstStdDe 255 "Invalid" ;
VAL_ 935 RLCR_3_Le1ObjXDirVStdDe 63 "Invalid" ;
VAL_ 935 RLCR_3_Le1ObjYDirVStdDe 63 "Invalid" ;
VAL_ 937 RLCR_4_Le2ObjBoxLen 511 "Invalid" ;
VAL_ 937 RLCR_4_Le2ObjBoxWidth 511 "Invalid" ;
VAL_ 937 RLCR_4_Le2HdTo 4095 "Invalid" ;
VAL_ 937 RLCR_4_Le2ObjID 255 "Invalid" ;
VAL_ 937 RLCR_4_Le2ObjCoordY 8191 "Invalid" ;
VAL_ 937 RLCR_4_Le2ObjCoordX 8191 "Invalid" ;
VAL_ 937 RLCR_4_Le2ObjXDirAV 255 "Invalid" ;
VAL_ 937 RLCR_4_Le2ObjYDirV 16383 "Invalid" ;
VAL_ 937 RLCR_4_Le2ObjXDirV 16383 "Invalid" ;
VAL_ 937 RLCR_4_Le2ObjMtnChartc 3 " Moving" 2 " StatyFromMoving" 1 " Staty" 0 "  Invalid" ;
VAL_ 937 RLCR_4_Le2ObjTyp 3 " Not Used" 2 " Two wheels vehicle " 1 " Four wheels vehicle " 0 "  Invalid" ;
VAL_ 937 RLCR_4_Le2ObjConf 1 " Conf" 0 " Un conf" ;
VAL_ 937 RLCR_4_Le2ObjNrOffocst 31 "Invalid" ;
VAL_ 937 RLCR_4_Le2ObjTrackSt 3 " Coasted" 2 " New" 1 " Updated" 0 " Invalid" ;
VAL_ 937 RLCR_4_Le2ObjCoordXDstStdDe 255 "Invalid" ;
VAL_ 937 RLCR_4_Le2ObjCoordYDstStdDe 255 "Invalid" ;
VAL_ 937 RLCR_4_Le2ObjXDirVStdDe 63 "Invalid" ;
VAL_ 937 RLCR_4_Le2ObjYDirVStdDe 63 "Invalid" ;
VAL_ 941 RLCR_5_Le3ObjBoxLen 511 "Invalid" ;
VAL_ 941 RLCR_5_Le3ObjBoxWidth 511 "Invalid" ;
VAL_ 941 RLCR_5_Le3HdTo 4095 "Invalid" ;
VAL_ 941 RLCR_5_Le3ObjID 255 "Invalid" ;
VAL_ 941 RLCR_5_Le3ObjCoordY 8191 "Invalid" ;
VAL_ 941 RLCR_5_Le3ObjCoordX 8191 "Invalid" ;
VAL_ 941 RLCR_5_Le3ObjXDirAV 255 "Invalid" ;
VAL_ 941 RLCR_5_Le3ObjYDirV 16383 "Invalid" ;
VAL_ 941 RLCR_5_Le3ObjXDirV 16383 "Invalid" ;
VAL_ 941 RLCR_5_Le3ObjMtnChartc 3 " Moving" 2 " StatyFromMoving" 1 " Staty" 0 "  Invalid" ;
VAL_ 941 RLCR_5_Le3ObjTyp 3 " Not Used" 2 " Two wheels vehicle " 1 " Four wheels vehicle " 0 "  Invalid" ;
VAL_ 941 RLCR_5_Le3ObjConf 1 " Conf" 0 " Un conf" ;
VAL_ 941 RLCR_5_Le3ObjNrOffocst 31 "Invalid" ;
VAL_ 941 RLCR_5_Le3ObjTrackSt 3 " Coasted" 2 " New" 1 " Updated" 0 " Invalid" ;
VAL_ 941 RLCR_5_Le3ObjCoordXDstStdDe 255 "Invalid" ;
VAL_ 941 RLCR_5_Le3ObjCoordYDstStdDe 255 "Invalid" ;
VAL_ 941 RLCR_5_Le3ObjXDirVStdDe 63 "Invalid" ;
VAL_ 941 RLCR_5_Le3ObjYDirVStdDe 63 "Invalid" ;
VAL_ 946 RLCR_6_Le4ObjBoxLen 511 "Invalid" ;
VAL_ 946 RLCR_6_Le4ObjBoxWidth 511 "Invalid" ;
VAL_ 946 RLCR_6_Le4HdTo 4095 "Invalid" ;
VAL_ 946 RLCR_6_Le4ObjID 255 "Invalid" ;
VAL_ 946 RLCR_6_Le4ObjCoordY 8191 "Invalid" ;
VAL_ 946 RLCR_6_Le4ObjCoordX 8191 "Invalid" ;
VAL_ 946 RLCR_6_Le4ObjXDirAV 255 "Invalid" ;
VAL_ 946 RLCR_6_Le4ObjYDirV 16383 "Invalid" ;
VAL_ 946 RLCR_6_Le4ObjXDirV 16383 "Invalid" ;
VAL_ 946 RLCR_6_Le4ObjMtnChartc 3 " Moving" 2 " StatyFromMoving" 1 " Staty" 0 "  Invalid" ;
VAL_ 946 RLCR_6_Le4ObjTyp 3 " Not Used" 2 " Two wheels vehicle " 1 " Four wheels vehicle " 0 "  Invalid" ;
VAL_ 946 RLCR_6_Le4ObjConf 1 " Conf" 0 " Un conf" ;
VAL_ 946 RLCR_6_Le4ObjNrOffocst 31 "Invalid" ;
VAL_ 946 RLCR_6_Le4ObjTrackSt 3 " Coasted" 2 " New" 1 " Updated" 0 " Invalid" ;
VAL_ 946 RLCR_6_Le4ObjCoordXDstStdDe 255 "Invalid" ;
VAL_ 946 RLCR_6_Le4ObjCoordYDstStdDe 255 "Invalid" ;
VAL_ 946 RLCR_6_Le4ObjXDirVStdDe 63 "Invalid" ;
VAL_ 946 RLCR_6_Le4ObjYDirVStdDe 63 "Invalid" ;
VAL_ 948 RLCR_7_Le5ObjBoxLen 511 "Invalid" ;
VAL_ 948 RLCR_7_Le5ObjBoxWidth 511 "Invalid" ;
VAL_ 948 RLCR_7_Le5HdTo 4095 "Invalid" ;
VAL_ 948 RLCR_7_Le5ObjID 255 "Invalid" ;
VAL_ 948 RLCR_7_Le5ObjCoordY 8191 "Invalid" ;
VAL_ 948 RLCR_7_Le5ObjCoordX 8191 "Invalid" ;
VAL_ 948 RLCR_7_Le5ObjXDirAV 255 "Invalid" ;
VAL_ 948 RLCR_7_Le5ObjYDirV 16383 "Invalid" ;
VAL_ 948 RLCR_7_Le5ObjXDirV 16383 "Invalid" ;
VAL_ 948 RLCR_7_Le5ObjMtnChartc 3 " Moving" 2 " StatyFromMoving" 1 " Staty" 0 "  Invalid" ;
VAL_ 948 RLCR_7_Le5ObjTyp 3 " Not Used" 2 " Two wheels vehicle " 1 " Four wheels vehicle " 0 "  Invalid" ;
VAL_ 948 RLCR_7_Le5ObjConf 1 " Conf" 0 " Un conf" ;
VAL_ 948 RLCR_7_Le5ObjNrOffocst 31 "Invalid" ;
VAL_ 948 RLCR_7_Le5ObjTrackSt 3 " Coasted" 2 " New" 1 " Updated" 0 " Invalid" ;
VAL_ 948 RLCR_7_Le5ObjCoordXDstStdDe 255 "Invalid" ;
VAL_ 948 RLCR_7_Le5ObjCoordYDstStdDe 255 "Invalid" ;
VAL_ 948 RLCR_7_Le5ObjXDirVStdDe 63 "Invalid" ;
VAL_ 948 RLCR_7_Le5ObjYDirVStdDe 63 "Invalid" ;
VAL_ 955 RLCR_9_ObjVldFlg 1 " InValid" 0 " Valid" ;
VAL_ 955 RLCR_9_LgtDst 8191 "Invalid" ;
VAL_ 955 RLCR_9_LgtRelV 16383 "Invalid" ;
VAL_ 1203 RRCR_1_SysSt 3 " System Error" 2 " Temporary Error" 1 " On" 0 " Off" ;
VAL_ 1203 RRCR_1_BlkSts 1 " Blockage" 0 " Not Blockage" ;
VAL_ 959 RRCR_2_Ri1ObjBoxLen 511 "Invalid" ;
VAL_ 959 RRCR_2_Ri1ObjBoxWidth 511 "Invalid" ;
VAL_ 959 RRCR_2_Ri1HdTo 4095 "Invalid" ;
VAL_ 959 RRCR_2_Ri1ObjID 255 "Invalid" ;
VAL_ 959 RRCR_2_Ri1ObjCoordY 8191 "Invalid" ;
VAL_ 959 RRCR_2_Ri1ObjCoordX 8191 "Invalid" ;
VAL_ 959 RRCR_2_Ri1ObjXDirAV 255 "Invalid" ;
VAL_ 959 RRCR_2_Ri1ObjYDirV 16383 "Invalid" ;
VAL_ 959 RRCR_2_Ri1ObjXDirV 16383 "Invalid" ;
VAL_ 959 RRCR_2_Ri1ObjMtnChartc 3 " Moving" 2 " StatyFromMoving" 1 " Staty" 0 "  Invalid" ;
VAL_ 959 RRCR_2_Ri1ObjTyp 3 " Not Used" 2 " Two wheels vehicle " 1 " Four wheels vehicle " 0 "  Invalid" ;
VAL_ 959 RRCR_2_Ri1ObjConf 1 " Conf" 0 " Un conf" ;
VAL_ 959 RRCR_2_Ri1ObjNrOffocst 31 "Invalid" ;
VAL_ 959 RRCR_2_Ri1ObjTrackSt 3 " Coasted" 2 " New" 1 " Updated" 0 " Invalid" ;
VAL_ 959 RRCR_2_Ri1ObjCoordXDstStdDe 255 "Invalid" ;
VAL_ 959 RRCR_2_Ri1ObjCoordYDstStdDe 255 "Invalid" ;
VAL_ 959 RRCR_2_Ri1ObjXDirVStdDe 63 "Invalid" ;
VAL_ 959 RRCR_2_Ri1ObjYDirVStdDe 63 "Invalid" ;
